VERSION "dbc-export 1 2026.26.6.5"

NS_ :

BS_:

BU_: ADSP APB APP APS APSB BB BMS CC CMP CMPD CP DAS DI DIF DIR DPB EPAS3P EPAS3S EPASTP EPASTS EPBL EPBR ESP EVSE FC GTW HCML HCMR HVP IBST ICR IDB LS OCS1P ODIN PARK PCS PCS2 PLG PM PMF PMR PNCD PTC RADC RCM RCM2 RCM3 RCU SCCM SCM SCS SDCR TAS TCU TCU2 TPMS TRCM UDS UI UIS UMC USM V2G VC VCBATT VCBATT0 VCBATT1 VCBATT2 VCCC VCFRONT VCFRONT1 VCFRONT2 VCLEFT VCRIGHT VCSEAT2L VCSEAT2R VCSEC VEH

BO_ 1482 APSB_alertLog: 8 APSB
 SG_ APSB_alertID M : 0|14@1+ (1,0) [0|16383] "" Vector__XXX
 SG_ APSB_alertSource : 14|1@1+ (1,0) [0|1] "" Vector__XXX
 SG_ APSB_alertState : 15|1@1+ (1,0) [0|1] "" Vector__XXX
 SG_ APSB_sw010_a04calibNotDone m10 : 16|1@1+ (1,0) [0|1] "" Vector__XXX
 SG_ APSB_sw010_a05calibReqd m10 : 17|1@1+ (1,0) [0|1] "" Vector__XXX
 SG_ APSB_sw010_a06calibNotOK m10 : 18|1@1+ (1,0) [0|1] "" Vector__XXX
 SG_ APSB_sw010_a08PlantMode m10 : 19|1@1+ (1,0) [0|1] "" Vector__XXX
 SG_ APSB_sw010_HorizontalMisalignmen m10 : 20|16@1+ (0.00137332,-45) [-45|45.0005262] "deg" Vector__XXX
 SG_ APSB_sw010_VerticalMisalignment m10 : 36|10@1+ (0.087977,-45) [-45|45.000471] "deg" Vector__XXX
 SG_ APSB_sw010_unusedBits m10 : 46|2@1+ (1,0) [0|3] "" Vector__XXX
 SG_ APSB_sw010_VmaPlausibility m10 : 48|16@1+ (1.52587890625e-05,0) [0|0.999984741211] "FIXME" Vector__XXX
 SG_ APSB_sw019_taskId m19 : 16|8@1+ (1,0) [0|255] "" Vector__XXX
 SG_ APSB_sw019_numFreeBytes m19 : 24|8@1+ (1,-191) [-191|64] "# of bytes" Vector__XXX
 SG_ APSB_sw019_timeStamp m19 : 32|32@1+ (1,0) [0|4294967295] "ms" Vector__XXX
 SG_ APSB_sw020_unusedW0 m20 : 16|16@1+ (1,0) [0|65535] "" Vector__XXX
 SG_ APSB_sw020_unusedW1 m20 : 32|16@1+ (1,0) [0|65535] "" Vector__XXX
 SG_ APSB_sw020_unusedW2 m20 : 48|16@1+ (1,0) [0|65535] "" Vector__XXX
 SG_ APSB_sw021_tempSensorId m21 : 16|8@1+ (1,0) [0|255] "" Vector__XXX
 SG_ APSB_sw021_minThreshold m21 : 24|8@1- (1,0) [-128|127] "degC" Vector__XXX
 SG_ APSB_sw021_maxThreshold m21 : 32|8@1- (1,0) [-128|127] "degC" Vector__XXX
 SG_ APSB_sw021_currentTemperature m21 : 40|8@1- (1,0) [-128|127] "degC" Vector__XXX
 SG_ APSB_sw021_unusedWord m21 : 48|16@1+ (1,0) [0|65535] "" Vector__XXX
 SG_ APSB_sw024_Task_ID m24 : 16|4@1+ (1,0) [0|15] "" Vector__XXX
 SG_ APSB_sw024_numVirtualLaneVeh m24 : 20|4@1+ (1,0) [0|15] "" Vector__XXX
 SG_ APSB_sw024_currentVehicleApp m24 : 24|8@1+ (1,0) [0|255] "" Vector__XXX
 SG_ APSB_sw024_taskProgramCounter m24 : 32|32@1+ (1,0) [0|4294967295] "" Vector__XXX
 SG_ APSB_sw027_JTAG_Reset m27 : 16|1@1+ (1,0) [0|1] "" Vector__XXX
 SG_ APSB_sw027_Core_Reset m27 : 17|1@1+ (1,0) [0|1] "" Vector__XXX
 SG_ APSB_sw027_Unused_Bit_0 m27 : 18|1@1+ (1,0) [0|1] "" Vector__XXX
 SG_ APSB_sw027_CPU_Checkstop_Error m27 : 19|1@1+ (1,0) [0|1] "" Vector__XXX
 SG_ APSB_sw027_PLL_0_Failure m27 : 20|1@1+ (1,0) [0|1] "" Vector__XXX
 SG_ APSB_sw027_Clock_Monitor_0_Low m27 : 21|1@1+ (1,0) [0|1] "" Vector__XXX
 SG_ APSB_sw027_Clock_Monitor_0_Off m27 : 22|1@1+ (1,0) [0|1] "" Vector__XXX
 SG_ APSB_sw027_LVD_4v5 m27 : 23|1@1+ (1,0) [0|1] "" Vector__XXX
 SG_ APSB_sw027_Flash_Fatal_Error m27 : 24|1@1+ (1,0) [0|1] "" Vector__XXX
 SG_ APSB_sw027_PLL_1_Failure m27 : 25|1@1+ (1,0) [0|1] "" Vector__XXX
 SG_ APSB_sw027_Unused_Bit_1 m27 : 26|1@1+ (1,0) [0|1] "" Vector__XXX
 SG_ APSB_sw027_f_PLL_1_Off m27 : 27|1@1+ (1,0) [0|1] "" Vector__XXX
 SG_ APSB_sw027_Unused_Nibble m27 : 28|4@1+ (1,0) [0|15] "" Vector__XXX
 SG_ APSB_sw027_LVD_1v2 m27 : 32|1@1+ (1,0) [0|1] "" Vector__XXX
 SG_ APSB_sw027_Unused_Bit_2 m27 : 33|1@1+ (1,0) [0|1] "" Vector__XXX
 SG_ APSB_sw027_Watchdog m27 : 34|1@1+ (1,0) [0|1] "" Vector__XXX
 SG_ APSB_sw027_Unused_Bit_3 m27 : 35|1@1+ (1,0) [0|1] "" Vector__XXX
 SG_ APSB_sw027_LVD_2v7_VREG m27 : 36|1@1+ (1,0) [0|1] "" Vector__XXX
 SG_ APSB_sw027_LVD_2v7_Flash m27 : 37|1@1+ (1,0) [0|1] "" Vector__XXX
 SG_ APSB_sw027_LVD_2v7_IO m27 : 38|1@1+ (1,0) [0|1] "" Vector__XXX
 SG_ APSB_sw027_Unused_Bit_4 m27 : 39|1@1+ (1,0) [0|1] "" Vector__XXX
 SG_ APSB_sw027_Unused_Byte m27 : 40|8@1+ (1,0) [0|255] "" Vector__XXX
 SG_ APSB_sw027_ESR0 m27 : 48|1@1+ (1,0) [0|1] "" Vector__XXX
 SG_ APSB_sw027_ESR1 m27 : 49|1@1+ (1,0) [0|1] "" Vector__XXX
 SG_ APSB_sw027_SW m27 : 50|1@1+ (1,0) [0|1] "" Vector__XXX
 SG_ APSB_sw027_STM0 m27 : 51|1@1+ (1,0) [0|1] "" Vector__XXX
 SG_ APSB_sw027_STM1 m27 : 52|1@1+ (1,0) [0|1] "" Vector__XXX
 SG_ APSB_sw027_STM2 m27 : 53|1@1+ (1,0) [0|1] "" Vector__XXX
 SG_ APSB_sw027_CBS_SYSTEM m27 : 54|1@1+ (1,0) [0|1] "" Vector__XXX
 SG_ APSB_sw027_CBS_DEBUG m27 : 55|1@1+ (1,0) [0|1] "" Vector__XXX
 SG_ APSB_sw027_CBS_APP m27 : 56|1@1+ (1,0) [0|1] "" Vector__XXX
 SG_ APSB_sw027_EVR13 m27 : 57|1@1+ (1,0) [0|1] "" Vector__XXX
 SG_ APSB_sw027_EVR33 m27 : 58|1@1+ (1,0) [0|1] "" Vector__XXX
 SG_ APSB_sw027_SWD m27 : 59|1@1+ (1,0) [0|1] "" Vector__XXX
 SG_ APSB_sw027_STDBY_WDG m27 : 60|1@1+ (1,0) [0|1] "" Vector__XXX
 SG_ APSB_sw027_PORST m27 : 61|1@1+ (1,0) [0|1] "" Vector__XXX
 SG_ APSB_sw027_Unused_word m27 : 62|2@1+ (1,0) [0|3] "" Vector__XXX
 SG_ APSB_sw030_heaterState m30 : 16|8@1+ (1,0) [0|255] "" Vector__XXX
 SG_ APSB_sw030_unusedByte m30 : 24|8@1+ (1,0) [0|255] "" Vector__XXX
 SG_ APSB_sw030_unusedW0 m30 : 32|16@1+ (1,0) [0|65535] "" Vector__XXX
 SG_ APSB_sw030_unusedW1 m30 : 48|16@1+ (1,0) [0|65535] "" Vector__XXX
 SG_ APSB_sw033_carConfig m33 : 16|1@1+ (1,0) [0|1] "" Vector__XXX
 SG_ APSB_sw033_chNm m33 : 17|1@1+ (1,0) [0|1] "" Vector__XXX
 SG_ APSB_sw033_vin m33 : 18|1@1+ (1,0) [0|1] "" Vector__XXX
 SG_ APSB_sw033_carState m33 : 19|1@1+ (1,0) [0|1] "" Vector__XXX
 SG_ APSB_sw034_sccmMia m34 : 16|8@1+ (1,0) [0|255] "" Vector__XXX
 SG_ APSB_sw034_unusedByte m34 : 24|8@1+ (1,0) [0|255] "" Vector__XXX
 SG_ APSB_sw034_unusedW0 m34 : 32|16@1+ (1,0) [0|65535] "" Vector__XXX
 SG_ APSB_sw034_unusedW1 m34 : 48|16@1+ (1,0) [0|65535] "" Vector__XXX
 SG_ APSB_sw035_wheelSpeeds m35 : 16|1@1+ (1,0) [0|1] "" Vector__XXX
 SG_ APSB_sw035_status m35 : 17|1@1+ (1,0) [0|1] "" Vector__XXX
 SG_ APSB_sw035_wheelRotation m35 : 18|1@1+ (1,0) [0|1] "" Vector__XXX
 SG_ APSB_sw035_redundantBrakingStatu m35 : 19|1@1+ (1,0) [0|1] "" Vector__XXX
 SG_ APSB_sw036_bdyMia m36 : 16|8@1+ (1,0) [0|255] "" Vector__XXX
 SG_ APSB_sw036_unusedByte m36 : 24|8@1+ (1,0) [0|255] "" Vector__XXX
 SG_ APSB_sw036_unusedW0 m36 : 32|16@1+ (1,0) [0|65535] "" Vector__XXX
 SG_ APSB_sw036_unusedW1 m36 : 48|16@1+ (1,0) [0|65535] "" Vector__XXX
 SG_ APSB_sw039_sdm_rcm_Mia m39 : 16|8@1+ (1,0) [0|255] "" Vector__XXX
 SG_ APSB_sw039_unusedByte m39 : 24|8@1+ (1,0) [0|255] "" Vector__XXX
 SG_ APSB_sw039_unusedW0 m39 : 32|16@1+ (1,0) [0|65535] "" Vector__XXX
 SG_ APSB_sw039_unusedW1 m39 : 48|16@1+ (1,0) [0|65535] "" Vector__XXX
 SG_ APSB_sw045_radMia m45 : 16|8@1+ (1,0) [0|255] "" Vector__XXX
 SG_ APSB_sw045_unusedByte m45 : 24|8@1+ (1,0) [0|255] "" Vector__XXX
 SG_ APSB_sw045_unusedW0 m45 : 32|16@1+ (1,0) [0|65535] "" Vector__XXX
 SG_ APSB_sw045_unusedW1 m45 : 48|16@1+ (1,0) [0|65535] "" Vector__XXX
 SG_ APSB_sw048_swAssert m48 : 16|1@1+ (1,0) [0|1] "" Vector__XXX
 SG_ APSB_sw048_thermalIssue m48 : 17|1@1+ (1,0) [0|1] "" Vector__XXX
 SG_ APSB_sw048_powerIssue m48 : 18|1@1+ (1,0) [0|1] "" Vector__XXX
 SG_ APSB_sw048_stackOverflow m48 : 19|1@1+ (1,0) [0|1] "" Vector__XXX
 SG_ APSB_sw048_checkStop m48 : 20|1@1+ (1,0) [0|1] "" Vector__XXX
 SG_ APSB_sw048_ecuWatchdog m48 : 21|1@1+ (1,0) [0|1] "" Vector__XXX
 SG_ APSB_sw048_ecuReset m48 : 22|1@1+ (1,0) [0|1] "" Vector__XXX
 SG_ APSB_sw048_radcVersionMismatch m48 : 23|1@1+ (1,0) [0|1] "" Vector__XXX
 SG_ APSB_sw048_radcCalibration m48 : 24|1@1+ (1,0) [0|1] "" Vector__XXX
 SG_ APSB_sw048_radcMia m48 : 25|1@1+ (1,0) [0|1] "" Vector__XXX
 SG_ APSB_sw048_eyeQVersionMismatch m48 : 26|1@1+ (1,0) [0|1] "" Vector__XXX
 SG_ APSB_sw048_camIssue m48 : 27|1@1+ (1,0) [0|1] "" Vector__XXX
 SG_ APSB_sw048_parkerIssue m48 : 28|1@1+ (1,0) [0|1] "" Vector__XXX
 SG_ APSB_sw048_prolongedUiMia m48 : 29|1@1+ (1,0) [0|1] "" Vector__XXX
 SG_ APSB_sw048_uiMiaAtBootup m48 : 30|1@1+ (1,0) [0|1] "" Vector__XXX
 SG_ APSB_sw051_a01ecuInternalPerf m51 : 16|1@1+ (1,0) [0|1] "" Vector__XXX
 SG_ APSB_sw051_a02flashPerformance m51 : 17|1@1+ (1,0) [0|1] "" Vector__XXX
 SG_ APSB_sw051_a03vBatHigh m51 : 18|1@1+ (1,0) [0|1] "" Vector__XXX
 SG_ APSB_sw051_a09configMismatch m51 : 19|1@1+ (1,0) [0|1] "" Vector__XXX
 SG_ APSB_sw051_a52radomeHtrInop m51 : 20|1@1+ (1,0) [0|1] "" Vector__XXX
 SG_ APSB_sw051_unused m51 : 21|3@1+ (1,0) [0|7] "" Vector__XXX
 SG_ APSB_sw051_SCUTemperature m51 : 24|8@1- (1,0) [-128|127] "" Vector__XXX
 SG_ APSB_sw051_HWFail m51 : 32|1@1+ (1,0) [0|1] "" Vector__XXX
 SG_ APSB_sw051_SGUFail m51 : 33|1@1+ (1,0) [0|1] "" Vector__XXX
 SG_ APSB_sw051_unusedBits m51 : 34|6@1+ (1,0) [0|63] "" Vector__XXX
 SG_ APSB_sw051_unusedB0 m51 : 40|8@1+ (1,0) [0|255] "" Vector__XXX
 SG_ APSB_sw051_unusedW1 m51 : 48|16@1+ (1,0) [0|65535] "" Vector__XXX
 SG_ APSB_sw052_a07sensorBlinded m52 : 16|1@1+ (1,0) [0|1] "" Vector__XXX
 SG_ APSB_sw052_sensorDirty m52 : 17|1@1+ (1,0) [0|1] "" Vector__XXX
 SG_ APSB_sw052_HWFail m52 : 18|1@1+ (1,0) [0|1] "" Vector__XXX
 SG_ APSB_sw052_overTemperature m52 : 19|1@1+ (1,0) [0|1] "" Vector__XXX
 SG_ APSB_sw052_underTemperature m52 : 20|1@1+ (1,0) [0|1] "" Vector__XXX
 SG_ APSB_sw052_chirpError m52 : 21|1@1+ (1,0) [0|1] "" Vector__XXX
 SG_ APSB_sw052_rspError m52 : 22|1@1+ (1,0) [0|1] "" Vector__XXX
 SG_ APSB_sw052_sensorBlocked m52 : 23|1@1+ (1,0) [0|1] "" Vector__XXX
 SG_ APSB_sw053_a10canBusOff m53 : 16|1@1+ (1,0) [0|1] "" Vector__XXX
 SG_ APSB_sw053_a11bdyMIA m53 : 17|1@1+ (1,0) [0|1] "" Vector__XXX
 SG_ APSB_sw053_a12espMIA m53 : 18|1@1+ (1,0) [0|1] "" Vector__XXX
 SG_ APSB_sw053_a13gtwMIA m53 : 19|1@1+ (1,0) [0|1] "" Vector__XXX
 SG_ APSB_sw053_a14sccmMIA m53 : 20|1@1+ (1,0) [0|1] "" Vector__XXX
 SG_ APSB_sw053_a15adasMIA m53 : 21|1@1+ (1,0) [0|1] "" Vector__XXX
 SG_ APSB_sw053_a16bdyInvalidCount m53 : 22|1@1+ (1,0) [0|1] "" Vector__XXX
 SG_ APSB_sw053_a17adasInvalidCount m53 : 23|1@1+ (1,0) [0|1] "" Vector__XXX
 SG_ APSB_sw053_a18espInvalidCount m53 : 24|1@1+ (1,0) [0|1] "" Vector__XXX
 SG_ APSB_sw053_a19sccmInvalidCount m53 : 25|1@1+ (1,0) [0|1] "" Vector__XXX
 SG_ APSB_sw053_a20bdyInvalidChkSm m53 : 26|1@1+ (1,0) [0|1] "" Vector__XXX
 SG_ APSB_sw053_a21espInvalidChkSm m53 : 27|1@1+ (1,0) [0|1] "" Vector__XXX
 SG_ APSB_sw053_a22sccmInvalidChkSm m53 : 28|1@1+ (1,0) [0|1] "" Vector__XXX
 SG_ APSB_sw053_a23sccmInvalidChkSm m53 : 29|1@1+ (1,0) [0|1] "" Vector__XXX
 SG_ APSB_sw053_a24absValidity m53 : 30|1@1+ (1,0) [0|1] "" Vector__XXX
 SG_ APSB_sw053_a25ambTValidity m53 : 31|1@1+ (1,0) [0|1] "" Vector__XXX
 SG_ APSB_sw053_a26brakeValidity m53 : 32|1@1+ (1,0) [0|1] "" Vector__XXX
 SG_ APSB_sw053_a27CntryCdValidity m53 : 33|1@1+ (1,0) [0|1] "" Vector__XXX
 SG_ APSB_sw053_a28espValidity m53 : 34|1@1+ (1,0) [0|1] "" Vector__XXX
 SG_ APSB_sw053_a29longAccOffValidity m53 : 35|1@1+ (1,0) [0|1] "" Vector__XXX
 SG_ APSB_sw053_a30longAccValidity m53 : 36|1@1+ (1,0) [0|1] "" Vector__XXX
 SG_ APSB_sw053_a31odoValidity m53 : 37|1@1+ (1,0) [0|1] "" Vector__XXX
 SG_ APSB_sw053_a32gearValidity m53 : 38|1@1+ (1,0) [0|1] "" Vector__XXX
 SG_ APSB_sw053_a33steerAngValidity m53 : 39|1@1+ (1,0) [0|1] "" Vector__XXX
 SG_ APSB_sw053_a34steerAngSpdValidit m53 : 40|1@1+ (1,0) [0|1] "" Vector__XXX
 SG_ APSB_sw053_a35indctrValidity m53 : 41|1@1+ (1,0) [0|1] "" Vector__XXX
 SG_ APSB_sw053_a36vehStndStllValidty m53 : 42|1@1+ (1,0) [0|1] "" Vector__XXX
 SG_ APSB_sw053_a37vinValidity m53 : 43|1@1+ (1,0) [0|1] "" Vector__XXX
 SG_ APSB_sw053_a38whlRotValidity m53 : 44|1@1+ (1,0) [0|1] "" Vector__XXX
 SG_ APSB_sw053_a39whlSpdValidity m53 : 45|1@1+ (1,0) [0|1] "" Vector__XXX
 SG_ APSB_sw053_a40whlStndStllValidty m53 : 46|1@1+ (1,0) [0|1] "" Vector__XXX
 SG_ APSB_sw053_a41wiperValidity m53 : 47|1@1+ (1,0) [0|1] "" Vector__XXX
 SG_ APSB_sw053_a42xwdValidity m53 : 48|1@1+ (1,0) [0|1] "" Vector__XXX
 SG_ APSB_sw053_a43yawOffValidity m53 : 49|1@1+ (1,0) [0|1] "" Vector__XXX
 SG_ APSB_sw053_a44yawValidity m53 : 50|1@1+ (1,0) [0|1] "" Vector__XXX
 SG_ APSB_sw053_a48steerAngOffSanity m53 : 51|1@1+ (1,0) [0|1] "" Vector__XXX
 SG_ APSB_sw053_a49tireSizeSanity m53 : 52|1@1+ (1,0) [0|1] "" Vector__XXX
 SG_ APSB_sw053_a50velocitySanity m53 : 53|1@1+ (1,0) [0|1] "" Vector__XXX
 SG_ APSB_sw053_a51yawSanity m53 : 54|1@1+ (1,0) [0|1] "" Vector__XXX
 SG_ APSB_sw053_a53espmodValidity m53 : 55|1@1+ (1,0) [0|1] "" Vector__XXX
 SG_ APSB_sw053_a54gtwmodValidity m53 : 56|1@1+ (1,0) [0|1] "" Vector__XXX
 SG_ APSB_sw053_a55stwmodValidity m53 : 57|1@1+ (1,0) [0|1] "" Vector__XXX
 SG_ APSB_sw053_a56bcmodValidity m53 : 58|1@1+ (1,0) [0|1] "" Vector__XXX
 SG_ APSB_sw053_a57dimodValidity m53 : 59|1@1+ (1,0) [0|1] "" Vector__XXX
 SG_ APSB_sw053_a59drmiInvalidChkSm m53 : 60|1@1+ (1,0) [0|1] "" Vector__XXX
 SG_ APSB_sw053_a60drmiInvalidCount m53 : 61|1@1+ (1,0) [0|1] "" Vector__XXX
 SG_ APSB_sw053_a61radPositionMismatc m53 : 62|1@1+ (1,0) [0|1] "" Vector__XXX
 SG_ APSB_sw053_a62strRackMismatch m53 : 63|1@1+ (1,0) [0|1] "" Vector__XXX
 SG_ APSB_sw055_detectedRadcVersion m55 : 16|32@1+ (1,0) [0|4294967295] "" Vector__XXX
 SG_ APSB_sw055_expectedCrcLsw m55 : 48|16@1+ (1,0) [0|65535] "" Vector__XXX
 SG_ APSB_sw056_diMia m56 : 16|8@1+ (1,0) [0|255] "" Vector__XXX
 SG_ APSB_sw056_unusedByte m56 : 24|8@1+ (1,0) [0|255] "" Vector__XXX
 SG_ APSB_sw056_unusedW0 m56 : 32|16@1+ (1,0) [0|65535] "" Vector__XXX
 SG_ APSB_sw056_unusedW1 m56 : 48|16@1+ (1,0) [0|65535] "" Vector__XXX
 SG_ APSB_sw058_epbMia m58 : 16|8@1+ (1,0) [0|255] "" Vector__XXX
 SG_ APSB_sw058_unusedByte m58 : 24|8@1+ (1,0) [0|255] "" Vector__XXX
 SG_ APSB_sw058_unusedW0 m58 : 32|16@1+ (1,0) [0|65535] "" Vector__XXX
 SG_ APSB_sw058_unusedW1 m58 : 48|16@1+ (1,0) [0|65535] "" Vector__XXX
 SG_ APSB_sw059_sdiFront m59 : 16|1@1+ (1,0) [0|1] "" Vector__XXX
 SG_ APSB_sw059_sdiRear m59 : 17|1@1+ (1,0) [0|1] "" Vector__XXX
 SG_ APSB_sw059_status m59 : 18|1@1+ (1,0) [0|1] "" Vector__XXX
 SG_ APSB_sw059_sensorStatusFront m59 : 19|1@1+ (1,0) [0|1] "" Vector__XXX
 SG_ APSB_sw059_pasFrontMiddle m59 : 20|1@1+ (1,0) [0|1] "" Vector__XXX
 SG_ APSB_sw059_sensorStatusRear m59 : 21|1@1+ (1,0) [0|1] "" Vector__XXX
 SG_ APSB_sw059_pasRearMiddle m59 : 22|1@1+ (1,0) [0|1] "" Vector__XXX
 SG_ APSB_sw059_pscStatus m59 : 23|1@1+ (1,0) [0|1] "" Vector__XXX
 SG_ APSB_sw059_pscVehSlot m59 : 24|1@1+ (1,0) [0|1] "" Vector__XXX
 SG_ APSB_sw059_status2 m59 : 25|1@1+ (1,0) [0|1] "" Vector__XXX
 SG_ APSB_sw059_oloDict m59 : 26|1@1+ (1,0) [0|1] "" Vector__XXX
 SG_ APSB_sw059_oocStatus m59 : 27|1@1+ (1,0) [0|1] "" Vector__XXX
 SG_ APSB_sw061_states m61 : 16|1@1+ (1,0) [0|1] "" Vector__XXX
 SG_ APSB_sw063_expectedMajorVer m63 : 16|8@1+ (1,0) [0|255] "" Vector__XXX
 SG_ APSB_sw063_detectedMajorVer m63 : 24|8@1+ (1,0) [0|255] "" Vector__XXX
 SG_ APSB_sw063_expectedMinorVer m63 : 32|8@1+ (1,0) [0|255] "" Vector__XXX
 SG_ APSB_sw063_detectedMinorVer m63 : 40|8@1+ (1,0) [0|255] "" Vector__XXX
 SG_ APSB_sw063_expectedSubMinorVer m63 : 48|8@1+ (1,0) [0|255] "" Vector__XXX
 SG_ APSB_sw063_detectedSubMinorVer m63 : 56|8@1+ (1,0) [0|255] "" Vector__XXX
 SG_ APSB_sw064_sysStatus m64 : 16|1@1+ (1,0) [0|1] "" Vector__XXX
 SG_ APSB_sw064_status m64 : 17|1@1+ (1,0) [0|1] "" Vector__XXX
 SG_ APSB_sw070_currTireFitment m70 : 16|3@1+ (1,0) [0|7] "" Vector__XXX
 SG_ APSB_sw070_lastTireFitment m70 : 19|3@1+ (1,0) [0|7] "" Vector__XXX
 SG_ APSB_sw070_diGear m70 : 24|3@1+ (1,0) [0|7] "" Vector__XXX
 SG_ APSB_sw070_driveRail m70 : 27|1@1+ (1,0) [0|1] "" Vector__XXX
 SG_ APSB_sw070_accRail m70 : 28|1@1+ (1,0) [0|1] "" Vector__XXX
 SG_ APSB_sw070_temperature m70 : 32|8@1+ (0.5,-40) [-40|87.5] "C" Vector__XXX
 SG_ APSB_sw070_currentSpeed m70 : 40|12@1+ (0.1,-204.7) [-204.7|204.8] "mph" Vector__XXX
 SG_ APSB_sw071_selfParkType m71 : 16|4@1+ (1,0) [0|15] "" Vector__XXX
 SG_ APSB_sw071_endPosX m71 : 20|10@1+ (0.05,-25.6) [-25.6|25.55] "m" Vector__XXX
 SG_ APSB_sw071_endPosY m71 : 30|10@1+ (0.05,-25.6) [-25.6|25.55] "m" Vector__XXX
 SG_ APSB_sw071_roadClass m71 : 40|3@1+ (1,0) [0|7] "" Vector__XXX
 SG_ APSB_sw071_driverPresent m71 : 43|1@1+ (1,0) [0|1] "" Vector__XXX
 SG_ APSB_sw071_airSuspension m71 : 44|3@1+ (1,0) [0|7] "" Vector__XXX
 SG_ APSB_sw071_temperature m71 : 48|8@1+ (0.5,-40) [-40|87.5] "C" Vector__XXX
 SG_ APSB_sw071_activationType m71 : 56|2@1+ (1,0) [0|3] "" Vector__XXX
 SG_ APSB_sw072_vehicleX m72 : 16|10@1+ (0.05,-25.6) [-25.6|25.55] "m" Vector__XXX
 SG_ APSB_sw072_vehicleY m72 : 26|10@1+ (0.05,-25.6) [-25.6|25.55] "m" Vector__XXX
 SG_ APSB_sw072_vehicleHeading m72 : 36|10@1+ (0.005,-2.56) [-2.56|2.555] "rad" Vector__XXX
 SG_ APSB_sw072_endDistance m72 : 48|8@1+ (1,0) [0|255] "cm" Vector__XXX
 SG_ APSB_sw072_guidanceComplete m72 : 56|1@1+ (1,0) [0|1] "" Vector__XXX
 SG_ APSB_sw072_guidanceRunaway m72 : 57|1@1+ (1,0) [0|1] "" Vector__XXX
 SG_ APSB_sw072_guidanceTimer m72 : 58|1@1+ (1,0) [0|1] "" Vector__XXX
 SG_ APSB_sw072_handlePress m72 : 59|1@1+ (1,0) [0|1] "" Vector__XXX
 SG_ APSB_sw072_keyfobPress m72 : 60|1@1+ (1,0) [0|1] "" Vector__XXX
 SG_ APSB_sw072_garageOpened m72 : 61|1@1+ (1,0) [0|1] "" Vector__XXX
 SG_ APSB_sw072_userTimeout m72 : 62|1@1+ (1,0) [0|1] "" Vector__XXX
 SG_ APSB_sw075_scMia m75 : 16|8@1+ (1,0) [0|255] "" Vector__XXX
 SG_ APSB_sw075_unusedByte m75 : 24|8@1+ (1,0) [0|255] "" Vector__XXX
 SG_ APSB_sw075_unusedW0 m75 : 32|16@1+ (1,0) [0|65535] "" Vector__XXX
 SG_ APSB_sw075_unusedW1 m75 : 48|16@1+ (1,0) [0|65535] "" Vector__XXX
 SG_ APSB_sw077_oocDistance m77 : 16|9@1+ (1,0) [0|511] "cm" Vector__XXX
 SG_ APSB_sw077_oocConfidence m77 : 25|7@1+ (1,0) [0|127] "%" Vector__XXX
 SG_ APSB_sw077_oocCollisionSide m77 : 32|3@1+ (1,0) [0|7] "" Vector__XXX
 SG_ APSB_sw077_oocHeight m77 : 35|2@1+ (1,0) [0|3] "" Vector__XXX
 SG_ APSB_sw077_vehicleSpeed m77 : 37|10@1+ (0.05,-25) [-25|26.15] "MPH" Vector__XXX
 SG_ APSB_sw077_oocUntrackedTime m77 : 48|6@1+ (0.1,0) [0|6.3] "s" Vector__XXX
 SG_ APSB_sw077_oocOffCourseDist_cm m77 : 54|10@1- (1,0) [-512|511] "" Vector__XXX
 SG_ APSB_sw081_radarDistance m81 : 16|8@1+ (0.0625,0) [0|15.9375] "m" Vector__XXX
 SG_ APSB_sw081_radarTTC m81 : 24|8@1+ (0.02,0) [0|5.1] "seconds" Vector__XXX
 SG_ APSB_sw081_cameraDistance m81 : 32|8@1+ (0.0625,0) [0|15.9375] "m" Vector__XXX
 SG_ APSB_sw081_cameraTTC m81 : 40|8@1+ (0.02,0) [0|5.1] "seconds" Vector__XXX
 SG_ APSB_sw081_pedalPosition m81 : 48|7@1+ (1,0) [0|127] "%" Vector__XXX
 SG_ APSB_sw129_currentVoltage m129 : 16|14@1+ (1,0) [0|16383] "mV" Vector__XXX
 SG_ APSB_sw129_maxThreshold m129 : 30|13@1+ (1,50) [50|8241] "mV" Vector__XXX
 SG_ APSB_sw129_minThreshold m129 : 43|13@1+ (1,0) [0|8191] "mV" Vector__XXX
 SG_ APSB_sw129_powerSequnceError m129 : 56|1@1+ (1,0) [0|1] "" Vector__XXX
 SG_ APSB_sw129_railControl m129 : 57|1@1+ (1,0) [0|1] "" Vector__XXX
 SG_ APSB_sw129_railID m129 : 58|6@1+ (1,0) [0|63] "" Vector__XXX
 SG_ APSB_sw130_currentTemperature m130 : 16|8@1- (1,0) [-128|127] "degC" Vector__XXX
 SG_ APSB_sw130_maxThreshold m130 : 24|8@1- (1,0) [-128|127] "degC" Vector__XXX
 SG_ APSB_sw130_minThreshold m130 : 32|8@1- (1,0) [-128|127] "degC" Vector__XXX
 SG_ APSB_sw130_tempSensorId m130 : 40|6@1+ (1,0) [0|63] "" Vector__XXX
 SG_ APSB_sw130_shouldForceApPowerOn m130 : 46|1@1+ (1,0) [0|1] "" Vector__XXX
 SG_ APSB_sw130_shouldBlockOkToPowerA m130 : 47|1@1+ (1,0) [0|1] "" Vector__XXX
 SG_ APSB_sw132_mismatchType m132 : 16|1@1+ (1,0) [0|1] "" Vector__XXX
 SG_ APSB_sw132_actualHash m132 : 24|24@1+ (1,0) [0|16777215] "" Vector__XXX
 SG_ APSB_sw132_expectedHash m132 : 48|16@1+ (1,0) [0|65535] "" Vector__XXX
 SG_ APSB_sw133_failedInitStep m133 : 16|8@1+ (1,0) [0|255] "" Vector__XXX
 SG_ APSB_sw133_switchInReset m133 : 24|1@1+ (1,0) [0|1] "" Vector__XXX
 SG_ APSB_sw133_phyIsNotRMIIMode m133 : 25|1@1+ (1,0) [0|1] "" Vector__XXX
 SG_ APSB_sw133_phyInterruptStorm m133 : 26|1@1+ (1,0) [0|1] "" Vector__XXX
 SG_ APSB_sw133_switchEthernetInterLi m133 : 27|1@1+ (1,0) [0|1] "" Vector__XXX
 SG_ APSB_sw133_ethSwitchReadFwVerFai m133 : 28|1@1+ (1,0) [0|1] "" Vector__XXX
 SG_ APSB_sw133_ethSwitchFailedToBoot m133 : 29|1@1+ (1,0) [0|1] "" Vector__XXX
 SG_ APSB_sw133_ethSwitchTimedoutUpda m133 : 30|1@1+ (1,0) [0|1] "" Vector__XXX
 SG_ APSB_sw133_ethSwitchMcuLinkFailo m133 : 31|1@1+ (1,0) [0|1] "" Vector__XXX
 SG_ APSB_sw133_ethSwitchMcuLinkDupli m133 : 32|1@1+ (1,0) [0|1] "" Vector__XXX
 SG_ APSB_sw133_ethSwitchMcuLinkDisco m133 : 33|1@1+ (1,0) [0|1] "" Vector__XXX
 SG_ APSB_sw133_unused m133 : 34|30@1+ (1,0) [0|1073741823] "" Vector__XXX
 SG_ APSB_sw134_appCamCalibStatus m134 : 16|1@1+ (1,0) [0|1] "" Vector__XXX
 SG_ APSB_sw134_appCameraLux m134 : 17|1@1+ (1,0) [0|1] "" Vector__XXX
 SG_ APSB_sw134_appInfo m134 : 18|1@1+ (1,0) [0|1] "" Vector__XXX
 SG_ APSB_sw134_appStatus m134 : 19|1@1+ (1,0) [0|1] "" Vector__XXX
 SG_ APSB_sw134_dasAutonomyControlPar m134 : 20|1@1+ (1,0) [0|1] "" Vector__XXX
 SG_ APSB_sw134_dasAutonomyControlVeh m134 : 21|1@1+ (1,0) [0|1] "" Vector__XXX
 SG_ APSB_sw134_dasBodyControlsVEH m134 : 22|1@1+ (1,0) [0|1] "" Vector__XXX
 SG_ APSB_sw134_dasControl m134 : 23|1@1+ (1,0) [0|1] "" Vector__XXX
 SG_ APSB_sw134_dasControlPty m134 : 24|1@1+ (1,0) [0|1] "" Vector__XXX
 SG_ APSB_sw134_dasIntSafetyFrontPty m134 : 25|1@1+ (1,0) [0|1] "" Vector__XXX
 SG_ APSB_sw134_dasLanes m134 : 26|1@1+ (1,0) [0|1] "" Vector__XXX
 SG_ APSB_sw134_dasObject m134 : 27|1@1+ (1,0) [0|1] "" Vector__XXX
 SG_ APSB_sw134_dasPscControl m134 : 28|1@1+ (1,0) [0|1] "" Vector__XXX
 SG_ APSB_sw134_dasStatus m134 : 29|1@1+ (1,0) [0|1] "" Vector__XXX
 SG_ APSB_sw134_dasStatus2 m134 : 30|1@1+ (1,0) [0|1] "" Vector__XXX
 SG_ APSB_sw134_dasSteeringControl m134 : 31|1@1+ (1,0) [0|1] "" Vector__XXX
 SG_ APSB_sw134_dasVisualDebug m134 : 32|1@1+ (1,0) [0|1] "" Vector__XXX
 SG_ APSB_sw134_dasSteeringControlPty m134 : 33|1@1+ (1,0) [0|1] "" Vector__XXX
 SG_ APSB_sw134_dasChNm m134 : 34|1@1+ (1,0) [0|1] "" Vector__XXX
 SG_ APSB_sw134_appSummon m134 : 35|1@1+ (1,0) [0|1] "" Vector__XXX
 SG_ APSB_sw134_appEnvironment m134 : 36|1@1+ (1,0) [0|1] "" Vector__XXX
 SG_ APSB_sw134_dasStatusPty m134 : 37|1@1+ (1,0) [0|1] "" Vector__XXX
 SG_ APSB_sw134_dasStatus2Pty m134 : 38|1@1+ (1,0) [0|1] "" Vector__XXX
 SG_ APSB_sw134_dasMatrixHighBeamRqVE m134 : 39|1@1+ (1,0) [0|1] "" Vector__XXX
 SG_ APSB_sw134_dasMatrixBendAngleRqP m134 : 40|1@1+ (1,0) [0|1] "" Vector__XXX
 SG_ APSB_sw134_dasBodyControls2VEH m134 : 41|1@1+ (1,0) [0|1] "" Vector__XXX
 SG_ APSB_sw134_dasRedundantBrakingCo m134 : 42|1@1+ (1,0) [0|1] "" Vector__XXX
 SG_ APSB_sw134_dasRedundantBrak_0001 m134 : 43|1@1+ (1,0) [0|1] "" Vector__XXX
 SG_ APSB_sw134_timeSinceLastMsg m134 : 48|16@1+ (1,0) [0|65535] "" Vector__XXX
 SG_ APSB_sw135_appCriticalReason m135 : 16|4@1+ (1,0) [0|15] "" Vector__XXX
 SG_ APSB_sw135_appTimesyncStatus m135 : 24|32@1+ (1,0) [0|4294967295] "" Vector__XXX
 SG_ APSB_sw136_gpsCommIrrecoverable m136 : 16|1@1+ (1,0) [0|1] "" Vector__XXX
 SG_ APSB_sw136_fusionIrrecoverable m136 : 17|1@1+ (1,0) [0|1] "" Vector__XXX
 SG_ APSB_sw136_antennaUnplugged m136 : 18|1@1+ (1,0) [0|1] "" Vector__XXX
 SG_ APSB_sw136_badgpsfix m136 : 19|1@1+ (1,0) [0|1] "" Vector__XXX
 SG_ APSB_sw137_gpsCommMissing m137 : 16|1@1+ (1,0) [0|1] "" Vector__XXX
 SG_ APSB_sw137_gpsJunkData m137 : 17|1@1+ (1,0) [0|1] "" Vector__XXX
 SG_ APSB_sw137_gpsNMEAmissing m137 : 18|1@1+ (1,0) [0|1] "" Vector__XXX
 SG_ APSB_sw137_gpsUBXmissing m137 : 19|1@1+ (1,0) [0|1] "" Vector__XXX
 SG_ APSB_sw137_fusionModeDisabled m137 : 20|1@1+ (1,0) [0|1] "" Vector__XXX
 SG_ APSB_sw137_gpsCfgFail m137 : 21|1@1+ (1,0) [0|1] "" Vector__XXX
 SG_ APSB_sw137_esfStatusMsgMIA m137 : 22|1@1+ (1,0) [0|1] "" Vector__XXX
 SG_ APSB_sw137_wheelTickCfgMissmatch m137 : 23|1@1+ (1,0) [0|1] "" Vector__XXX
 SG_ APSB_sw137_exitTransportMode m137 : 24|1@1+ (1,0) [0|1] "" Vector__XXX
 SG_ APSB_sw137_satRejectionTimeout m137 : 25|1@1+ (1,0) [0|1] "" Vector__XXX
 SG_ APSB_sw137_gpsPPSMissing m137 : 26|1@1+ (1,0) [0|1] "" Vector__XXX
 SG_ APSB_sw138_cfgBufNull m138 : 16|1@1+ (1,0) [0|1] "" Vector__XXX
 SG_ APSB_sw138_invalidID m138 : 17|1@1+ (1,0) [0|1] "" Vector__XXX
 SG_ APSB_sw138_gpsBufferOverflow m138 : 18|1@1+ (1,0) [0|1] "" Vector__XXX
 SG_ APSB_sw138_navx5CfgFailed m138 : 19|1@1+ (1,0) [0|1] "" Vector__XXX
 SG_ APSB_sw138_mcuNMEAmsgUDPinvalid m138 : 20|1@1+ (1,0) [0|1] "" Vector__XXX
 SG_ APSB_sw138_mcuDbgMsgInvalid m138 : 21|1@1+ (1,0) [0|1] "" Vector__XXX
 SG_ APSB_sw138_mcuDbgMsgTooBig m138 : 22|1@1+ (1,0) [0|1] "" Vector__XXX
 SG_ APSB_sw138_mcuFwdNMEAfail m138 : 23|1@1+ (1,0) [0|1] "" Vector__XXX
 SG_ APSB_sw138_NMEAinvalidChecksum m138 : 24|1@1+ (1,0) [0|1] "" Vector__XXX
 SG_ APSB_sw138_unexpectedNMEAmsg m138 : 25|1@1+ (1,0) [0|1] "" Vector__XXX
 SG_ APSB_sw138_UARTbusFull m138 : 26|1@1+ (1,0) [0|1] "" Vector__XXX
 SG_ APSB_sw138_UARTframeError m138 : 27|1@1+ (1,0) [0|1] "" Vector__XXX
 SG_ APSB_sw138_UBXrxFrameTooBig m138 : 28|1@1+ (1,0) [0|1] "" Vector__XXX
 SG_ APSB_sw138_emptyValidNMEA m138 : 29|1@1+ (1,0) [0|1] "" Vector__XXX
 SG_ APSB_sw138_invalidAsciiNMEA m138 : 30|1@1+ (1,0) [0|1] "" Vector__XXX
 SG_ APSB_sw138_wheeltickUARTfault m138 : 31|1@1+ (1,0) [0|1] "" Vector__XXX
 SG_ APSB_sw138_baudrateMismatch m138 : 32|1@1+ (1,0) [0|1] "" Vector__XXX
 SG_ APSB_sw138_wheelTickInvalidSrc m138 : 33|1@1+ (1,0) [0|1] "" Vector__XXX
 SG_ APSB_sw138_UARTparityError m138 : 34|1@1+ (1,0) [0|1] "" Vector__XXX
 SG_ APSB_sw138_UARTrxFifoOverflow m138 : 35|1@1+ (1,0) [0|1] "" Vector__XXX
 SG_ APSB_sw138_UARTrxFifoUnderflow m138 : 36|1@1+ (1,0) [0|1] "" Vector__XXX
 SG_ APSB_sw138_UARTtxFifoOverflow m138 : 37|1@1+ (1,0) [0|1] "" Vector__XXX
 SG_ APSB_sw138_esfWtMsgTimeout m138 : 38|1@1+ (1,0) [0|1] "" Vector__XXX
 SG_ APSB_sw138_PFLASHReadError m138 : 39|1@1+ (1,0) [0|1] "" Vector__XXX
 SG_ APSB_sw138_PFLASHWriteError m138 : 40|1@1+ (1,0) [0|1] "" Vector__XXX
 SG_ APSB_sw138_gpsCfgNack m138 : 41|1@1+ (1,0) [0|1] "" Vector__XXX
 SG_ APSB_sw138_gpsCfgIdFail m138 : 42|6@1+ (1,0) [0|63] "" Vector__XXX
 SG_ APSB_sw138_gpsSetCfgNoAck m138 : 48|1@1+ (1,0) [0|1] "" Vector__XXX
 SG_ APSB_sw138_gpsReadCfgNoResponse m138 : 49|1@1+ (1,0) [0|1] "" Vector__XXX
 SG_ APSB_sw138_ubxErrorReported m138 : 50|1@1+ (1,0) [0|1] "" Vector__XXX
 SG_ APSB_sw140_lvPowerState m140 : 16|1@1+ (1,0) [0|1] "" Vector__XXX
 SG_ APSB_sw140_vehicleStatus m140 : 17|1@1+ (1,0) [0|1] "" Vector__XXX
 SG_ APSB_sw140_status m140 : 18|1@1+ (1,0) [0|1] "" Vector__XXX
 SG_ APSB_sw140_lighting m140 : 19|1@1+ (1,0) [0|1] "" Vector__XXX
 SG_ APSB_sw140_sensors m140 : 20|1@1+ (1,0) [0|1] "" Vector__XXX
 SG_ APSB_sw140_coolant m140 : 21|1@1+ (1,0) [0|1] "" Vector__XXX
 SG_ APSB_sw140_okToUseHighPower m140 : 22|1@1+ (1,0) [0|1] "" Vector__XXX
 SG_ APSB_sw141_inertial1 m141 : 16|1@1+ (1,0) [0|1] "" Vector__XXX
 SG_ APSB_sw141_inertial2 m141 : 17|1@1+ (1,0) [0|1] "" Vector__XXX
 SG_ APSB_sw142_speed m142 : 16|1@1+ (1,0) [0|1] "" Vector__XXX
 SG_ APSB_sw142_locStatus m142 : 17|1@1+ (1,0) [0|1] "" Vector__XXX
 SG_ APSB_sw142_locStatus2 m142 : 18|1@1+ (1,0) [0|1] "" Vector__XXX
 SG_ APSB_sw142_systemStatus m142 : 19|1@1+ (1,0) [0|1] "" Vector__XXX
 SG_ APSB_sw142_chassisControl m142 : 20|1@1+ (1,0) [0|1] "" Vector__XXX
 SG_ APSB_sw142_epbStatus m142 : 21|1@1+ (1,0) [0|1] "" Vector__XXX
 SG_ APSB_sw142_brakeSystem m142 : 22|1@1+ (1,0) [0|1] "" Vector__XXX
 SG_ APSB_sw143_status m143 : 16|1@1+ (1,0) [0|1] "" Vector__XXX
 SG_ APSB_sw143_wheelRotation m143 : 17|1@1+ (1,0) [0|1] "" Vector__XXX
 SG_ APSB_sw143_wheelSpeeds m143 : 18|1@1+ (1,0) [0|1] "" Vector__XXX
 SG_ APSB_sw143_redundantBrakingStatu m143 : 19|1@1+ (1,0) [0|1] "" Vector__XXX
 SG_ APSB_sw144_restraintStatus m144 : 16|1@1+ (1,0) [0|1] "" Vector__XXX
 SG_ APSB_sw145_restraintStatus m145 : 16|1@1+ (1,0) [0|1] "" Vector__XXX
 SG_ APSB_sw146_sysStatus m146 : 16|1@1+ (1,0) [0|1] "" Vector__XXX
 SG_ APSB_sw146_status m146 : 17|1@1+ (1,0) [0|1] "" Vector__XXX
 SG_ APSB_sw147_doorStatus m147 : 16|1@1+ (1,0) [0|1] "" Vector__XXX
 SG_ APSB_sw147_switchStatus m147 : 17|1@1+ (1,0) [0|1] "" Vector__XXX
 SG_ APSB_sw148_doorStatus m148 : 16|1@1+ (1,0) [0|1] "" Vector__XXX
 SG_ APSB_sw148_hvacStatus m148 : 17|1@1+ (1,0) [0|1] "" Vector__XXX
 SG_ APSB_sw149_status m149 : 16|1@1+ (1,0) [0|1] "" Vector__XXX
 SG_ APSB_sw150_steeringAngleSensor m150 : 16|1@1+ (1,0) [0|1] "" Vector__XXX
 SG_ APSB_sw150_rightStalk m150 : 17|1@1+ (1,0) [0|1] "" Vector__XXX
 SG_ APSB_sw150_leftStalk m150 : 18|1@1+ (1,0) [0|1] "" Vector__XXX
 SG_ APSB_sw153_eacInhibitReason m153 : 16|4@1+ (1,0) [0|15] "" Vector__XXX
 SG_ APSB_sw153_eacInternalState m153 : 20|3@1+ (1,0) [0|7] "" Vector__XXX
 SG_ APSB_sw155_InUnicastError m155 : 16|1@1+ (1,0) [0|1] "" Vector__XXX
 SG_ APSB_sw155_UDPRecvError m155 : 17|1@1+ (1,0) [0|1] "" Vector__XXX
 SG_ APSB_sw155_UDPMiscError m155 : 18|1@1+ (1,0) [0|1] "" Vector__XXX
 SG_ APSB_sw155_UDPRTEError m155 : 19|1@1+ (1,0) [0|1] "" Vector__XXX
 SG_ APSB_sw155_UDPCheckError m155 : 20|1@1+ (1,0) [0|1] "" Vector__XXX
 SG_ APSB_sw155_UDPDropError m155 : 21|1@1+ (1,0) [0|1] "" Vector__XXX
 SG_ APSB_sw155_UDPMemError m155 : 22|1@1+ (1,0) [0|1] "" Vector__XXX
 SG_ APSB_sw155_UDPProtoError m155 : 23|1@1+ (1,0) [0|1] "" Vector__XXX
 SG_ APSB_sw155_IPRecvError m155 : 24|1@1+ (1,0) [0|1] "" Vector__XXX
 SG_ APSB_sw155_IPMiscError m155 : 25|1@1+ (1,0) [0|1] "" Vector__XXX
 SG_ APSB_sw155_IPRTEError m155 : 26|1@1+ (1,0) [0|1] "" Vector__XXX
 SG_ APSB_sw155_IPCheckError m155 : 27|1@1+ (1,0) [0|1] "" Vector__XXX
 SG_ APSB_sw155_IPMemError m155 : 28|1@1+ (1,0) [0|1] "" Vector__XXX
 SG_ APSB_sw155_IPDropError m155 : 29|1@1+ (1,0) [0|1] "" Vector__XXX
 SG_ APSB_sw155_IPProtoError m155 : 30|1@1+ (1,0) [0|1] "" Vector__XXX
 SG_ APSB_sw158_apbInfo m158 : 16|1@1+ (1,0) [0|1] "" Vector__XXX
 SG_ APSB_sw158_apbStatus m158 : 17|1@1+ (1,0) [0|1] "" Vector__XXX
 SG_ APSB_sw158_dasAutonomyControlPar m158 : 18|1@1+ (1,0) [0|1] "" Vector__XXX
 SG_ APSB_sw158_dasAutonomyControlVeh m158 : 19|1@1+ (1,0) [0|1] "" Vector__XXX
 SG_ APSB_sw158_dasBodyControlsVEH m158 : 20|1@1+ (1,0) [0|1] "" Vector__XXX
 SG_ APSB_sw158_dasControl m158 : 21|1@1+ (1,0) [0|1] "" Vector__XXX
 SG_ APSB_sw158_dasControlPty m158 : 22|1@1+ (1,0) [0|1] "" Vector__XXX
 SG_ APSB_sw158_dasIntSafetyFrontPty m158 : 23|1@1+ (1,0) [0|1] "" Vector__XXX
 SG_ APSB_sw158_dasLanes m158 : 24|1@1+ (1,0) [0|1] "" Vector__XXX
 SG_ APSB_sw158_dasObject m158 : 25|1@1+ (1,0) [0|1] "" Vector__XXX
 SG_ APSB_sw158_dasPscControl m158 : 26|1@1+ (1,0) [0|1] "" Vector__XXX
 SG_ APSB_sw158_dasStatus m158 : 27|1@1+ (1,0) [0|1] "" Vector__XXX
 SG_ APSB_sw158_dasStatus2 m158 : 28|1@1+ (1,0) [0|1] "" Vector__XXX
 SG_ APSB_sw158_dasSteeringControl m158 : 29|1@1+ (1,0) [0|1] "" Vector__XXX
 SG_ APSB_sw158_dasVisualDebug m158 : 30|1@1+ (1,0) [0|1] "" Vector__XXX
 SG_ APSB_sw158_dasSteeringControlPty m158 : 31|1@1+ (1,0) [0|1] "" Vector__XXX
 SG_ APSB_sw158_dasChNm m158 : 32|1@1+ (1,0) [0|1] "" Vector__XXX
 SG_ APSB_sw158_dasStatusPty m158 : 33|1@1+ (1,0) [0|1] "" Vector__XXX
 SG_ APSB_sw158_dasStatus2Pty m158 : 34|1@1+ (1,0) [0|1] "" Vector__XXX
 SG_ APSB_sw158_dasMatrixHighBeamRqVE m158 : 35|1@1+ (1,0) [0|1] "" Vector__XXX
 SG_ APSB_sw158_dasMatrixBendAngleRqP m158 : 36|1@1+ (1,0) [0|1] "" Vector__XXX
 SG_ APSB_sw158_dasBodyControls2VEH m158 : 37|1@1+ (1,0) [0|1] "" Vector__XXX
 SG_ APSB_sw158_dasRedundantBrakingCo m158 : 38|1@1+ (1,0) [0|1] "" Vector__XXX
 SG_ APSB_sw158_dasRedundantBrak_0001 m158 : 39|1@1+ (1,0) [0|1] "" Vector__XXX
 SG_ APSB_sw158_timeSinceLastMsg m158 : 40|24@1+ (1,0) [0|16777215] "" Vector__XXX
 SG_ APSB_sw159_apbCriticalReason m159 : 16|4@1+ (1,0) [0|15] "" Vector__XXX
 SG_ APSB_sw159_apbTimesyncStatus m159 : 24|32@1+ (1,0) [0|4294967295] "" Vector__XXX
 SG_ APSB_sw160_mismatchType m160 : 16|1@1+ (1,0) [0|1] "" Vector__XXX
 SG_ APSB_sw160_actualHash m160 : 24|24@1+ (1,0) [0|16777215] "" Vector__XXX
 SG_ APSB_sw160_expectedHash m160 : 48|16@1+ (1,0) [0|65535] "" Vector__XXX
 SG_ APSB_sw161_antennaDisconnected m161 : 16|1@1+ (1,0) [0|1] "" Vector__XXX
 SG_ APSB_sw172_prolongedUiMia m172 : 16|1@1+ (1,0) [0|1] "" Vector__XXX
 SG_ APSB_sw172_uiMiaAtBootup m172 : 17|1@1+ (1,0) [0|1] "" Vector__XXX
 SG_ APSB_sw188_otherTurbo m188 : 16|2@1+ (1,0) [0|3] "" Vector__XXX
 SG_ APSB_sw188_arbUartMiaState m188 : 18|1@1+ (1,0) [0|1] "" Vector__XXX
 SG_ APSB_sw188_powerUartMiaState m188 : 19|1@1+ (1,0) [0|1] "" Vector__XXX
 SG_ APSB_sw188_faultsUartMiaState m188 : 20|1@1+ (1,0) [0|1] "" Vector__XXX
 SG_ APSB_sw188_sleepUartMiaState m188 : 21|1@1+ (1,0) [0|1] "" Vector__XXX
 SG_ APSB_sw188_resetUartMiaState m188 : 22|1@1+ (1,0) [0|1] "" Vector__XXX
 SG_ APSB_sw188_statMonUartMiaState m188 : 23|1@1+ (1,0) [0|1] "" Vector__XXX
 SG_ APSB_sw188_wdogStateUartMiaState m188 : 24|1@1+ (1,0) [0|1] "" Vector__XXX
 SG_ APSB_sw188_critReasUartMiaState m188 : 25|1@1+ (1,0) [0|1] "" Vector__XXX
 SG_ APSB_sw189_AP_vehicleState10Hz m189 : 16|1@1+ (1,0) [0|1] "" Vector__XXX
 SG_ APSB_sw189_AP_vehicleState1Hz m189 : 17|1@1+ (1,0) [0|1] "" Vector__XXX
 SG_ APSB_sw190_IBST_status m190 : 16|1@1+ (1,0) [0|1] "" Vector__XXX
 SG_ APSB_sw192_CANbus m192 : 16|3@1+ (1,0) [0|7] "" Vector__XXX
 SG_ APSB_sw192_SWTxQueueFull m192 : 19|1@1+ (1,0) [0|1] "" Vector__XXX
 SG_ APSB_sw192_Busoff m192 : 20|1@1+ (1,0) [0|1] "" Vector__XXX
 SG_ APSB_sw192_UncorrectedBitError m192 : 21|1@1+ (1,0) [0|1] "" Vector__XXX
 SG_ APSB_sw192_CorrectedBitError m192 : 22|1@1+ (1,0) [0|1] "" Vector__XXX
 SG_ APSB_sw192_ErrorPassive m192 : 23|1@1+ (1,0) [0|1] "" Vector__XXX
 SG_ APSB_sw192_RamAccessFailed m192 : 24|1@1+ (1,0) [0|1] "" Vector__XXX
 SG_ APSB_sw192_RxMsgLost m192 : 25|1@1+ (1,0) [0|1] "" Vector__XXX
 SG_ APSB_sw192_msgIo m192 : 26|2@1+ (1,0) [0|3] "" Vector__XXX
 SG_ APSB_sw192_queueFailure m192 : 28|2@1+ (1,0) [0|3] "" Vector__XXX
 SG_ APSB_sw192_msgId m192 : 32|11@1+ (1,0) [0|2047] "" Vector__XXX
 SG_ APSB_sw199_abortCodeDas m199 : 16|6@1+ (1,0) [0|63] "" Vector__XXX
 SG_ APSB_sw199_abortCodePARK m199 : 22|5@1+ (1,0) [0|30] "" Vector__XXX
 SG_ APSB_sw199_currentSTW m199 : 27|14@1+ (0.1,-819.2) [-819.2|819.1] "deg" Vector__XXX
 SG_ APSB_sw199_currentSpeed m199 : 41|8@1+ (0.1,-12.2) [-12.2|13.3] "mph" Vector__XXX
 SG_ APSB_sw199_internalState m199 : 49|4@1+ (1,0) [0|15] "" Vector__XXX
 SG_ APSB_sw199_maxSpeed m199 : 53|7@1+ (0.2,-12.2) [-12.2|13.2] "mph" Vector__XXX
 SG_ APSB_sw199_numShifts m199 : 60|4@1+ (1,0) [0|15] "" Vector__XXX
 SG_ APSB_sw203_controlType m203 : 16|4@1+ (1,0) [0|14] "" Vector__XXX
 SG_ APSB_sw203_curbType m203 : 20|2@1+ (1,0) [0|3] "" Vector__XXX
 SG_ APSB_sw203_roadClass m203 : 22|3@1+ (1,0) [0|7] "" Vector__XXX
 SG_ APSB_sw203_slotSizeX m203 : 25|8@1+ (4,0) [0|1020] "cm" Vector__XXX
 SG_ APSB_sw203_slotSizeY m203 : 33|8@1+ (4,0) [0|1020] "cm" Vector__XXX
 SG_ APSB_sw203_startDistance m203 : 41|11@1+ (1,0) [0|2047] "cm" Vector__XXX
 SG_ APSB_sw203_vehicleSkew m203 : 52|12@1+ (0.002,0) [0|8.19] "radians" Vector__XXX
 SG_ APSB_sw204_frLeft m204 : 16|8@1+ (1,0) [0|255] "cm" Vector__XXX
 SG_ APSB_sw204_frLeftMiddle m204 : 24|8@1+ (1,0) [0|255] "cm" Vector__XXX
 SG_ APSB_sw204_frMiddle m204 : 32|8@1+ (1,0) [0|255] "cm" Vector__XXX
 SG_ APSB_sw204_frRight m204 : 40|8@1+ (1,0) [0|255] "cm" Vector__XXX
 SG_ APSB_sw204_frRightMiddle m204 : 48|8@1+ (1,0) [0|255] "cm" Vector__XXX
 SG_ APSB_sw204_maxSpeed m204 : 56|8@1+ (0.1,-12.2) [-12.2|13.3] "mph" Vector__XXX
 SG_ APSB_sw205_oocDistance m205 : 16|8@1+ (1,0) [0|255] "cm" Vector__XXX
 SG_ APSB_sw205_rrLeft m205 : 24|8@1+ (1,0) [0|255] "cm" Vector__XXX
 SG_ APSB_sw205_rrLeftMiddle m205 : 32|8@1+ (1,0) [0|255] "cm" Vector__XXX
 SG_ APSB_sw205_rrMiddle m205 : 40|8@1+ (1,0) [0|255] "cm" Vector__XXX
 SG_ APSB_sw205_rrRight m205 : 48|8@1+ (1,0) [0|255] "cm" Vector__XXX
 SG_ APSB_sw205_rrRightMiddle m205 : 56|8@1+ (1,0) [0|255] "cm" Vector__XXX
 SG_ APSB_sw235_resetOrigin m235 : 16|2@1+ (1,0) [0|3] "" Vector__XXX
 SG_ APSB_sw235_generalUnrecoverable m235 : 18|1@1+ (1,0) [0|1] "" Vector__XXX
 SG_ APSB_sw235_pgoodUnrecoverable m235 : 19|1@1+ (1,0) [0|1] "" Vector__XXX
 SG_ APSB_sw235_faultUnrecoverable m235 : 20|1@1+ (1,0) [0|1] "" Vector__XXX
 SG_ APSB_sw235_12VFuseUnrecoverable m235 : 21|1@1+ (1,0) [0|1] "" Vector__XXX
 SG_ APSB_sw235_pgoodLevelUnrcvrble m235 : 22|1@1+ (1,0) [0|1] "" Vector__XXX
 SG_ APSB_sw235_faultLevelUnrcvrble m235 : 23|1@1+ (1,0) [0|1] "" Vector__XXX
 SG_ APSB_sw235_12VFuseLvlUnrcvrble m235 : 24|1@1+ (1,0) [0|1] "" Vector__XXX
 SG_ APSB_sw235_localSoftwareFault m235 : 25|1@1+ (1,0) [0|1] "" Vector__XXX
 SG_ APSB_sw235_unrecoverableFailRese m235 : 26|1@1+ (1,0) [0|1] "" Vector__XXX
 SG_ APSB_sw235_generalGic m235 : 27|1@1+ (1,0) [0|1] "" Vector__XXX
 SG_ APSB_sw235_a72WdtTimeout m235 : 28|1@1+ (1,0) [0|1] "" Vector__XXX
 SG_ APSB_sw235_generalScs m235 : 29|1@1+ (1,0) [0|1] "" Vector__XXX
 SG_ APSB_sw235_generalUnexpected m235 : 30|1@1+ (1,0) [0|1] "" Vector__XXX
 SG_ APSB_sw235_canUncorrectedBitErro m235 : 31|1@1+ (1,0) [0|1] "" Vector__XXX
 SG_ APSB_sw235_canExitBusoffFailed m235 : 32|1@1+ (1,0) [0|1] "" Vector__XXX
 SG_ APSB_sw235_txEnFdbckNotExpected m235 : 33|1@1+ (1,0) [0|1] "" Vector__XXX
 SG_ APSB_sw235_nocSmsFailed m235 : 34|1@1+ (1,0) [0|1] "" Vector__XXX
 SG_ APSB_sw235_nocCamFailed m235 : 35|1@1+ (1,0) [0|1] "" Vector__XXX
 SG_ APSB_sw235_nocCoreFailed m235 : 36|1@1+ (1,0) [0|1] "" Vector__XXX
 SG_ APSB_sw235_nocScsFailed m235 : 37|1@1+ (1,0) [0|1] "" Vector__XXX
 SG_ APSB_sw235_model3UiReset m235 : 38|1@1+ (1,0) [0|1] "" Vector__XXX
 SG_ APSB_sw235_modelsUiReset m235 : 39|1@1+ (1,0) [0|1] "" Vector__XXX
 SG_ APSB_sw235_pmicApOnPrpUnrcvrble m235 : 40|1@1+ (1,0) [0|1] "" Vector__XXX
 SG_ APSB_sw235_apOnReadyTimeout m235 : 41|1@1+ (1,0) [0|1] "" Vector__XXX
 SG_ APSB_sw235_pmicApOnWaitUnrcvrble m235 : 42|1@1+ (1,0) [0|1] "" Vector__XXX
 SG_ APSB_sw235_apBootingTimeout m235 : 43|1@1+ (1,0) [0|1] "" Vector__XXX
 SG_ APSB_sw235_pmicApOffWaitUnrcvrbl m235 : 44|1@1+ (1,0) [0|1] "" Vector__XXX
 SG_ APSB_sw235_resetBeingSent m235 : 45|1@1+ (1,0) [0|1] "" Vector__XXX
 SG_ APSB_sw235_udsResetBeingSent m235 : 46|1@1+ (1,0) [0|1] "" Vector__XXX
 SG_ APSB_sw235_smsWdtTimeout m235 : 47|1@1+ (1,0) [0|1] "" Vector__XXX
 SG_ APSB_sw235_smsCanApHealthTimeout m235 : 48|1@1+ (1,0) [0|1] "" Vector__XXX
 SG_ APSB_sw235_smsTaskWdtTimeout m235 : 49|1@1+ (1,0) [0|1] "" Vector__XXX
 SG_ APSB_sw237_faultSource m237 : 16|7@1+ (1,0) [0|127] "" Vector__XXX
 SG_ APSB_sw237_peerSoCFaulted m237 : 23|1@1+ (1,0) [0|1] "" Vector__XXX
 SG_ APSB_sw241_unknownVendorOnResume m241 : 16|1@1+ (1,0) [0|1] "" Vector__XXX
 SG_ APSB_sw241_unknownVendorOnNonRes m241 : 17|1@1+ (1,0) [0|1] "" Vector__XXX
 SG_ APSB_sw241_phyReinitFailedOnResu m241 : 18|1@1+ (1,0) [0|1] "" Vector__XXX
 SG_ APSB_sw241_phyReinitFailedOnNonR m241 : 19|1@1+ (1,0) [0|1] "" Vector__XXX
 SG_ APSB_sw241_illTestFailed m241 : 20|1@1+ (1,0) [0|1] "" Vector__XXX
 SG_ APSB_sw241_memTestFailed m241 : 21|1@1+ (1,0) [0|1] "" Vector__XXX
 SG_ APSB_sw241_dfiInitCompleteTimeou m241 : 22|1@1+ (1,0) [0|1] "" Vector__XXX
 SG_ APSB_sw241_phy0TimeoutWaitingFor m241 : 23|1@1+ (1,0) [0|1] "" Vector__XXX
 SG_ APSB_sw241_phy0Ch0ReadGateOffset m241 : 24|1@1+ (1,0) [0|1] "" Vector__XXX
 SG_ APSB_sw241_phy0Ch1ReadGateOffset m241 : 25|1@1+ (1,0) [0|1] "" Vector__XXX
 SG_ APSB_sw241_phy0RdlvlReinitTraini m241 : 26|1@1+ (1,0) [0|1] "" Vector__XXX
 SG_ APSB_sw241_phy0RdlvlReinitFailed m241 : 27|1@1+ (1,0) [0|1] "" Vector__XXX
 SG_ APSB_sw241_phy0WdqlvlReinitTrain m241 : 28|1@1+ (1,0) [0|1] "" Vector__XXX
 SG_ APSB_sw241_phy0WdqlvlPhaseMargin m241 : 29|1@1+ (1,0) [0|1] "" Vector__XXX
 SG_ APSB_sw241_phy0WdqlvlReinitFaile m241 : 30|1@1+ (1,0) [0|1] "" Vector__XXX
 SG_ APSB_sw241_phy1TimeoutWaitingFor m241 : 31|1@1+ (1,0) [0|1] "" Vector__XXX
 SG_ APSB_sw241_phy1Ch0ReadGateOffset m241 : 32|1@1+ (1,0) [0|1] "" Vector__XXX
 SG_ APSB_sw241_phy1Ch1ReadGateOffset m241 : 33|1@1+ (1,0) [0|1] "" Vector__XXX
 SG_ APSB_sw241_phy1RdlvlReinitTraini m241 : 34|1@1+ (1,0) [0|1] "" Vector__XXX
 SG_ APSB_sw241_phy1RdlvlReinitFailed m241 : 35|1@1+ (1,0) [0|1] "" Vector__XXX
 SG_ APSB_sw241_phy1WdqlvlReinitTrain m241 : 36|1@1+ (1,0) [0|1] "" Vector__XXX
 SG_ APSB_sw241_phy1WdqlvlPhaseMargin m241 : 37|1@1+ (1,0) [0|1] "" Vector__XXX
 SG_ APSB_sw241_phy1WdqlvlReinitFaile m241 : 38|1@1+ (1,0) [0|1] "" Vector__XXX
 SG_ APSB_sw241_phy2TimeoutWaitingFor m241 : 39|1@1+ (1,0) [0|1] "" Vector__XXX
 SG_ APSB_sw241_phy2Ch0ReadGateOffset m241 : 40|1@1+ (1,0) [0|1] "" Vector__XXX
 SG_ APSB_sw241_phy2Ch1ReadGateOffset m241 : 41|1@1+ (1,0) [0|1] "" Vector__XXX
 SG_ APSB_sw241_phy2RdlvlReinitTraini m241 : 42|1@1+ (1,0) [0|1] "" Vector__XXX
 SG_ APSB_sw241_phy2RdlvlReinitFailed m241 : 43|1@1+ (1,0) [0|1] "" Vector__XXX
 SG_ APSB_sw241_phy2WdqlvlReinitTrain m241 : 44|1@1+ (1,0) [0|1] "" Vector__XXX
 SG_ APSB_sw241_phy2WdqlvlPhaseMargin m241 : 45|1@1+ (1,0) [0|1] "" Vector__XXX
 SG_ APSB_sw241_phy2WdqlvlReinitFaile m241 : 46|1@1+ (1,0) [0|1] "" Vector__XXX
 SG_ APSB_sw241_phy3TimeoutWaitingFor m241 : 47|1@1+ (1,0) [0|1] "" Vector__XXX
 SG_ APSB_sw241_phy3Ch0ReadGateOffset m241 : 48|1@1+ (1,0) [0|1] "" Vector__XXX
 SG_ APSB_sw241_phy3Ch1ReadGateOffset m241 : 49|1@1+ (1,0) [0|1] "" Vector__XXX
 SG_ APSB_sw241_phy3RdlvlReinitTraini m241 : 50|1@1+ (1,0) [0|1] "" Vector__XXX
 SG_ APSB_sw241_phy3RdlvlReinitFailed m241 : 51|1@1+ (1,0) [0|1] "" Vector__XXX
 SG_ APSB_sw241_phy3WdqlvlReinitTrain m241 : 52|1@1+ (1,0) [0|1] "" Vector__XXX
 SG_ APSB_sw241_phy3WdqlvlPhaseMargin m241 : 53|1@1+ (1,0) [0|1] "" Vector__XXX
 SG_ APSB_sw241_phy3WdqlvlReinitFaile m241 : 54|1@1+ (1,0) [0|1] "" Vector__XXX
 SG_ APSB_sw242_instance m242 : 16|3@1+ (1,0) [0|7] "" Vector__XXX
 SG_ APSB_sw242_clusterSRAMMBISTFaile m242 : 19|1@1+ (1,0) [0|1] "" Vector__XXX
 SG_ APSB_sw242_SRAMBankMBISTFailed m242 : 20|1@1+ (1,0) [0|1] "" Vector__XXX
 SG_ APSB_sw243_instance m243 : 16|3@1+ (1,0) [0|7] "" Vector__XXX
 SG_ APSB_sw243_errorStatus m243 : 24|8@1+ (1,0) [0|255] "" Vector__XXX
 SG_ APSB_sw243_extendedErrorStatus m243 : 32|24@1+ (1,0) [0|16777215] "" Vector__XXX
 SG_ APSB_sw244_instance m244 : 16|3@1+ (1,0) [0|7] "" Vector__XXX
 SG_ APSB_sw244_exceptionCode m244 : 24|8@1+ (1,0) [0|255] "" Vector__XXX
 SG_ APSB_sw245_unknownMACAddrByte0 m245 : 16|8@1+ (1,0) [0|255] "" Vector__XXX
 SG_ APSB_sw245_unknownMACAddrByte1 m245 : 24|8@1+ (1,0) [0|255] "" Vector__XXX
 SG_ APSB_sw245_unknownMACAddrByte2 m245 : 32|8@1+ (1,0) [0|255] "" Vector__XXX
 SG_ APSB_sw245_unknownMACAddrByte3 m245 : 40|8@1+ (1,0) [0|255] "" Vector__XXX
 SG_ APSB_sw245_unknownMACAddrByte4 m245 : 48|8@1+ (1,0) [0|255] "" Vector__XXX
 SG_ APSB_sw245_unknownMACAddrByte5 m245 : 56|8@1+ (1,0) [0|255] "" Vector__XXX
 SG_ APSB_sw246_ethloopSwitchPort0 m246 : 16|1@1+ (1,0) [0|1] "" Vector__XXX
 SG_ APSB_sw246_ethloopSwitchPort1 m246 : 17|1@1+ (1,0) [0|1] "" Vector__XXX
 SG_ APSB_sw246_ethloopSwitchPort2 m246 : 18|1@1+ (1,0) [0|1] "" Vector__XXX
 SG_ APSB_sw246_ethloopSwitchPort3 m246 : 19|1@1+ (1,0) [0|1] "" Vector__XXX
 SG_ APSB_sw246_ethloopSwitchPort4 m246 : 20|1@1+ (1,0) [0|1] "" Vector__XXX
 SG_ APSB_sw246_ethloopSwitchPort5 m246 : 21|1@1+ (1,0) [0|1] "" Vector__XXX
 SG_ APSB_sw246_ethloopSwitchPort6 m246 : 22|1@1+ (1,0) [0|1] "" Vector__XXX
 SG_ APSB_sw246_ethloopSwitchPort7 m246 : 23|1@1+ (1,0) [0|1] "" Vector__XXX
 SG_ APSB_sw247_crcError m247 : 16|1@1+ (1,0) [0|1] "" Vector__XXX
 SG_ APSB_sw247_dribbleError m247 : 17|1@1+ (1,0) [0|1] "" Vector__XXX
 SG_ APSB_sw247_receiveError m247 : 18|1@1+ (1,0) [0|1] "" Vector__XXX
 SG_ APSB_sw247_wdogTimeout m247 : 19|1@1+ (1,0) [0|1] "" Vector__XXX
 SG_ APSB_sw247_overflowError m247 : 20|1@1+ (1,0) [0|1] "" Vector__XXX
 SG_ APSB_sw247_giantPacket m247 : 21|1@1+ (1,0) [0|1] "" Vector__XXX
 SG_ APSB_sw247_destAddrFilterFail m247 : 22|1@1+ (1,0) [0|1] "" Vector__XXX
 SG_ APSB_sw247_saAddressFilterFail m247 : 23|1@1+ (1,0) [0|1] "" Vector__XXX
 SG_ APSB_sw248_ethloopSwitchPort2Sqi m248 : 16|3@1+ (1,0) [0|7] "" Vector__XXX
 SG_ APSB_sw248_ethloopSwitchPort3Sqi m248 : 19|3@1+ (1,0) [0|7] "" Vector__XXX
 SG_ APSB_sw249_ufsInitFailureReason m249 : 16|3@1+ (1,0) [0|7] "" Vector__XXX
 SG_ APSB_sw252_ethSwitchPort2 m252 : 16|1@1+ (1,0) [0|1] "" Vector__XXX
 SG_ APSB_sw253_apWaitForShutdownTime m253 : 16|1@1+ (1,0) [0|1] "" Vector__XXX
 SG_ APSB_sw253_apOffPrepareTimeout m253 : 17|1@1+ (1,0) [0|1] "" Vector__XXX
 SG_ APSB_sw253_apSuspendedTimeout m253 : 18|1@1+ (1,0) [0|1] "" Vector__XXX
 SG_ APSB_sw253_socOffReadyTimeout m253 : 19|1@1+ (1,0) [0|1] "" Vector__XXX
 SG_ APSB_sw253_apInLinuxTimeout m253 : 20|1@1+ (1,0) [0|1] "" Vector__XXX
 SG_ APSB_sw253_apInCorebootTimeout m253 : 21|1@1+ (1,0) [0|1] "" Vector__XXX
 SG_ APSB_sw253_apBootingTimeout m253 : 22|1@1+ (1,0) [0|1] "" Vector__XXX
 SG_ APSB_sw253_apOnTimeout m253 : 23|1@1+ (1,0) [0|1] "" Vector__XXX
 SG_ APSB_sw254_waitForBusSilenceTime m254 : 16|1@1+ (1,0) [0|1] "" Vector__XXX
 SG_ APSB_sw254_sleepReadyTimeout m254 : 17|1@1+ (1,0) [0|1] "" Vector__XXX
 SG_ APSB_sw254_sleepingTimeout m254 : 18|1@1+ (1,0) [0|1] "" Vector__XXX
 SG_ APSB_sw255_unknownBootError m255 : 16|1@1+ (1,0) [0|1] "" Vector__XXX
 SG_ APSB_sw255_adcWrapperInitBootErr m255 : 17|1@1+ (1,0) [0|1] "" Vector__XXX
 SG_ APSB_sw255_boardRevisionInitBoot m255 : 18|1@1+ (1,0) [0|1] "" Vector__XXX
 SG_ APSB_sw255_i2cInitBootError m255 : 19|1@1+ (1,0) [0|1] "" Vector__XXX
 SG_ APSB_sw255_provisionInitBootErro m255 : 20|1@1+ (1,0) [0|1] "" Vector__XXX
 SG_ APSB_sw255_rtcInitBootError m255 : 21|1@1+ (1,0) [0|1] "" Vector__XXX
 SG_ APSB_sw255_vrmInitConfigBootErro m255 : 22|1@1+ (1,0) [0|1] "" Vector__XXX
 SG_ APSB_sw255_powerAonIoBootError m255 : 23|1@1+ (1,0) [0|1] "" Vector__XXX
 SG_ APSB_sw255_bl1TocInitBootError m255 : 24|1@1+ (1,0) [0|1] "" Vector__XXX
 SG_ APSB_sw255_tmuInitBootError m255 : 25|1@1+ (1,0) [0|1] "" Vector__XXX
 SG_ APSB_sw255_udpInitBootError m255 : 26|1@1+ (1,0) [0|1] "" Vector__XXX
 SG_ APSB_sw255_gpsInitBootError m255 : 27|1@1+ (1,0) [0|1] "" Vector__XXX
 SG_ APSB_sw255_canInitBootError m255 : 28|1@1+ (1,0) [0|1] "" Vector__XXX
 SG_ APSB_sw255_dfuCheckinSubsystemBo m255 : 29|1@1+ (1,0) [0|1] "" Vector__XXX
 SG_ APSB_sw255_sectorProtectionBootE m255 : 30|1@1+ (1,0) [0|1] "" Vector__XXX
 SG_ APSB_sw255_flashOpBootError m255 : 31|1@1+ (1,0) [0|1] "" Vector__XXX
 SG_ APSB_sw255_socIdInitBootError m255 : 32|1@1+ (1,0) [0|1] "" Vector__XXX
 SG_ APSB_sw260_pgoodTripSramStatus m260 : 16|8@1+ (1,0) [0|255] "" Vector__XXX
 SG_ APSB_sw260_pgoodPmicFaultSd0 m260 : 24|1@1+ (1,0) [0|1] "" Vector__XXX
 SG_ APSB_sw260_pgoodPmicFaultSd1 m260 : 25|1@1+ (1,0) [0|1] "" Vector__XXX
 SG_ APSB_sw260_pgoodPmicFaultSd2 m260 : 26|1@1+ (1,0) [0|1] "" Vector__XXX
 SG_ APSB_sw260_pgoodPmicFaultSd3 m260 : 27|1@1+ (1,0) [0|1] "" Vector__XXX
 SG_ APSB_sw260_pgoodPmicFaultSd4 m260 : 28|1@1+ (1,0) [0|1] "" Vector__XXX
 SG_ APSB_sw260_pgoodPmicFaultLdo0 m260 : 29|1@1+ (1,0) [0|1] "" Vector__XXX
 SG_ APSB_sw260_pgoodPmicFaultLdo1 m260 : 30|1@1+ (1,0) [0|1] "" Vector__XXX
 SG_ APSB_sw260_pgoodPmicFaultLdo2 m260 : 31|1@1+ (1,0) [0|1] "" Vector__XXX
 SG_ APSB_sw260_pgoodPmicFaultLdo3 m260 : 32|1@1+ (1,0) [0|1] "" Vector__XXX
 SG_ APSB_sw260_pgoodPmicFaultLdo4 m260 : 33|1@1+ (1,0) [0|1] "" Vector__XXX
 SG_ APSB_sw260_pgoodPmicFaultLdo5 m260 : 34|1@1+ (1,0) [0|1] "" Vector__XXX
 SG_ APSB_sw260_pgoodPmicFaultLdo6 m260 : 35|1@1+ (1,0) [0|1] "" Vector__XXX
 SG_ APSB_sw260_pgoodPmicFaultLdo7 m260 : 36|1@1+ (1,0) [0|1] "" Vector__XXX
 SG_ APSB_sw260_pgoodPmicFaultLdo8 m260 : 37|1@1+ (1,0) [0|1] "" Vector__XXX
 SG_ APSB_sw260_pgoodUfs3V3Fail m260 : 38|1@1+ (1,0) [0|1] "" Vector__XXX
 SG_ APSB_sw260_pgoodTripVrmRailFail m260 : 39|1@1+ (1,0) [0|1] "" Vector__XXX
 SG_ APSB_sw260_pgoodIntVrmRailFail m260 : 40|1@1+ (1,0) [0|1] "" Vector__XXX
 SG_ APSB_sw260_pgoodCpuVrmRailFail m260 : 41|1@1+ (1,0) [0|1] "" Vector__XXX
 SG_ APSB_sw260_pgoodGpuVrmRailFail m260 : 42|1@1+ (1,0) [0|1] "" Vector__XXX
 SG_ APSB_sw260_pgoodDdr0V75VrmRailFa m260 : 43|1@1+ (1,0) [0|1] "" Vector__XXX
 SG_ APSB_sw260_pgoodDdr1V25VrmRailFa m260 : 44|1@1+ (1,0) [0|1] "" Vector__XXX
 SG_ APSB_sw260_unknownSource m260 : 45|1@1+ (1,0) [0|1] "" Vector__XXX
 SG_ APSB_sw261_vrmPublicFaultValues m261 : 16|16@1+ (1,0) [0|65535] "" Vector__XXX
 SG_ APSB_sw261_vrmRail1FaultValues m261 : 32|8@1+ (1,0) [0|255] "" Vector__XXX
 SG_ APSB_sw261_vrmRail2FaultValues m261 : 40|8@1+ (1,0) [0|255] "" Vector__XXX
 SG_ APSB_sw261_vrmRail3FaultValues m261 : 48|8@1+ (1,0) [0|255] "" Vector__XXX
 SG_ APSB_sw261_vrmType m261 : 56|3@1+ (1,0) [0|7] "" Vector__XXX
 SG_ APSB_sw262_vrmPublicFaultValues m262 : 16|16@1+ (1,0) [0|65535] "" Vector__XXX
 SG_ APSB_sw262_vrmRail1FaultValues m262 : 32|8@1+ (1,0) [0|255] "" Vector__XXX
 SG_ APSB_sw262_vrmRail2FaultValues m262 : 40|8@1+ (1,0) [0|255] "" Vector__XXX
 SG_ APSB_sw262_vrmRail3FaultValues m262 : 48|8@1+ (1,0) [0|255] "" Vector__XXX
 SG_ APSB_sw262_vrmType m262 : 56|3@1+ (1,0) [0|7] "" Vector__XXX
 SG_ APSB_sw263_vrmPublicFaultValues m263 : 16|16@1+ (1,0) [0|65535] "" Vector__XXX
 SG_ APSB_sw263_vrmRail1FaultValues m263 : 32|8@1+ (1,0) [0|255] "" Vector__XXX
 SG_ APSB_sw263_vrmRail2FaultValues m263 : 40|8@1+ (1,0) [0|255] "" Vector__XXX
 SG_ APSB_sw263_vrmType m263 : 48|3@1+ (1,0) [0|7] "" Vector__XXX
 SG_ APSB_sw279_corruptDirectorySourc m279 : 16|3@1+ (1,0) [0|7] "" Vector__XXX
 SG_ APSB_sw279_errorCode m279 : 24|8@1+ (1,0) [0|255] "" Vector__XXX
 SG_ APSB_sw280_pepsStatus m280 : 16|1@1+ (1,0) [0|1] "" Vector__XXX
 SG_ APSB_sw281_rearSteerStatus m281 : 16|1@1+ (1,0) [0|1] "" Vector__XXX
 SG_ APSB_sw283_psfaStatus m283 : 16|1@1+ (1,0) [0|1] "" Vector__XXX
 SG_ APSB_sw288_status m288 : 16|1@1+ (1,0) [0|1] "" Vector__XXX
 SG_ APSB_sw289_turboTemperature m289 : 16|8@1- (1,0) [-128|127] "degC" Vector__XXX
 SG_ APSB_sw289_turboProbe m289 : 24|6@1+ (1,0) [0|63] "" Vector__XXX
 SG_ APSB_sw289_peer_turboTemperature m289 : 32|8@1- (1,0) [-128|127] "degC" Vector__XXX
 SG_ APSB_sw289_peer_turboProbe m289 : 40|6@1+ (1,0) [0|63] "" Vector__XXX
 SG_ APSB_sw315_sysStatus m315 : 16|1@1+ (1,0) [0|1] "" Vector__XXX
 SG_ APSB_sw315_status m315 : 17|1@1+ (1,0) [0|1] "" Vector__XXX
 SG_ APSB_sw317_motionControlCommand m317 : 16|1@1+ (1,0) [0|1] "" Vector__XXX
 SG_ APSB_sw317_vehicleControl2 m317 : 17|1@1+ (1,0) [0|1] "" Vector__XXX

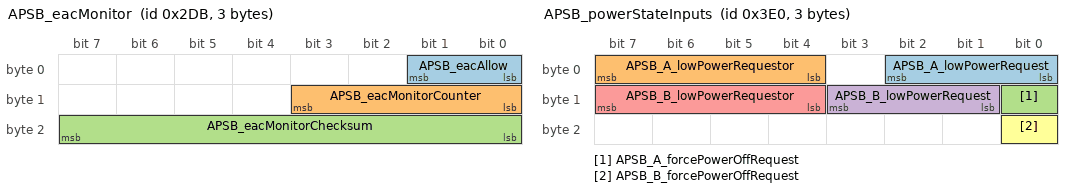
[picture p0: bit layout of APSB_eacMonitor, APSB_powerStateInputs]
BO_ 731 APSB_eacMonitor: 3 APSB
 SG_ APSB_eacAllow : 0|2@1+ (1,0) [0|2] "" Vector__XXX
 SG_ APSB_eacMonitorCounter : 8|4@1+ (1,0) [0|15] "" Vector__XXX
 SG_ APSB_eacMonitorChecksum : 16|8@1+ (1,0) [0|255] "" Vector__XXX

BO_ 992 APSB_powerStateInputs: 3 APSB
 SG_ APSB_A_lowPowerRequest : 0|3@1+ (1,0) [0|7] "" Vector__XXX
 SG_ APSB_A_lowPowerRequestor : 4|4@1+ (1,0) [0|15] "" Vector__XXX
 SG_ APSB_A_forcePowerOffRequest : 8|1@1+ (1,0) [0|1] "" Vector__XXX
 SG_ APSB_B_lowPowerRequest : 9|3@1+ (1,0) [0|7] "" Vector__XXX
 SG_ APSB_B_lowPowerRequestor : 12|4@1+ (1,0) [0|15] "" Vector__XXX
 SG_ APSB_B_forcePowerOffRequest : 16|1@1+ (1,0) [0|1] "" Vector__XXX

BO_ 1864 APSB_state: 8 APSB
 SG_ APSB_primaryTurbo : 0|2@1+ (1,0) [0|3] "" Vector__XXX
 SG_ APSB_A_arbState : 2|3@1+ (1,0) [0|7] "" Vector__XXX
 SG_ APSB_A_powerState : 5|5@1+ (1,0) [0|31] "" Vector__XXX
 SG_ APSB_A_sleepState : 10|4@1+ (1,0) [0|15] "" Vector__XXX
 SG_ APSB_A_resetState : 14|3@1+ (1,0) [0|7] "" Vector__XXX
 SG_ APSB_A_faultState : 17|5@1+ (1,0) [0|31] "" Vector__XXX
 SG_ APSB_secondaryTurbo : 22|2@1+ (1,0) [0|3] "" Vector__XXX
 SG_ APSB_B_arbState : 24|3@1+ (1,0) [0|7] "" Vector__XXX
 SG_ APSB_B_powerState : 27|5@1+ (1,0) [0|31] "" Vector__XXX
 SG_ APSB_B_sleepState : 32|4@1+ (1,0) [0|15] "" Vector__XXX
 SG_ APSB_B_resetState : 36|3@1+ (1,0) [0|7] "" Vector__XXX
 SG_ APSB_B_faultState : 39|5@1+ (1,0) [0|31] "" Vector__XXX
 SG_ APSB_A_autosteerMonitorState : 44|3@1+ (1,0) [0|7] "" Vector__XXX
 SG_ APSB_B_autosteerMonitorState : 47|3@1+ (1,0) [0|7] "" Vector__XXX
 SG_ APSB_eplannerState : 50|3@1+ (1,0) [0|7] "" Vector__XXX
 SG_ APSB_A_faultInduced : 53|1@1+ (1,0) [0|1] "" Vector__XXX
 SG_ APSB_B_faultInduced : 54|1@1+ (1,0) [0|1] "" Vector__XXX
 SG_ APSB_stateCounter : 55|4@1+ (1,0) [0|15] "" Vector__XXX

BO_ 971 APSB_status: 8 APSB
 SG_ APSB_appStatusMonitorState : 0|3@1+ (1,0) [0|7] "" Vector__XXX
 SG_ APSB_vehBehaviorState : 4|4@1+ (1,0) [0|15] "" Vector__XXX
 SG_ APSB_canMaster : 8|2@1+ (1,0) [0|2] "" Vector__XXX
 SG_ APSB_appGpioState : 10|2@1+ (1,0) [0|3] "" Vector__XXX
 SG_ APSB_eacInternalState : 12|3@1+ (1,0) [0|7] "" Vector__XXX
 SG_ APSB_switchState : 15|1@1+ (1,0) [0|1] "" Vector__XXX
 SG_ APSB_apbStatusMonitorState : 16|3@1+ (1,0) [0|7] "" Vector__XXX
 SG_ APSB_apbGpioState : 20|2@1+ (1,0) [0|3] "" Vector__XXX
 SG_ APSB_statusCounter : 22|4@1+ (1,0) [0|15] "" Vector__XXX
 SG_ APSB_locLimitReason : 26|3@1+ (1,0) [0|7] "" Vector__XXX
 SG_ APSB_appPowerStateRequest : 29|2@1+ (1,0) [0|3] "" Vector__XXX
 SG_ APSB_appPowerStateReason : 31|4@1+ (1,0) [0|15] "" Vector__XXX
 SG_ APSB_apbPowerStateRequest : 36|2@1+ (1,0) [0|3] "" Vector__XXX
 SG_ APSB_apbPowerStateReason : 38|4@1+ (1,0) [0|15] "" Vector__XXX
 SG_ APSB_heaterStateDebug : 43|3@1+ (1,0) [0|6] "" Vector__XXX
 SG_ APSB_autosummonCounter : 46|3@1+ (1,0) [0|7] "" Vector__XXX
 SG_ APSB_autosummonAlert : 49|1@1+ (1,0) [0|1] "" Vector__XXX
 SG_ APSB_gpsAntennaState : 50|2@1+ (1,0) [0|3] "" Vector__XXX
 SG_ APSB_arbState : 52|3@1+ (1,0) [0|7] "" Vector__XXX
 SG_ APSB_socPowerOperatingMode : 55|2@1+ (1,0) [0|3] "" Vector__XXX

BO_ 845 APSB_warningMatrix0: 8 APSB
 SG_ APSB_w001_DEPRECATED : 0|1@1+ (1,0) [0|1] "" Vector__XXX
 SG_ APSB_w002_ldwDisabled : 1|1@1+ (1,0) [0|1] "" Vector__XXX
 SG_ APSB_w003_isaDisabled : 2|1@1+ (1,0) [0|1] "" Vector__XXX
 SG_ APSB_w004_accDisabled : 3|1@1+ (1,0) [0|1] "" Vector__XXX
 SG_ APSB_w005_fcwCancelled : 4|1@1+ (1,0) [0|1] "" Vector__XXX
 SG_ APSB_w006_aebCancelled : 5|1@1+ (1,0) [0|1] "" Vector__XXX
 SG_ APSB_w007_ahlbDisabled : 6|1@1+ (1,0) [0|1] "" Vector__XXX
 SG_ APSB_w008_parkDisabled : 7|1@1+ (1,0) [0|1] "" Vector__XXX
 SG_ APSB_w009_aebFault : 8|1@1+ (1,0) [0|1] "" Vector__XXX
 SG_ APSB_w010_radcCalibIssue : 9|1@1+ (1,0) [0|1] "" Vector__XXX
 SG_ APSB_w011_scaEvent : 10|1@1+ (1,0) [0|1] "" Vector__XXX
 SG_ APSB_w012_Cam_BootFailure : 11|1@1+ (1,0) [0|1] "" Vector__XXX
 SG_ APSB_w013_Cam_Watchdog : 12|1@1+ (1,0) [0|1] "" Vector__XXX
 SG_ APSB_w014_swAssert : 13|1@1+ (1,0) [0|1] "" Vector__XXX
 SG_ APSB_w015_Camera_Failsafes : 14|1@1+ (1,0) [0|1] "" Vector__XXX
 SG_ APSB_w016_aeb_e_event : 15|1@1+ (1,0) [0|1] "" Vector__XXX
 SG_ APSB_w017_Cam_Msg_MIA : 16|1@1+ (1,0) [0|1] "" Vector__XXX
 SG_ APSB_w018_ECU_Power_Issue : 17|1@1+ (1,0) [0|1] "" Vector__XXX
 SG_ APSB_w019_ECU_Stack_Overflow : 18|1@1+ (1,0) [0|1] "" Vector__XXX
 SG_ APSB_w020_ECU_checkstopError : 19|1@1+ (1,0) [0|1] "" Vector__XXX
 SG_ APSB_w021_ECU_Temperature_Issue : 20|1@1+ (1,0) [0|1] "" Vector__XXX
 SG_ APSB_w022_ECU_EEPROM_Failure : 21|1@1+ (1,0) [0|1] "" Vector__XXX
 SG_ APSB_w023_ECU_Cam_Statemismatc : 22|1@1+ (1,0) [0|1] "" Vector__XXX
 SG_ APSB_w024_ECU_Watchdog_Reset : 23|1@1+ (1,0) [0|1] "" Vector__XXX
 SG_ APSB_w025_LC_Steering_Override : 24|1@1+ (1,0) [0|1] "" Vector__XXX
 SG_ APSB_w026_ECU_timingIssue : 25|1@1+ (1,0) [0|1] "" Vector__XXX
 SG_ APSB_w027_ECU_Reset_Fault : 26|1@1+ (1,0) [0|1] "" Vector__XXX
 SG_ APSB_w028_spi_rx_error : 27|1@1+ (1,0) [0|1] "" Vector__XXX
 SG_ APSB_w029_spi_tx_error : 28|1@1+ (1,0) [0|1] "" Vector__XXX
 SG_ APSB_w030_Heater_Issue : 29|1@1+ (1,0) [0|1] "" Vector__XXX
 SG_ APSB_w031_canRxError : 30|1@1+ (1,0) [0|1] "" Vector__XXX
 SG_ APSB_w032_canTxError : 31|1@1+ (1,0) [0|1] "" Vector__XXX
 SG_ APSB_w033_gtwMia : 32|1@1+ (1,0) [0|1] "" Vector__XXX
 SG_ APSB_w034_sccmMia : 33|1@1+ (1,0) [0|1] "" Vector__XXX
 SG_ APSB_w035_espMia : 34|1@1+ (1,0) [0|1] "" Vector__XXX
 SG_ APSB_w036_bdyMia : 35|1@1+ (1,0) [0|1] "" Vector__XXX
 SG_ APSB_w037_camTacIssue : 36|1@1+ (1,0) [0|1] "" Vector__XXX
 SG_ APSB_w038_camFailure : 37|1@1+ (1,0) [0|1] "" Vector__XXX
 SG_ APSB_w039_sdm_rcm_Mia : 38|1@1+ (1,0) [0|1] "" Vector__XXX
 SG_ APSB_w040_autopilotAngleSaturate : 39|1@1+ (1,0) [0|1] "" Vector__XXX
 SG_ APSB_w041_autopilotRateSaturated : 40|1@1+ (1,0) [0|1] "" Vector__XXX
 SG_ APSB_w042_autopilotAborting : 41|1@1+ (1,0) [0|1] "" Vector__XXX
 SG_ APSB_w043_camLongRunTime : 42|1@1+ (1,0) [0|1] "" Vector__XXX
 SG_ APSB_w044_appMobileyeFailure : 43|1@1+ (1,0) [0|1] "" Vector__XXX
 SG_ APSB_w045_radMia : 44|1@1+ (1,0) [0|1] "" Vector__XXX
 SG_ APSB_w046_eepromRecordAbsent : 45|1@1+ (1,0) [0|1] "" Vector__XXX
 SG_ APSB_w047_edrEvent : 46|1@1+ (1,0) [0|1] "" Vector__XXX
 SG_ APSB_w048_DAS_Features_Disabled : 47|1@1+ (1,0) [0|1] "" Vector__XXX
 SG_ APSB_w049_eyeqVersionMismatch : 48|1@1+ (1,0) [0|1] "" Vector__XXX
 SG_ APSB_w050_aeb_event : 49|1@1+ (1,0) [0|1] "" Vector__XXX
 SG_ APSB_w051_radcEcuIssue : 50|1@1+ (1,0) [0|1] "" Vector__XXX
 SG_ APSB_w052_radcSensorIssue : 51|1@1+ (1,0) [0|1] "" Vector__XXX
 SG_ APSB_w053_radcCommIssue : 52|1@1+ (1,0) [0|1] "" Vector__XXX
 SG_ APSB_w054_camAutofix : 53|1@1+ (1,0) [0|1] "" Vector__XXX
 SG_ APSB_w055_radcVersionMismatch : 54|1@1+ (1,0) [0|1] "" Vector__XXX
 SG_ APSB_w056_diMia : 55|1@1+ (1,0) [0|1] "" Vector__XXX
 SG_ APSB_w057_mcuMia : 56|1@1+ (1,0) [0|1] "" Vector__XXX
 SG_ APSB_w058_epbMia : 57|1@1+ (1,0) [0|1] "" Vector__XXX
 SG_ APSB_w059_parkMia : 58|1@1+ (1,0) [0|1] "" Vector__XXX
 SG_ APSB_w060_fcw_event : 59|1@1+ (1,0) [0|1] "" Vector__XXX
 SG_ APSB_w061_tasMia : 60|1@1+ (1,0) [0|1] "" Vector__XXX
 SG_ APSB_w062_radcAlignment : 61|1@1+ (1,0) [0|1] "" Vector__XXX
 SG_ APSB_w063_parkVersionMismatch : 62|1@1+ (1,0) [0|1] "" Vector__XXX
 SG_ APSB_w064_epasMia : 63|1@1+ (1,0) [0|1] "" Vector__XXX

BO_ 1143 APSB_warningMatrix1: 8 APSB
 SG_ APSB_w065_deserializerOvercurren : 0|1@1+ (1,0) [0|1] "" Vector__XXX
 SG_ APSB_w066_deserializerLockLost : 1|1@1+ (1,0) [0|1] "" Vector__XXX
 SG_ APSB_w067_steeringAlignment : 2|1@1+ (1,0) [0|1] "" Vector__XXX
 SG_ APSB_w068_vlInconsistency : 3|1@1+ (1,0) [0|1] "" Vector__XXX
 SG_ APSB_w069_apcSpaceMasked : 4|1@1+ (1,0) [0|1] "" Vector__XXX
 SG_ APSB_w070_apcIncompleteCal : 5|1@1+ (1,0) [0|1] "" Vector__XXX
 SG_ APSB_w071_selfparkStarted : 6|1@1+ (1,0) [0|1] "" Vector__XXX
 SG_ APSB_w072_selfparkComplete : 7|1@1+ (1,0) [0|1] "" Vector__XXX
 SG_ APSB_w073_issueEscalatedLDW : 8|1@1+ (1,0) [0|1] "" Vector__XXX
 SG_ APSB_w074_inPathStationaryObst : 9|1@1+ (1,0) [0|1] "" Vector__XXX
 SG_ APSB_w075_scMia : 10|1@1+ (1,0) [0|1] "" Vector__XXX
 SG_ APSB_w076_mobilEyeSetC : 11|1@1+ (1,0) [0|1] "" Vector__XXX
 SG_ APSB_w077_pmmActive : 12|1@1+ (1,0) [0|1] "" Vector__XXX
 SG_ APSB_w078_pmmActive2 : 13|1@1+ (1,0) [0|1] "" Vector__XXX
 SG_ APSB_w079_edrAvailable : 14|1@1+ (1,0) [0|1] "" Vector__XXX
 SG_ APSB_w080_accFailedActivation : 15|1@1+ (1,0) [0|1] "" Vector__XXX
 SG_ APSB_w081_pmmActiveBraking : 16|1@1+ (1,0) [0|1] "" Vector__XXX
 SG_ APSB_w082_inPathFSviolation : 17|1@1+ (1,0) [0|1] "" Vector__XXX
 SG_ APSB_w083_inPathRADObject : 18|1@1+ (1,0) [0|1] "" Vector__XXX
 SG_ APSB_w084_pmmIPSO : 19|1@1+ (1,0) [0|1] "" Vector__XXX
 SG_ APSB_w085_pmmSteering : 20|1@1+ (1,0) [0|1] "" Vector__XXX
 SG_ APSB_w086_robCollision : 21|1@1+ (1,0) [0|1] "" Vector__XXX
 SG_ APSB_w087_DEPRECATED : 22|1@1+ (1,0) [0|1] "" Vector__XXX
 SG_ APSB_w088_DEPRECATED : 23|1@1+ (1,0) [0|1] "" Vector__XXX
 SG_ APSB_w089_DEPRECATED : 24|1@1+ (1,0) [0|1] "" Vector__XXX
 SG_ APSB_w090_DEPRECATED : 25|1@1+ (1,0) [0|1] "" Vector__XXX
 SG_ APSB_w091_DEPRECATED : 26|1@1+ (1,0) [0|1] "" Vector__XXX
 SG_ APSB_w092_DEPRECATED : 27|1@1+ (1,0) [0|1] "" Vector__XXX
 SG_ APSB_w093_DEPRECATED : 28|1@1+ (1,0) [0|1] "" Vector__XXX
 SG_ APSB_w094_DEPRECATED : 29|1@1+ (1,0) [0|1] "" Vector__XXX
 SG_ APSB_w095_DEPRECATED : 30|1@1+ (1,0) [0|1] "" Vector__XXX
 SG_ APSB_w096_DEPRECATED : 31|1@1+ (1,0) [0|1] "" Vector__XXX
 SG_ APSB_w097_DEPRECATED : 32|1@1+ (1,0) [0|1] "" Vector__XXX
 SG_ APSB_w098_DEPRECATED : 33|1@1+ (1,0) [0|1] "" Vector__XXX
 SG_ APSB_w099_DEPRECATED : 34|1@1+ (1,0) [0|1] "" Vector__XXX
 SG_ APSB_w100_DEPRECATED : 35|1@1+ (1,0) [0|1] "" Vector__XXX
 SG_ APSB_w101_DEPRECATED : 36|1@1+ (1,0) [0|1] "" Vector__XXX
 SG_ APSB_w102_DEPRECATED : 37|1@1+ (1,0) [0|1] "" Vector__XXX
 SG_ APSB_w103_robExperimentalAEB : 38|1@1+ (1,0) [0|1] "" Vector__XXX
 SG_ APSB_w104_DEPRECATED : 39|1@1+ (1,0) [0|1] "" Vector__XXX
 SG_ APSB_w105_DEPRECATED : 40|1@1+ (1,0) [0|1] "" Vector__XXX
 SG_ APSB_w106_torsionBarOffset : 41|1@1+ (1,0) [0|1] "" Vector__XXX

BO_ 942 APSB_warningMatrix2: 8 APSB
 SG_ APSB_w129_ECU_Power_Issue : 0|1@1+ (1,0) [0|1] "" Vector__XXX
 SG_ APSB_w130_ECU_Thermal_Issue : 1|1@1+ (1,0) [0|1] "" Vector__XXX
 SG_ APSB_w131_trap_exception : 2|1@1+ (1,0) [0|1] "" Vector__XXX
 SG_ APSB_w132_appVersionMismatch : 3|1@1+ (1,0) [0|1] "" Vector__XXX
 SG_ APSB_w133_ETHSwitchError : 4|1@1+ (1,0) [0|1] "" Vector__XXX
 SG_ APSB_w134_appMia : 5|1@1+ (1,0) [0|1] "" Vector__XXX
 SG_ APSB_w135_appCritical : 6|1@1+ (1,0) [0|1] "" Vector__XXX
 SG_ APSB_w136_gpsDisabled : 7|1@1+ (1,0) [0|1] "" Vector__XXX
 SG_ APSB_w137_gpsFaultReset : 8|1@1+ (1,0) [0|1] "" Vector__XXX
 SG_ APSB_w138_gpsComIssue : 9|1@1+ (1,0) [0|1] "" Vector__XXX
 SG_ APSB_w139_udpBufferOverflow : 10|1@1+ (1,0) [0|1] "" Vector__XXX
 SG_ APSB_w140_vcfrontMiaVehicleBus : 11|1@1+ (1,0) [0|1] "" Vector__XXX
 SG_ APSB_w141_rcmMiaPartyBus : 12|1@1+ (1,0) [0|1] "" Vector__XXX
 SG_ APSB_w142_diMiaPartyBus : 13|1@1+ (1,0) [0|1] "" Vector__XXX
 SG_ APSB_w143_espMiaPartyBus : 14|1@1+ (1,0) [0|1] "" Vector__XXX
 SG_ APSB_w144_vcleftMiaPartyBus : 15|1@1+ (1,0) [0|1] "" Vector__XXX
 SG_ APSB_w145_vcrightMiaPartyBus : 16|1@1+ (1,0) [0|1] "" Vector__XXX
 SG_ APSB_w146_epas3pMiaPartyBus : 17|1@1+ (1,0) [0|1] "" Vector__XXX
 SG_ APSB_w147_vcleftMiaVehBus : 18|1@1+ (1,0) [0|1] "" Vector__XXX
 SG_ APSB_w148_vcrightMiaVehBus : 19|1@1+ (1,0) [0|1] "" Vector__XXX
 SG_ APSB_w149_epblMiaVehBus : 20|1@1+ (1,0) [0|1] "" Vector__XXX
 SG_ APSB_w150_sccmMiaVehBus : 21|1@1+ (1,0) [0|1] "" Vector__XXX
 SG_ APSB_w151_apRecovered : 22|1@1+ (1,0) [0|1] "" Vector__XXX
 SG_ APSB_w152_gpsFusionStatus : 23|1@1+ (1,0) [0|1] "" Vector__XXX
 SG_ APSB_w153_eacInhibit : 24|1@1+ (1,0) [0|1] "" Vector__XXX
 SG_ APSB_w155_ethLwipError : 26|1@1+ (1,0) [0|1] "" Vector__XXX
 SG_ APSB_w156_lwipAssert : 27|1@1+ (1,0) [0|1] "" Vector__XXX
 SG_ APSB_w157_autopilotReboot : 28|1@1+ (1,0) [0|1] "" Vector__XXX
 SG_ APSB_w158_apbMia : 29|1@1+ (1,0) [0|1] "" Vector__XXX
 SG_ APSB_w159_apbCritical : 30|1@1+ (1,0) [0|1] "" Vector__XXX
 SG_ APSB_w160_apbVersionMismatch : 31|1@1+ (1,0) [0|1] "" Vector__XXX
 SG_ APSB_w161_gpsAntennaDisconnected : 32|1@1+ (1,0) [0|1] "" Vector__XXX
 SG_ APSB_w162_TurboA_DisRegPgoodErr : 33|1@1+ (1,0) [0|1] "" Vector__XXX
 SG_ APSB_w163_TurboA_DisRegNFault : 34|1@1+ (1,0) [0|1] "" Vector__XXX
 SG_ APSB_w164_TurboA_12VFuseFault : 35|1@1+ (1,0) [0|1] "" Vector__XXX
 SG_ APSB_w165_TurboA_Temp_NOS : 36|1@1+ (1,0) [0|1] "" Vector__XXX
 SG_ APSB_w166_TurboA_SMSLockStepErr : 37|1@1+ (1,0) [0|1] "" Vector__XXX
 SG_ APSB_w167_TurboA_TMU_Throttle : 38|1@1+ (1,0) [0|1] "" Vector__XXX
 SG_ APSB_w168_TurboA_SMS_WDOG : 39|1@1+ (1,0) [0|1] "" Vector__XXX
 SG_ APSB_w169_TurboA_SCS_LKUP : 40|1@1+ (1,0) [0|1] "" Vector__XXX
 SG_ APSB_w170_TurboA_A72_watchdog : 41|1@1+ (1,0) [0|1] "" Vector__XXX
 SG_ APSB_w171_TurboA_SMS_taskUtilErr : 42|1@1+ (1,0) [0|1] "" Vector__XXX
 SG_ APSB_w172_apFeaturesUnavailable : 43|1@1+ (1,0) [0|1] "" Vector__XXX
 SG_ APSB_w178_TurboB_DisRegPgoodErr : 49|1@1+ (1,0) [0|1] "" Vector__XXX
 SG_ APSB_w179_TurboB_DisRegNFault : 50|1@1+ (1,0) [0|1] "" Vector__XXX
 SG_ APSB_w180_TurboB_12VFuseFault : 51|1@1+ (1,0) [0|1] "" Vector__XXX
 SG_ APSB_w181_TurboB_Temp_NOS : 52|1@1+ (1,0) [0|1] "" Vector__XXX
 SG_ APSB_w182_TurboB_SMSLockStepErr : 53|1@1+ (1,0) [0|1] "" Vector__XXX
 SG_ APSB_w183_TurboB_TMU_Throttle : 54|1@1+ (1,0) [0|1] "" Vector__XXX
 SG_ APSB_w184_TurboB_SMS_WDOG : 55|1@1+ (1,0) [0|1] "" Vector__XXX
 SG_ APSB_w185_TurboB_SCS_LKUP : 56|1@1+ (1,0) [0|1] "" Vector__XXX
 SG_ APSB_w186_TurboB_A72_watchdog : 57|1@1+ (1,0) [0|1] "" Vector__XXX
 SG_ APSB_w187_TurboB_SMS_taskUtilErr : 58|1@1+ (1,0) [0|1] "" Vector__XXX
 SG_ APSB_w188_otherTurboUartMIA : 59|1@1+ (1,0) [0|1] "" Vector__XXX
 SG_ APSB_w189_vcfrontMiaPartyBus : 60|1@1+ (1,0) [0|1] "" Vector__XXX
 SG_ APSB_w190_iboosterMia : 61|1@1+ (1,0) [0|1] "" Vector__XXX
 SG_ APSB_w191_timesyncError : 62|1@1+ (1,0) [0|1] "" Vector__XXX
 SG_ APSB_w192_CANFault : 63|1@1+ (1,0) [0|1] "" Vector__XXX

BO_ 976 APSB_warningMatrix3: 8 APSB
 SG_ APSB_w193_camWindshieldUnclean : 0|1@1+ (1,0) [0|1] "" Vector__XXX
 SG_ APSB_w194_accDriverResumeRqrd : 1|1@1+ (1,0) [0|1] "" Vector__XXX
 SG_ APSB_w195_scwUnavailable : 2|1@1+ (1,0) [0|1] "" Vector__XXX
 SG_ APSB_w196_stopSignWarning : 3|1@1+ (1,0) [0|1] "" Vector__XXX
 SG_ APSB_w197_redLightWarning : 4|1@1+ (1,0) [0|1] "" Vector__XXX
 SG_ APSB_w198_tsrUnavailable : 5|1@1+ (1,0) [0|1] "" Vector__XXX
 SG_ APSB_w199_apcAbort : 6|1@1+ (1,0) [0|1] "" Vector__XXX
 SG_ APSB_w200_lcSlowdown : 7|1@1+ (1,0) [0|1] "" Vector__XXX
 SG_ APSB_w201_lcAborting : 8|1@1+ (1,0) [0|1] "" Vector__XXX
 SG_ APSB_w202_scwNoisyEnvironment : 9|1@1+ (1,0) [0|1] "" Vector__XXX
 SG_ APSB_w203_apcActivation : 10|1@1+ (1,0) [0|1] "" Vector__XXX
 SG_ APSB_w204_apcFinalFront : 11|1@1+ (1,0) [0|1] "" Vector__XXX
 SG_ APSB_w205_apcFinalRear : 12|1@1+ (1,0) [0|1] "" Vector__XXX
 SG_ APSB_w206_autosteerNotEnabled : 13|1@1+ (1,0) [0|1] "" Vector__XXX
 SG_ APSB_w207_autosteerUnavailable : 14|1@1+ (1,0) [0|1] "" Vector__XXX
 SG_ APSB_w208_rackDetected : 15|1@1+ (1,0) [0|1] "" Vector__XXX
 SG_ APSB_w209_autoSummonRequest : 16|1@1+ (1,0) [0|1] "" Vector__XXX
 SG_ APSB_w210_camObstrcted : 17|1@1+ (1,0) [0|1] "" Vector__XXX
 SG_ APSB_w211_accNoSeatBelt : 18|1@1+ (1,0) [0|1] "" Vector__XXX
 SG_ APSB_w212_lcUnavailableStrikeOut : 19|1@1+ (1,0) [0|1] "" Vector__XXX
 SG_ APSB_w213_autosteerStruckOut : 20|1@1+ (1,0) [0|1] "" Vector__XXX
 SG_ APSB_w214_driverNotIntracting : 21|1@1+ (1,0) [0|1] "" Vector__XXX
 SG_ APSB_w215_contDriverNotIntractin : 22|1@1+ (1,0) [0|1] "" Vector__XXX
 SG_ APSB_w216_driverOverriding : 23|1@1+ (1,0) [0|1] "" Vector__XXX
 SG_ APSB_w217_lcUnavailableSpeeding : 24|1@1+ (1,0) [0|1] "" Vector__XXX
 SG_ APSB_w218_lcSpeedExceededLimit : 25|1@1+ (1,0) [0|1] "" Vector__XXX
 SG_ APSB_w219_lcTempUnavailableSpeed : 26|1@1+ (1,0) [0|1] "" Vector__XXX
 SG_ APSB_w220_lcTempUnavailableRoad : 27|1@1+ (1,0) [0|1] "" Vector__XXX
 SG_ APSB_w221_accRadarBlind : 28|1@1+ (1,0) [0|1] "" Vector__XXX
 SG_ APSB_w222_accCameraBlind : 29|1@1+ (1,0) [0|1] "" Vector__XXX
 SG_ APSB_w223_accObjectInPath : 30|1@1+ (1,0) [0|1] "" Vector__XXX
 SG_ APSB_w224_accCameraCalibration : 31|1@1+ (1,0) [0|1] "" Vector__XXX
 SG_ APSB_w225_lcDegradedVisSpeedLmt : 32|1@1+ (1,0) [0|1] "" Vector__XXX
 SG_ APSB_w226_lcCamCalNeededSpeedLmt : 33|1@1+ (1,0) [0|1] "" Vector__XXX
 SG_ APSB_w227_virtualWallBlocked : 34|1@1+ (1,0) [0|1] "" Vector__XXX
 SG_ APSB_w228_DEPRECATED : 35|1@1+ (1,0) [0|1] "" Vector__XXX
 SG_ APSB_w229_alcUltrasoundDamaged : 36|1@1+ (1,0) [0|1] "" Vector__XXX
 SG_ APSB_w230_alcUltrasoundBlocked : 37|1@1+ (1,0) [0|1] "" Vector__XXX
 SG_ APSB_w231_idfEvent : 38|1@1+ (1,0) [0|1] "" Vector__XXX
 SG_ APSB_w232_laneChangeRequested : 39|1@1+ (1,0) [0|1] "" Vector__XXX
 SG_ APSB_w235_a72LoopDetected : 42|1@1+ (1,0) [0|1] "" Vector__XXX
 SG_ APSB_w236_canSharedMemError : 43|1@1+ (1,0) [0|1] "" Vector__XXX
 SG_ APSB_w237_faultMgrEventDetected : 44|1@1+ (1,0) [0|1] "" Vector__XXX
 SG_ APSB_w238_resetReason : 45|1@1+ (1,0) [0|1] "" Vector__XXX
 SG_ APSB_w241_ddrInitFailures : 48|1@1+ (1,0) [0|1] "" Vector__XXX
 SG_ APSB_w242_tripMBISTFailure : 49|1@1+ (1,0) [0|1] "" Vector__XXX
 SG_ APSB_w243_tripHWErrorStatus : 50|1@1+ (1,0) [0|1] "" Vector__XXX
 SG_ APSB_w244_gpuHWFaultStatus : 51|1@1+ (1,0) [0|1] "" Vector__XXX
 SG_ APSB_w245_eloopRxFromUnexpectedS : 52|1@1+ (1,0) [0|1] "" Vector__XXX
 SG_ APSB_w246_ethloopSwitchPortLinkD : 53|1@1+ (1,0) [0|1] "" Vector__XXX
 SG_ APSB_w247_ethernetFrameError : 54|1@1+ (1,0) [0|1] "" Vector__XXX
 SG_ APSB_w248_ethloopSwitchPoorSqi : 55|1@1+ (1,0) [0|1] "" Vector__XXX
 SG_ APSB_w249_ufsFailures : 56|1@1+ (1,0) [0|1] "" Vector__XXX
 SG_ APSB_w250_ethloopSwitchMemUsageT : 57|1@1+ (1,0) [0|1] "" Vector__XXX
 SG_ APSB_w251_ethloopSwitchMemUsageT : 58|1@1+ (1,0) [0|1] "" Vector__XXX
 SG_ APSB_w252_ethSwitchPortLinkDown : 59|1@1+ (1,0) [0|1] "" Vector__XXX
 SG_ APSB_w253_powerStateTimeout : 60|1@1+ (1,0) [0|1] "" Vector__XXX
 SG_ APSB_w254_sleepStateTimeout : 61|1@1+ (1,0) [0|1] "" Vector__XXX
 SG_ APSB_w255_bootHealth : 62|1@1+ (1,0) [0|1] "" Vector__XXX

BO_ 1003 APSB_warningMatrix4: 8 APSB
 SG_ APSB_w257_assertFailure : 0|1@1+ (1,0) [0|1] "" Vector__XXX
 SG_ APSB_w258_qspiFlashSectorChecksu : 1|1@1+ (1,0) [0|1] "" Vector__XXX
 SG_ APSB_w259_qspiFailure : 2|1@1+ (1,0) [0|1] "" Vector__XXX
 SG_ APSB_w260_pgoodFailure : 3|1@1+ (1,0) [0|1] "" Vector__XXX
 SG_ APSB_w261_vrmFaultGrpA : 4|1@1+ (1,0) [0|1] "" Vector__XXX
 SG_ APSB_w262_vrmFaultGrpB : 5|1@1+ (1,0) [0|1] "" Vector__XXX
 SG_ APSB_w263_vrmFaultGrpC : 6|1@1+ (1,0) [0|1] "" Vector__XXX
 SG_ APSB_w264_ddrPhy0Failures : 7|1@1+ (1,0) [0|1] "" Vector__XXX
 SG_ APSB_w265_ddrPhy1Failures : 8|1@1+ (1,0) [0|1] "" Vector__XXX
 SG_ APSB_w266_ddrPhy2Failures : 9|1@1+ (1,0) [0|1] "" Vector__XXX
 SG_ APSB_w267_ddrPhy3Failures : 10|1@1+ (1,0) [0|1] "" Vector__XXX
 SG_ APSB_w268_ddrControllerFailures : 11|1@1+ (1,0) [0|1] "" Vector__XXX
 SG_ APSB_w269_ethSwitchRxPageCountTo : 12|1@1+ (1,0) [0|1] "" Vector__XXX
 SG_ APSB_w270_ethSwitchRxPageCountTo : 13|1@1+ (1,0) [0|1] "" Vector__XXX
 SG_ APSB_w271_ddrScheduler0EccErrors : 14|1@1+ (1,0) [0|1] "" Vector__XXX
 SG_ APSB_w272_ddrScheduler1EccErrors : 15|1@1+ (1,0) [0|1] "" Vector__XXX
 SG_ APSB_w273_ddrScheduler2EccErrors : 16|1@1+ (1,0) [0|1] "" Vector__XXX
 SG_ APSB_w274_ddrScheduler3EccErrors : 17|1@1+ (1,0) [0|1] "" Vector__XXX
 SG_ APSB_w275_ddrScheduler4EccErrors : 18|1@1+ (1,0) [0|1] "" Vector__XXX
 SG_ APSB_w276_ddrScheduler5EccErrors : 19|1@1+ (1,0) [0|1] "" Vector__XXX
 SG_ APSB_w277_ddrScheduler6EccErrors : 20|1@1+ (1,0) [0|1] "" Vector__XXX
 SG_ APSB_w278_ddrScheduler7EccErrors : 21|1@1+ (1,0) [0|1] "" Vector__XXX
 SG_ APSB_w279_ufsPartitionError : 22|1@1+ (1,0) [0|1] "" Vector__XXX
 SG_ APSB_w280_pepsMia : 23|1@1+ (1,0) [0|1] "" Vector__XXX
 SG_ APSB_w281_rsaMia : 24|1@1+ (1,0) [0|1] "" Vector__XXX
 SG_ APSB_w282_smmuError : 25|1@1+ (1,0) [0|1] "" Vector__XXX
 SG_ APSB_w283_psfaMia : 26|1@1+ (1,0) [0|1] "" Vector__XXX
 SG_ APSB_w284_cam12VBuckBoostAPwrIss : 27|1@1+ (1,0) [0|1] "" Vector__XXX
 SG_ APSB_w285_cam12VBuckBoostBPwrIss : 28|1@1+ (1,0) [0|1] "" Vector__XXX
 SG_ APSB_w286_cam12VEFuseAPrimaryIss : 29|1@1+ (1,0) [0|1] "" Vector__XXX
 SG_ APSB_w287_cam12VEFuseASecondaryI : 30|1@1+ (1,0) [0|1] "" Vector__XXX
 SG_ APSB_w288_brakeboosterMia : 31|1@1+ (1,0) [0|1] "" Vector__XXX
 SG_ APSB_w289_turboTemperatureWarnin : 32|1@1+ (1,0) [0|1] "" Vector__XXX
 SG_ APSB_w290_cam12VBuckBoostBPwrRin : 33|1@1+ (1,0) [0|1] "" Vector__XXX
 SG_ APSB_w291_eplannerError : 34|1@1+ (1,0) [0|1] "" Vector__XXX
 SG_ APSB_w292_CH_busOff : 35|1@1+ (1,0) [0|1] "" Vector__XXX
 SG_ APSB_w293_PARTY_busOff : 36|1@1+ (1,0) [0|1] "" Vector__XXX
 SG_ APSB_w294_VEH_busOff : 37|1@1+ (1,0) [0|1] "" Vector__XXX
 SG_ APSB_w295_PT_busOff : 38|1@1+ (1,0) [0|1] "" Vector__XXX
 SG_ APSB_w296_wdogMonTaskDeadlineMis : 39|1@1+ (1,0) [0|1] "" Vector__XXX
 SG_ APSB_w297_earlyWDogAlert : 40|1@1+ (1,0) [0|1] "" Vector__XXX
 SG_ APSB_w298_cpuToApCanSharedMemErr : 41|1@1+ (1,0) [0|1] "" Vector__XXX
 SG_ APSB_w299_apToCpuCanSharedMemErr : 42|1@1+ (1,0) [0|1] "" Vector__XXX
 SG_ APSB_w300_sharedMemoryAccessErro : 43|1@1+ (1,0) [0|1] "" Vector__XXX
 SG_ APSB_w301_nocTimeoutDetected : 44|1@1+ (1,0) [0|1] "" Vector__XXX
 SG_ APSB_w302_canAPShmFifoFull : 45|1@1+ (1,0) [0|1] "" Vector__XXX
 SG_ APSB_w303_canAPShmFifoEmpty : 46|1@1+ (1,0) [0|1] "" Vector__XXX
 SG_ APSB_w304_dataAbort : 47|1@1+ (1,0) [0|1] "" Vector__XXX
 SG_ APSB_w305_gpsPgoodFailure : 48|1@1+ (1,0) [0|1] "" Vector__XXX
 SG_ APSB_w306_ethPgoodFailure : 49|1@1+ (1,0) [0|1] "" Vector__XXX
 SG_ APSB_w307_eccEventDetected : 50|1@1+ (1,0) [0|1] "" Vector__XXX
 SG_ APSB_w308_pmicErrorDetected : 51|1@1+ (1,0) [0|1] "" Vector__XXX
 SG_ APSB_w309_ethBridgeDown : 52|1@1+ (1,0) [0|1] "" Vector__XXX
 SG_ APSB_w310_wakeBootMetrics : 53|1@1+ (1,0) [0|1] "" Vector__XXX
 SG_ APSB_w311_apbdgDasMia : 54|1@1+ (1,0) [0|1] "" Vector__XXX
 SG_ APSB_w312_apbdgApMia : 55|1@1+ (1,0) [0|1] "" Vector__XXX
 SG_ APSB_w313_BDY_busOff : 56|1@1+ (1,0) [0|1] "" Vector__XXX
 SG_ APSB_w315_epas3pMiaBdyBus : 58|1@1+ (1,0) [0|1] "" Vector__XXX
 SG_ APSB_w316_apBootHealth : 59|1@1+ (1,0) [0|1] "" Vector__XXX
 SG_ APSB_w317_uiMia : 60|1@1+ (1,0) [0|1] "" Vector__XXX
 SG_ APSB_w318_ethernetNetworkBufferH : 61|1@1+ (1,0) [0|1] "" Vector__XXX
 SG_ APSB_w319_vehDasImposterDetected : 62|1@1+ (1,0) [0|1] "" Vector__XXX
 SG_ APSB_w320_eplannerPreconditionsM : 63|1@1+ (1,0) [0|1] "" Vector__XXX

BO_TX_BU_ 1482 : APSB;
BO_TX_BU_ 731 : APSB;
BO_TX_BU_ 992 : APSB;
BO_TX_BU_ 1864 : APSB;
BO_TX_BU_ 971 : APSB;
BO_TX_BU_ 845 : APSB;
BO_TX_BU_ 1143 : APSB;
BO_TX_BU_ 942 : APSB;
BO_TX_BU_ 976 : APSB;
BO_TX_BU_ 1003 : APSB;
CM_ BO_ 1482 "APSB ECU message: alert log";
CM_ SG_ 1482 APSB_alertID "APSB ECU: alert ID";
CM_ SG_ 1482 APSB_alertSource "APSB ECU: alert source";
CM_ SG_ 1482 APSB_alertState "APSB ECU: alert state";
CM_ SG_ 1482 APSB_sw010_a04calibNotDone "APSB ECU: sw010 a04calib not done";
CM_ SG_ 1482 APSB_sw010_a05calibReqd "APSB ECU: sw010 a05calib reqd";
CM_ SG_ 1482 APSB_sw010_a06calibNotOK "APSB ECU: sw010 a06calib not OK";
CM_ SG_ 1482 APSB_sw010_a08PlantMode "APSB ECU: sw010 a08 plant mode";
CM_ SG_ 1482 APSB_sw010_HorizontalMisalignmen "APSB ECU: sw010 horizontal misalignment";
CM_ SG_ 1482 APSB_sw010_VerticalMisalignment "APSB ECU: sw010 vertical misalignment";
CM_ SG_ 1482 APSB_sw010_unusedBits "APSB ECU: sw010 unused bits";
CM_ SG_ 1482 APSB_sw010_VmaPlausibility "APSB ECU: sw010 vma plausibility";
CM_ SG_ 1482 APSB_sw019_taskId "APSB ECU: sw019 task id";
CM_ SG_ 1482 APSB_sw019_numFreeBytes "APSB ECU: sw019 num free bytes";
CM_ SG_ 1482 APSB_sw019_timeStamp "APSB ECU: sw019 time stamp";
CM_ SG_ 1482 APSB_sw020_unusedW0 "APSB ECU: sw020 unused W0";
CM_ SG_ 1482 APSB_sw020_unusedW1 "APSB ECU: sw020 unused W1";
CM_ SG_ 1482 APSB_sw020_unusedW2 "APSB ECU: sw020 unused W2";
CM_ SG_ 1482 APSB_sw021_tempSensorId "APSB ECU: sw021 temp sensor id";
CM_ SG_ 1482 APSB_sw021_minThreshold "APSB ECU: sw021 min threshold";
CM_ SG_ 1482 APSB_sw021_maxThreshold "APSB ECU: sw021 max threshold";
CM_ SG_ 1482 APSB_sw021_currentTemperature "APSB ECU: sw021 current temperature";
CM_ SG_ 1482 APSB_sw021_unusedWord "APSB ECU: sw021 unused word";
CM_ SG_ 1482 APSB_sw024_Task_ID "APSB ECU: sw024 task ID";
CM_ SG_ 1482 APSB_sw024_numVirtualLaneVeh "APSB ECU: sw024 num virtual lane veh";
CM_ SG_ 1482 APSB_sw024_currentVehicleApp "APSB ECU: sw024 current vehicle app";
CM_ SG_ 1482 APSB_sw024_taskProgramCounter "APSB ECU: sw024 task program counter";
CM_ SG_ 1482 APSB_sw027_JTAG_Reset "APSB ECU: sw027 JTAG reset";
CM_ SG_ 1482 APSB_sw027_Core_Reset "APSB ECU: sw027 core reset";
CM_ SG_ 1482 APSB_sw027_Unused_Bit_0 "APSB ECU: sw027 unused bit 0";
CM_ SG_ 1482 APSB_sw027_CPU_Checkstop_Error "APSB ECU: sw027 CPU checkstop error";
CM_ SG_ 1482 APSB_sw027_PLL_0_Failure "APSB ECU: sw027 PLL 0 failure";
CM_ SG_ 1482 APSB_sw027_Clock_Monitor_0_Low "APSB ECU: sw027 clock monitor 0 low";
CM_ SG_ 1482 APSB_sw027_Clock_Monitor_0_Off "APSB ECU: sw027 clock monitor 0 off";
CM_ SG_ 1482 APSB_sw027_LVD_4v5 "APSB ECU: sw027 LVD 4v5";
CM_ SG_ 1482 APSB_sw027_Flash_Fatal_Error "APSB ECU: sw027 flash fatal error";
CM_ SG_ 1482 APSB_sw027_PLL_1_Failure "APSB ECU: sw027 PLL 1 failure";
CM_ SG_ 1482 APSB_sw027_Unused_Bit_1 "APSB ECU: sw027 unused bit 1";
CM_ SG_ 1482 APSB_sw027_f_PLL_1_Off "APSB ECU: sw027 f PLL 1 off";
CM_ SG_ 1482 APSB_sw027_Unused_Nibble "APSB ECU: sw027 unused nibble";
CM_ SG_ 1482 APSB_sw027_LVD_1v2 "APSB ECU: sw027 LVD 1v2";
CM_ SG_ 1482 APSB_sw027_Unused_Bit_2 "APSB ECU: sw027 unused bit 2";
CM_ SG_ 1482 APSB_sw027_Watchdog "APSB ECU: sw027 watchdog";
CM_ SG_ 1482 APSB_sw027_Unused_Bit_3 "APSB ECU: sw027 unused bit 3";
CM_ SG_ 1482 APSB_sw027_LVD_2v7_VREG "APSB ECU: sw027 LVD 2v7 VREG";
CM_ SG_ 1482 APSB_sw027_LVD_2v7_Flash "APSB ECU: sw027 LVD 2v7 flash";
CM_ SG_ 1482 APSB_sw027_LVD_2v7_IO "APSB ECU: sw027 LVD 2v7 IO";
CM_ SG_ 1482 APSB_sw027_Unused_Bit_4 "APSB ECU: sw027 unused bit 4";
CM_ SG_ 1482 APSB_sw027_Unused_Byte "APSB ECU: sw027 unused byte";
CM_ SG_ 1482 APSB_sw027_ESR0 "APSB ECU: sw027 ESR0";
CM_ SG_ 1482 APSB_sw027_ESR1 "APSB ECU: sw027 ESR1";
CM_ SG_ 1482 APSB_sw027_SW "APSB ECU: sw027 SW";
CM_ SG_ 1482 APSB_sw027_STM0 "APSB ECU: sw027 STM0";
CM_ SG_ 1482 APSB_sw027_STM1 "APSB ECU: sw027 STM1";
CM_ SG_ 1482 APSB_sw027_STM2 "APSB ECU: sw027 STM2";
CM_ SG_ 1482 APSB_sw027_CBS_SYSTEM "APSB ECU: sw027 CBS SYSTEM";
CM_ SG_ 1482 APSB_sw027_CBS_DEBUG "APSB ECU: sw027 CBS DEBUG";
CM_ SG_ 1482 APSB_sw027_CBS_APP "APSB ECU: sw027 CBS APP";
CM_ SG_ 1482 APSB_sw027_EVR13 "APSB ECU: sw027 EVR13";
CM_ SG_ 1482 APSB_sw027_EVR33 "APSB ECU: sw027 EVR33";
CM_ SG_ 1482 APSB_sw027_SWD "APSB ECU: sw027 SWD";
CM_ SG_ 1482 APSB_sw027_STDBY_WDG "APSB ECU: sw027 STDBY WDG";
CM_ SG_ 1482 APSB_sw027_PORST "APSB ECU: sw027 PORST";
CM_ SG_ 1482 APSB_sw027_Unused_word "APSB ECU: sw027 unused word";
CM_ SG_ 1482 APSB_sw030_heaterState "APSB ECU: sw030 heater state";
CM_ SG_ 1482 APSB_sw030_unusedByte "APSB ECU: sw030 unused byte";
CM_ SG_ 1482 APSB_sw030_unusedW0 "APSB ECU: sw030 unused W0";
CM_ SG_ 1482 APSB_sw030_unusedW1 "APSB ECU: sw030 unused W1";
CM_ SG_ 1482 APSB_sw033_carConfig "APSB ECU: sw033 car config";
CM_ SG_ 1482 APSB_sw033_chNm "APSB ECU: sw033 ch nm";
CM_ SG_ 1482 APSB_sw033_vin "APSB ECU: sw033 vin";
CM_ SG_ 1482 APSB_sw033_carState "APSB ECU: sw033 car state";
CM_ SG_ 1482 APSB_sw034_sccmMia "APSB ECU: sw034 sccm mia";
CM_ SG_ 1482 APSB_sw034_unusedByte "APSB ECU: sw034 unused byte";
CM_ SG_ 1482 APSB_sw034_unusedW0 "APSB ECU: sw034 unused W0";
CM_ SG_ 1482 APSB_sw034_unusedW1 "APSB ECU: sw034 unused W1";
CM_ SG_ 1482 APSB_sw035_wheelSpeeds "APSB ECU: sw035 wheel speeds";
CM_ SG_ 1482 APSB_sw035_status "APSB ECU: sw035 status";
CM_ SG_ 1482 APSB_sw035_wheelRotation "APSB ECU: sw035 wheel rotation";
CM_ SG_ 1482 APSB_sw035_redundantBrakingStatu "APSB ECU: sw035 redundant braking status";
CM_ SG_ 1482 APSB_sw036_bdyMia "APSB ECU: sw036 bdy mia";
CM_ SG_ 1482 APSB_sw036_unusedByte "APSB ECU: sw036 unused byte";
CM_ SG_ 1482 APSB_sw036_unusedW0 "APSB ECU: sw036 unused W0";
CM_ SG_ 1482 APSB_sw036_unusedW1 "APSB ECU: sw036 unused W1";
CM_ SG_ 1482 APSB_sw039_sdm_rcm_Mia "APSB ECU: sw039 sdm rcm mia";
CM_ SG_ 1482 APSB_sw039_unusedByte "APSB ECU: sw039 unused byte";
CM_ SG_ 1482 APSB_sw039_unusedW0 "APSB ECU: sw039 unused W0";
CM_ SG_ 1482 APSB_sw039_unusedW1 "APSB ECU: sw039 unused W1";
CM_ SG_ 1482 APSB_sw045_radMia "APSB ECU: sw045 rad mia";
CM_ SG_ 1482 APSB_sw045_unusedByte "APSB ECU: sw045 unused byte";
CM_ SG_ 1482 APSB_sw045_unusedW0 "APSB ECU: sw045 unused W0";
CM_ SG_ 1482 APSB_sw045_unusedW1 "APSB ECU: sw045 unused W1";
CM_ SG_ 1482 APSB_sw048_swAssert "APSB ECU: sw048 sw assert";
CM_ SG_ 1482 APSB_sw048_thermalIssue "APSB ECU: sw048 thermal issue";
CM_ SG_ 1482 APSB_sw048_powerIssue "APSB ECU: sw048 power issue";
CM_ SG_ 1482 APSB_sw048_stackOverflow "APSB ECU: sw048 stack overflow";
CM_ SG_ 1482 APSB_sw048_checkStop "APSB ECU: sw048 check stop";
CM_ SG_ 1482 APSB_sw048_ecuWatchdog "APSB ECU: sw048 ecu watchdog";
CM_ SG_ 1482 APSB_sw048_ecuReset "APSB ECU: sw048 ecu reset";
CM_ SG_ 1482 APSB_sw048_radcVersionMismatch "APSB ECU: sw048 radc version mismatch";
CM_ SG_ 1482 APSB_sw048_radcCalibration "APSB ECU: sw048 radc calibration";
CM_ SG_ 1482 APSB_sw048_radcMia "APSB ECU: sw048 radc mia";
CM_ SG_ 1482 APSB_sw048_eyeQVersionMismatch "APSB ECU: sw048 eye q version mismatch";
CM_ SG_ 1482 APSB_sw048_camIssue "APSB ECU: sw048 cam issue";
CM_ SG_ 1482 APSB_sw048_parkerIssue "APSB ECU: sw048 parker issue";
CM_ SG_ 1482 APSB_sw048_prolongedUiMia "APSB ECU: sw048 prolonged ui mia";
CM_ SG_ 1482 APSB_sw048_uiMiaAtBootup "APSB ECU: sw048 ui mia at bootup";
CM_ SG_ 1482 APSB_sw051_a01ecuInternalPerf "APSB ECU: sw051 a01ecu internal perf";
CM_ SG_ 1482 APSB_sw051_a02flashPerformance "APSB ECU: sw051 a02flash performance";
CM_ SG_ 1482 APSB_sw051_a03vBatHigh "APSB ECU: sw051 a03v bat high";
CM_ SG_ 1482 APSB_sw051_a09configMismatch "APSB ECU: sw051 a09config mismatch";
CM_ SG_ 1482 APSB_sw051_a52radomeHtrInop "APSB ECU: sw051 a52radome htr inop";
CM_ SG_ 1482 APSB_sw051_unused "APSB ECU: sw051 unused";
CM_ SG_ 1482 APSB_sw051_SCUTemperature "APSB ECU: sw051 SCU temperature";
CM_ SG_ 1482 APSB_sw051_HWFail "APSB ECU: sw051 HW fail";
CM_ SG_ 1482 APSB_sw051_SGUFail "APSB ECU: sw051 SGU fail";
CM_ SG_ 1482 APSB_sw051_unusedBits "APSB ECU: sw051 unused bits";
CM_ SG_ 1482 APSB_sw051_unusedB0 "APSB ECU: sw051 unused B0";
CM_ SG_ 1482 APSB_sw051_unusedW1 "APSB ECU: sw051 unused W1";
CM_ SG_ 1482 APSB_sw052_a07sensorBlinded "APSB ECU: sw052 a07sensor blinded";
CM_ SG_ 1482 APSB_sw052_sensorDirty "APSB ECU: sw052 sensor dirty";
CM_ SG_ 1482 APSB_sw052_HWFail "APSB ECU: sw052 HW fail";
CM_ SG_ 1482 APSB_sw052_overTemperature "APSB ECU: sw052 over temperature";
CM_ SG_ 1482 APSB_sw052_underTemperature "APSB ECU: sw052 under temperature";
CM_ SG_ 1482 APSB_sw052_chirpError "APSB ECU: sw052 chirp error";
CM_ SG_ 1482 APSB_sw052_rspError "APSB ECU: sw052 rsp error";
CM_ SG_ 1482 APSB_sw052_sensorBlocked "APSB ECU: sw052 sensor blocked";
CM_ SG_ 1482 APSB_sw053_a10canBusOff "APSB ECU: sw053 a10can bus off";
CM_ SG_ 1482 APSB_sw053_a11bdyMIA "APSB ECU: sw053 a11bdy MIA";
CM_ SG_ 1482 APSB_sw053_a12espMIA "APSB ECU: sw053 a12esp MIA";
CM_ SG_ 1482 APSB_sw053_a13gtwMIA "APSB ECU: sw053 a13gtw MIA";
CM_ SG_ 1482 APSB_sw053_a14sccmMIA "APSB ECU: sw053 a14sccm MIA";
CM_ SG_ 1482 APSB_sw053_a15adasMIA "APSB ECU: sw053 a15adas MIA";
CM_ SG_ 1482 APSB_sw053_a16bdyInvalidCount "APSB ECU: sw053 a16bdy invalid count";
CM_ SG_ 1482 APSB_sw053_a17adasInvalidCount "APSB ECU: sw053 a17adas invalid count";
CM_ SG_ 1482 APSB_sw053_a18espInvalidCount "APSB ECU: sw053 a18esp invalid count";
CM_ SG_ 1482 APSB_sw053_a19sccmInvalidCount "APSB ECU: sw053 a19sccm invalid count";
CM_ SG_ 1482 APSB_sw053_a20bdyInvalidChkSm "APSB ECU: sw053 a20bdy invalid chk sm";
CM_ SG_ 1482 APSB_sw053_a21espInvalidChkSm "APSB ECU: sw053 a21esp invalid chk sm";
CM_ SG_ 1482 APSB_sw053_a22sccmInvalidChkSm "APSB ECU: sw053 a22sccm invalid chk sm";
CM_ SG_ 1482 APSB_sw053_a23sccmInvalidChkSm "APSB ECU: sw053 a23sccm invalid chk sm";
CM_ SG_ 1482 APSB_sw053_a24absValidity "APSB ECU: sw053 a24abs validity";
CM_ SG_ 1482 APSB_sw053_a25ambTValidity "APSB ECU: sw053 a25amb t validity";
CM_ SG_ 1482 APSB_sw053_a26brakeValidity "APSB ECU: sw053 a26brake validity";
CM_ SG_ 1482 APSB_sw053_a27CntryCdValidity "APSB ECU: sw053 a27 cntry cd validity";
CM_ SG_ 1482 APSB_sw053_a28espValidity "APSB ECU: sw053 a28esp validity";
CM_ SG_ 1482 APSB_sw053_a29longAccOffValidity "APSB ECU: sw053 a29long acc off validity";
CM_ SG_ 1482 APSB_sw053_a30longAccValidity "APSB ECU: sw053 a30long acc validity";
CM_ SG_ 1482 APSB_sw053_a31odoValidity "APSB ECU: sw053 a31odo validity";
CM_ SG_ 1482 APSB_sw053_a32gearValidity "APSB ECU: sw053 a32gear validity";
CM_ SG_ 1482 APSB_sw053_a33steerAngValidity "APSB ECU: sw053 a33steer ang validity";
CM_ SG_ 1482 APSB_sw053_a34steerAngSpdValidit "APSB ECU: sw053 a34steer ang spd validity";
CM_ SG_ 1482 APSB_sw053_a35indctrValidity "APSB ECU: sw053 a35indctr validity";
CM_ SG_ 1482 APSB_sw053_a36vehStndStllValidty "APSB ECU: sw053 a36veh stnd stll validty";
CM_ SG_ 1482 APSB_sw053_a37vinValidity "APSB ECU: sw053 a37vin validity";
CM_ SG_ 1482 APSB_sw053_a38whlRotValidity "APSB ECU: sw053 a38whl rot validity";
CM_ SG_ 1482 APSB_sw053_a39whlSpdValidity "APSB ECU: sw053 a39whl spd validity";
CM_ SG_ 1482 APSB_sw053_a40whlStndStllValidty "APSB ECU: sw053 a40whl stnd stll validty";
CM_ SG_ 1482 APSB_sw053_a41wiperValidity "APSB ECU: sw053 a41wiper validity";
CM_ SG_ 1482 APSB_sw053_a42xwdValidity "APSB ECU: sw053 a42xwd validity";
CM_ SG_ 1482 APSB_sw053_a43yawOffValidity "APSB ECU: sw053 a43yaw off validity";
CM_ SG_ 1482 APSB_sw053_a44yawValidity "APSB ECU: sw053 a44yaw validity";
CM_ SG_ 1482 APSB_sw053_a48steerAngOffSanity "APSB ECU: sw053 a48steer ang off sanity";
CM_ SG_ 1482 APSB_sw053_a49tireSizeSanity "APSB ECU: sw053 a49tire size sanity";
CM_ SG_ 1482 APSB_sw053_a50velocitySanity "APSB ECU: sw053 a50velocity sanity";
CM_ SG_ 1482 APSB_sw053_a51yawSanity "APSB ECU: sw053 a51yaw sanity";
CM_ SG_ 1482 APSB_sw053_a53espmodValidity "APSB ECU: sw053 a53espmod validity";
CM_ SG_ 1482 APSB_sw053_a54gtwmodValidity "APSB ECU: sw053 a54gtwmod validity";
CM_ SG_ 1482 APSB_sw053_a55stwmodValidity "APSB ECU: sw053 a55stwmod validity";
CM_ SG_ 1482 APSB_sw053_a56bcmodValidity "APSB ECU: sw053 a56bcmod validity";
CM_ SG_ 1482 APSB_sw053_a57dimodValidity "APSB ECU: sw053 a57dimod validity";
CM_ SG_ 1482 APSB_sw053_a59drmiInvalidChkSm "APSB ECU: sw053 a59drmi invalid chk sm";
CM_ SG_ 1482 APSB_sw053_a60drmiInvalidCount "APSB ECU: sw053 a60drmi invalid count";
CM_ SG_ 1482 APSB_sw053_a61radPositionMismatc "APSB ECU: sw053 a61rad position mismatch";
CM_ SG_ 1482 APSB_sw053_a62strRackMismatch "APSB ECU: sw053 a62str rack mismatch";
CM_ SG_ 1482 APSB_sw055_detectedRadcVersion "APSB ECU: sw055 detected radc version";
CM_ SG_ 1482 APSB_sw055_expectedCrcLsw "APSB ECU: sw055 expected crc lsw";
CM_ SG_ 1482 APSB_sw056_diMia "APSB ECU: sw056 di mia";
CM_ SG_ 1482 APSB_sw056_unusedByte "APSB ECU: sw056 unused byte";
CM_ SG_ 1482 APSB_sw056_unusedW0 "APSB ECU: sw056 unused W0";
CM_ SG_ 1482 APSB_sw056_unusedW1 "APSB ECU: sw056 unused W1";
CM_ SG_ 1482 APSB_sw058_epbMia "APSB ECU: sw058 epb mia";
CM_ SG_ 1482 APSB_sw058_unusedByte "APSB ECU: sw058 unused byte";
CM_ SG_ 1482 APSB_sw058_unusedW0 "APSB ECU: sw058 unused W0";
CM_ SG_ 1482 APSB_sw058_unusedW1 "APSB ECU: sw058 unused W1";
CM_ SG_ 1482 APSB_sw059_sdiFront "APSB ECU: sw059 sdi front";
CM_ SG_ 1482 APSB_sw059_sdiRear "APSB ECU: sw059 sdi rear";
CM_ SG_ 1482 APSB_sw059_status "APSB ECU: sw059 status";
CM_ SG_ 1482 APSB_sw059_sensorStatusFront "APSB ECU: sw059 sensor status front";
CM_ SG_ 1482 APSB_sw059_pasFrontMiddle "APSB ECU: sw059 pas front middle";
CM_ SG_ 1482 APSB_sw059_sensorStatusRear "APSB ECU: sw059 sensor status rear";
CM_ SG_ 1482 APSB_sw059_pasRearMiddle "APSB ECU: sw059 pas rear middle";
CM_ SG_ 1482 APSB_sw059_pscStatus "APSB ECU: sw059 psc status";
CM_ SG_ 1482 APSB_sw059_pscVehSlot "APSB ECU: sw059 psc veh slot";
CM_ SG_ 1482 APSB_sw059_status2 "APSB ECU: sw059 status2";
CM_ SG_ 1482 APSB_sw059_oloDict "APSB ECU: sw059 olo dict";
CM_ SG_ 1482 APSB_sw059_oocStatus "APSB ECU: sw059 ooc status";
CM_ SG_ 1482 APSB_sw061_states "APSB ECU: sw061 states";
CM_ SG_ 1482 APSB_sw063_expectedMajorVer "APSB ECU: sw063 expected major ver";
CM_ SG_ 1482 APSB_sw063_detectedMajorVer "APSB ECU: sw063 detected major ver";
CM_ SG_ 1482 APSB_sw063_expectedMinorVer "APSB ECU: sw063 expected minor ver";
CM_ SG_ 1482 APSB_sw063_detectedMinorVer "APSB ECU: sw063 detected minor ver";
CM_ SG_ 1482 APSB_sw063_expectedSubMinorVer "APSB ECU: sw063 expected sub minor ver";
CM_ SG_ 1482 APSB_sw063_detectedSubMinorVer "APSB ECU: sw063 detected sub minor ver";
CM_ SG_ 1482 APSB_sw064_sysStatus "APSB ECU: sw064 sys status";
CM_ SG_ 1482 APSB_sw064_status "APSB ECU: sw064 status";
CM_ SG_ 1482 APSB_sw070_currTireFitment "APSB ECU: sw070 curr tire fitment";
CM_ SG_ 1482 APSB_sw070_lastTireFitment "APSB ECU: sw070 last tire fitment";
CM_ SG_ 1482 APSB_sw070_diGear "APSB ECU: sw070 di gear";
CM_ SG_ 1482 APSB_sw070_driveRail "APSB ECU: sw070 drive rail";
CM_ SG_ 1482 APSB_sw070_accRail "APSB ECU: sw070 acc rail";
CM_ SG_ 1482 APSB_sw070_temperature "APSB ECU: sw070 temperature";
CM_ SG_ 1482 APSB_sw070_currentSpeed "APSB ECU: sw070 current speed";
CM_ SG_ 1482 APSB_sw071_selfParkType "APSB ECU: sw071 self park type";
CM_ SG_ 1482 APSB_sw071_endPosX "APSB ECU: sw071 end pos x";
CM_ SG_ 1482 APSB_sw071_endPosY "APSB ECU: sw071 end pos y";
CM_ SG_ 1482 APSB_sw071_roadClass "APSB ECU: sw071 road class";
CM_ SG_ 1482 APSB_sw071_driverPresent "APSB ECU: sw071 driver present";
CM_ SG_ 1482 APSB_sw071_airSuspension "APSB ECU: sw071 air suspension";
CM_ SG_ 1482 APSB_sw071_temperature "APSB ECU: sw071 temperature";
CM_ SG_ 1482 APSB_sw071_activationType "APSB ECU: sw071 activation type";
CM_ SG_ 1482 APSB_sw072_vehicleX "APSB ECU: sw072 vehicle x";
CM_ SG_ 1482 APSB_sw072_vehicleY "APSB ECU: sw072 vehicle y";
CM_ SG_ 1482 APSB_sw072_vehicleHeading "APSB ECU: sw072 vehicle heading";
CM_ SG_ 1482 APSB_sw072_endDistance "APSB ECU: sw072 end distance";
CM_ SG_ 1482 APSB_sw072_guidanceComplete "APSB ECU: sw072 guidance complete";
CM_ SG_ 1482 APSB_sw072_guidanceRunaway "APSB ECU: sw072 guidance runaway";
CM_ SG_ 1482 APSB_sw072_guidanceTimer "APSB ECU: sw072 guidance timer";
CM_ SG_ 1482 APSB_sw072_handlePress "APSB ECU: sw072 handle press";
CM_ SG_ 1482 APSB_sw072_keyfobPress "APSB ECU: sw072 keyfob press";
CM_ SG_ 1482 APSB_sw072_garageOpened "APSB ECU: sw072 garage opened";
CM_ SG_ 1482 APSB_sw072_userTimeout "APSB ECU: sw072 user timeout";
CM_ SG_ 1482 APSB_sw075_scMia "APSB ECU: sw075 sc mia";
CM_ SG_ 1482 APSB_sw075_unusedByte "APSB ECU: sw075 unused byte";
CM_ SG_ 1482 APSB_sw075_unusedW0 "APSB ECU: sw075 unused W0";
CM_ SG_ 1482 APSB_sw075_unusedW1 "APSB ECU: sw075 unused W1";
CM_ SG_ 1482 APSB_sw077_oocDistance "APSB ECU: sw077 ooc distance";
CM_ SG_ 1482 APSB_sw077_oocConfidence "APSB ECU: sw077 ooc confidence";
CM_ SG_ 1482 APSB_sw077_oocCollisionSide "APSB ECU: sw077 ooc collision side";
CM_ SG_ 1482 APSB_sw077_oocHeight "APSB ECU: sw077 ooc height";
CM_ SG_ 1482 APSB_sw077_vehicleSpeed "APSB ECU: sw077 vehicle speed";
CM_ SG_ 1482 APSB_sw077_oocUntrackedTime "APSB ECU: sw077 ooc untracked time";
CM_ SG_ 1482 APSB_sw077_oocOffCourseDist_cm "APSB ECU: sw077 ooc off course dist cm";
CM_ SG_ 1482 APSB_sw081_radarDistance "APSB ECU: sw081 radar distance";
CM_ SG_ 1482 APSB_sw081_radarTTC "APSB ECU: sw081 radar TTC";
CM_ SG_ 1482 APSB_sw081_cameraDistance "APSB ECU: sw081 camera distance";
CM_ SG_ 1482 APSB_sw081_cameraTTC "APSB ECU: sw081 camera TTC";
CM_ SG_ 1482 APSB_sw081_pedalPosition "APSB ECU: sw081 pedal position";
CM_ SG_ 1482 APSB_sw129_currentVoltage "APSB ECU: sw129 current voltage";
CM_ SG_ 1482 APSB_sw129_maxThreshold "APSB ECU: sw129 max threshold";
CM_ SG_ 1482 APSB_sw129_minThreshold "APSB ECU: sw129 min threshold";
CM_ SG_ 1482 APSB_sw129_powerSequnceError "APSB ECU: sw129 power sequnce error";
CM_ SG_ 1482 APSB_sw129_railControl "APSB ECU: sw129 rail control";
CM_ SG_ 1482 APSB_sw129_railID "APSB ECU: sw129 rail ID";
CM_ SG_ 1482 APSB_sw130_currentTemperature "APSB ECU: sw130 current temperature";
CM_ SG_ 1482 APSB_sw130_maxThreshold "APSB ECU: sw130 max threshold";
CM_ SG_ 1482 APSB_sw130_minThreshold "APSB ECU: sw130 min threshold";
CM_ SG_ 1482 APSB_sw130_tempSensorId "APSB ECU: sw130 temp sensor id";
CM_ SG_ 1482 APSB_sw130_shouldForceApPowerOn "APSB ECU: sw130 should force ap power on";
CM_ SG_ 1482 APSB_sw130_shouldBlockOkToPowerA "APSB ECU: sw130 should block ok to power ap";
CM_ SG_ 1482 APSB_sw132_mismatchType "APSB ECU: sw132 mismatch type";
CM_ SG_ 1482 APSB_sw132_actualHash "APSB ECU: sw132 actual hash";
CM_ SG_ 1482 APSB_sw132_expectedHash "APSB ECU: sw132 expected hash";
CM_ SG_ 1482 APSB_sw133_failedInitStep "APSB ECU: sw133 failed init step";
CM_ SG_ 1482 APSB_sw133_switchInReset "APSB ECU: sw133 switch in reset";
CM_ SG_ 1482 APSB_sw133_phyIsNotRMIIMode "APSB ECU: sw133 phy is not RMII mode";
CM_ SG_ 1482 APSB_sw133_phyInterruptStorm "APSB ECU: sw133 phy interrupt storm";
CM_ SG_ 1482 APSB_sw133_switchEthernetInterLi "APSB ECU: sw133 switch ethernet inter link down";
CM_ SG_ 1482 APSB_sw133_ethSwitchReadFwVerFai "APSB ECU: sw133 eth switch read fw ver failed";
CM_ SG_ 1482 APSB_sw133_ethSwitchFailedToBoot "APSB ECU: sw133 eth switch failed to boot";
CM_ SG_ 1482 APSB_sw133_ethSwitchTimedoutUpda "APSB ECU: sw133 eth switch timedout update";
CM_ SG_ 1482 APSB_sw133_ethSwitchMcuLinkFailo "APSB ECU: sw133 eth switch mcu link failover";
CM_ SG_ 1482 APSB_sw133_ethSwitchMcuLinkDupli "APSB ECU: sw133 eth switch mcu link duplicated";
CM_ SG_ 1482 APSB_sw133_ethSwitchMcuLinkDisco "APSB ECU: sw133 eth switch mcu link disconnected";
CM_ SG_ 1482 APSB_sw133_unused "APSB ECU: sw133 unused";
CM_ SG_ 1482 APSB_sw134_appCamCalibStatus "APSB ECU: sw134 app cam calib status";
CM_ SG_ 1482 APSB_sw134_appCameraLux "APSB ECU: sw134 app camera lux";
CM_ SG_ 1482 APSB_sw134_appInfo "APSB ECU: sw134 app info";
CM_ SG_ 1482 APSB_sw134_appStatus "APSB ECU: sw134 app status";
CM_ SG_ 1482 APSB_sw134_dasAutonomyControlPar "APSB ECU: sw134 das autonomy control party";
CM_ SG_ 1482 APSB_sw134_dasAutonomyControlVeh "APSB ECU: sw134 das autonomy control veh";
CM_ SG_ 1482 APSB_sw134_dasBodyControlsVEH "APSB ECU: sw134 das body controls VEH";
CM_ SG_ 1482 APSB_sw134_dasControl "APSB ECU: sw134 das control";
CM_ SG_ 1482 APSB_sw134_dasControlPty "APSB ECU: sw134 das control pty";
CM_ SG_ 1482 APSB_sw134_dasIntSafetyFrontPty "APSB ECU: sw134 das int safety front pty";
CM_ SG_ 1482 APSB_sw134_dasLanes "APSB ECU: sw134 das lanes";
CM_ SG_ 1482 APSB_sw134_dasObject "APSB ECU: sw134 das object";
CM_ SG_ 1482 APSB_sw134_dasPscControl "APSB ECU: sw134 das psc control";
CM_ SG_ 1482 APSB_sw134_dasStatus "APSB ECU: sw134 das status";
CM_ SG_ 1482 APSB_sw134_dasStatus2 "APSB ECU: sw134 das status2";
CM_ SG_ 1482 APSB_sw134_dasSteeringControl "APSB ECU: sw134 das steering control";
CM_ SG_ 1482 APSB_sw134_dasVisualDebug "APSB ECU: sw134 das visual debug";
CM_ SG_ 1482 APSB_sw134_dasSteeringControlPty "APSB ECU: sw134 das steering control pty";
CM_ SG_ 1482 APSB_sw134_dasChNm "APSB ECU: sw134 das ch nm";
CM_ SG_ 1482 APSB_sw134_appSummon "APSB ECU: sw134 app summon";
CM_ SG_ 1482 APSB_sw134_appEnvironment "APSB ECU: sw134 app environment";
CM_ SG_ 1482 APSB_sw134_dasStatusPty "APSB ECU: sw134 das status pty";
CM_ SG_ 1482 APSB_sw134_dasStatus2Pty "APSB ECU: sw134 das status2 pty";
CM_ SG_ 1482 APSB_sw134_dasMatrixHighBeamRqVE "APSB ECU: sw134 das matrix high beam rq VEH";
CM_ SG_ 1482 APSB_sw134_dasMatrixBendAngleRqP "APSB ECU: sw134 das matrix bend angle rq pty";
CM_ SG_ 1482 APSB_sw134_dasBodyControls2VEH "APSB ECU: sw134 das body controls2 VEH";
CM_ SG_ 1482 APSB_sw134_dasRedundantBrakingCo "APSB ECU: sw134 das redundant braking control";
CM_ SG_ 1482 APSB_sw134_dasRedundantBrak_0001 "APSB ECU: sw134 das redundant braking control pty";
CM_ SG_ 1482 APSB_sw134_timeSinceLastMsg "APSB ECU: sw134 time since last msg";
CM_ SG_ 1482 APSB_sw135_appCriticalReason "APSB ECU: sw135 app critical reason";
CM_ SG_ 1482 APSB_sw135_appTimesyncStatus "APSB ECU: sw135 app timesync status";
CM_ SG_ 1482 APSB_sw136_gpsCommIrrecoverable "APSB ECU: sw136 gps comm irrecoverable";
CM_ SG_ 1482 APSB_sw136_fusionIrrecoverable "APSB ECU: sw136 fusion irrecoverable";
CM_ SG_ 1482 APSB_sw136_antennaUnplugged "APSB ECU: sw136 antenna unplugged";
CM_ SG_ 1482 APSB_sw136_badgpsfix "APSB ECU: sw136 badgpsfix";
CM_ SG_ 1482 APSB_sw137_gpsCommMissing "APSB ECU: sw137 gps comm missing";
CM_ SG_ 1482 APSB_sw137_gpsJunkData "APSB ECU: sw137 gps junk data";
CM_ SG_ 1482 APSB_sw137_gpsNMEAmissing "APSB ECU: sw137 gps NME amissing";
CM_ SG_ 1482 APSB_sw137_gpsUBXmissing "APSB ECU: sw137 gps UB xmissing";
CM_ SG_ 1482 APSB_sw137_fusionModeDisabled "APSB ECU: sw137 fusion mode disabled";
CM_ SG_ 1482 APSB_sw137_gpsCfgFail "APSB ECU: sw137 gps cfg fail";
CM_ SG_ 1482 APSB_sw137_esfStatusMsgMIA "APSB ECU: sw137 esf status msg MIA";
CM_ SG_ 1482 APSB_sw137_wheelTickCfgMissmatch "APSB ECU: sw137 wheel tick cfg missmatch";
CM_ SG_ 1482 APSB_sw137_exitTransportMode "APSB ECU: sw137 exit transport mode";
CM_ SG_ 1482 APSB_sw137_satRejectionTimeout "APSB ECU: sw137 sat rejection timeout";
CM_ SG_ 1482 APSB_sw137_gpsPPSMissing "APSB ECU: sw137 gps PPS missing";
CM_ SG_ 1482 APSB_sw138_cfgBufNull "APSB ECU: sw138 cfg buf null";
CM_ SG_ 1482 APSB_sw138_invalidID "APSB ECU: sw138 invalid ID";
CM_ SG_ 1482 APSB_sw138_gpsBufferOverflow "APSB ECU: sw138 gps buffer overflow";
CM_ SG_ 1482 APSB_sw138_navx5CfgFailed "APSB ECU: sw138 navx5 cfg failed";
CM_ SG_ 1482 APSB_sw138_mcuNMEAmsgUDPinvalid "APSB ECU: sw138 mcu NME amsg UD pinvalid";
CM_ SG_ 1482 APSB_sw138_mcuDbgMsgInvalid "APSB ECU: sw138 mcu dbg msg invalid";
CM_ SG_ 1482 APSB_sw138_mcuDbgMsgTooBig "APSB ECU: sw138 mcu dbg msg too big";
CM_ SG_ 1482 APSB_sw138_mcuFwdNMEAfail "APSB ECU: sw138 mcu fwd NME afail";
CM_ SG_ 1482 APSB_sw138_NMEAinvalidChecksum "APSB ECU: sw138 NME ainvalid checksum";
CM_ SG_ 1482 APSB_sw138_unexpectedNMEAmsg "APSB ECU: sw138 unexpected NME amsg";
CM_ SG_ 1482 APSB_sw138_UARTbusFull "APSB ECU: sw138 UAR tbus full";
CM_ SG_ 1482 APSB_sw138_UARTframeError "APSB ECU: sw138 UAR tframe error";
CM_ SG_ 1482 APSB_sw138_UBXrxFrameTooBig "APSB ECU: sw138 UB xrx frame too big";
CM_ SG_ 1482 APSB_sw138_emptyValidNMEA "APSB ECU: sw138 empty valid NMEA";
CM_ SG_ 1482 APSB_sw138_invalidAsciiNMEA "APSB ECU: sw138 invalid ascii NMEA";
CM_ SG_ 1482 APSB_sw138_wheeltickUARTfault "APSB ECU: sw138 wheeltick UAR tfault";
CM_ SG_ 1482 APSB_sw138_baudrateMismatch "APSB ECU: sw138 baudrate mismatch";
CM_ SG_ 1482 APSB_sw138_wheelTickInvalidSrc "APSB ECU: sw138 wheel tick invalid src";
CM_ SG_ 1482 APSB_sw138_UARTparityError "APSB ECU: sw138 UAR tparity error";
CM_ SG_ 1482 APSB_sw138_UARTrxFifoOverflow "APSB ECU: sw138 UAR trx fifo overflow";
CM_ SG_ 1482 APSB_sw138_UARTrxFifoUnderflow "APSB ECU: sw138 UAR trx fifo underflow";
CM_ SG_ 1482 APSB_sw138_UARTtxFifoOverflow "APSB ECU: sw138 UAR ttx fifo overflow";
CM_ SG_ 1482 APSB_sw138_esfWtMsgTimeout "APSB ECU: sw138 esf wt msg timeout";
CM_ SG_ 1482 APSB_sw138_PFLASHReadError "APSB ECU: sw138 PFLASH read error";
CM_ SG_ 1482 APSB_sw138_PFLASHWriteError "APSB ECU: sw138 PFLASH write error";
CM_ SG_ 1482 APSB_sw138_gpsCfgNack "APSB ECU: sw138 gps cfg nack";
CM_ SG_ 1482 APSB_sw138_gpsCfgIdFail "APSB ECU: sw138 gps cfg id fail";
CM_ SG_ 1482 APSB_sw138_gpsSetCfgNoAck "APSB ECU: sw138 gps set cfg no ack";
CM_ SG_ 1482 APSB_sw138_gpsReadCfgNoResponse "APSB ECU: sw138 gps read cfg no response";
CM_ SG_ 1482 APSB_sw138_ubxErrorReported "APSB ECU: sw138 ubx error reported";
CM_ SG_ 1482 APSB_sw140_lvPowerState "APSB ECU: sw140 lv power state";
CM_ SG_ 1482 APSB_sw140_vehicleStatus "APSB ECU: sw140 vehicle status";
CM_ SG_ 1482 APSB_sw140_status "APSB ECU: sw140 status";
CM_ SG_ 1482 APSB_sw140_lighting "APSB ECU: sw140 lighting";
CM_ SG_ 1482 APSB_sw140_sensors "APSB ECU: sw140 sensors";
CM_ SG_ 1482 APSB_sw140_coolant "APSB ECU: sw140 coolant";
CM_ SG_ 1482 APSB_sw140_okToUseHighPower "APSB ECU: sw140 ok to use high power";
CM_ SG_ 1482 APSB_sw141_inertial1 "APSB ECU: sw141 inertial1";
CM_ SG_ 1482 APSB_sw141_inertial2 "APSB ECU: sw141 inertial2";
CM_ SG_ 1482 APSB_sw142_speed "APSB ECU: sw142 speed";
CM_ SG_ 1482 APSB_sw142_locStatus "APSB ECU: sw142 loc status";
CM_ SG_ 1482 APSB_sw142_locStatus2 "APSB ECU: sw142 loc status2";
CM_ SG_ 1482 APSB_sw142_systemStatus "APSB ECU: sw142 system status";
CM_ SG_ 1482 APSB_sw142_chassisControl "APSB ECU: sw142 chassis control";
CM_ SG_ 1482 APSB_sw142_epbStatus "APSB ECU: sw142 epb status";
CM_ SG_ 1482 APSB_sw142_brakeSystem "APSB ECU: sw142 brake system";
CM_ SG_ 1482 APSB_sw143_status "APSB ECU: sw143 status";
CM_ SG_ 1482 APSB_sw143_wheelRotation "APSB ECU: sw143 wheel rotation";
CM_ SG_ 1482 APSB_sw143_wheelSpeeds "APSB ECU: sw143 wheel speeds";
CM_ SG_ 1482 APSB_sw143_redundantBrakingStatu "APSB ECU: sw143 redundant braking status";
CM_ SG_ 1482 APSB_sw144_restraintStatus "APSB ECU: sw144 restraint status";
CM_ SG_ 1482 APSB_sw145_restraintStatus "APSB ECU: sw145 restraint status";
CM_ SG_ 1482 APSB_sw146_sysStatus "APSB ECU: sw146 sys status";
CM_ SG_ 1482 APSB_sw146_status "APSB ECU: sw146 status";
CM_ SG_ 1482 APSB_sw147_doorStatus "APSB ECU: sw147 door status";
CM_ SG_ 1482 APSB_sw147_switchStatus "APSB ECU: sw147 switch status";
CM_ SG_ 1482 APSB_sw148_doorStatus "APSB ECU: sw148 door status";
CM_ SG_ 1482 APSB_sw148_hvacStatus "APSB ECU: sw148 hvac status";
CM_ SG_ 1482 APSB_sw149_status "APSB ECU: sw149 status";
CM_ SG_ 1482 APSB_sw150_steeringAngleSensor "APSB ECU: sw150 steering angle sensor";
CM_ SG_ 1482 APSB_sw150_rightStalk "APSB ECU: sw150 right stalk";
CM_ SG_ 1482 APSB_sw150_leftStalk "APSB ECU: sw150 left stalk";
CM_ SG_ 1482 APSB_sw153_eacInhibitReason "APSB ECU: sw153 eac inhibit reason";
CM_ SG_ 1482 APSB_sw153_eacInternalState "APSB ECU: sw153 eac internal state";
CM_ SG_ 1482 APSB_sw155_InUnicastError "APSB ECU: sw155 in unicast error";
CM_ SG_ 1482 APSB_sw155_UDPRecvError "APSB ECU: sw155 UDP recv error";
CM_ SG_ 1482 APSB_sw155_UDPMiscError "APSB ECU: sw155 UDP misc error";
CM_ SG_ 1482 APSB_sw155_UDPRTEError "APSB ECU: sw155 UDPRTE error";
CM_ SG_ 1482 APSB_sw155_UDPCheckError "APSB ECU: sw155 UDP check error";
CM_ SG_ 1482 APSB_sw155_UDPDropError "APSB ECU: sw155 UDP drop error";
CM_ SG_ 1482 APSB_sw155_UDPMemError "APSB ECU: sw155 UDP mem error";
CM_ SG_ 1482 APSB_sw155_UDPProtoError "APSB ECU: sw155 UDP proto error";
CM_ SG_ 1482 APSB_sw155_IPRecvError "APSB ECU: sw155 IP recv error";
CM_ SG_ 1482 APSB_sw155_IPMiscError "APSB ECU: sw155 IP misc error";
CM_ SG_ 1482 APSB_sw155_IPRTEError "APSB ECU: sw155 IPRTE error";
CM_ SG_ 1482 APSB_sw155_IPCheckError "APSB ECU: sw155 IP check error";
CM_ SG_ 1482 APSB_sw155_IPMemError "APSB ECU: sw155 IP mem error";
CM_ SG_ 1482 APSB_sw155_IPDropError "APSB ECU: sw155 IP drop error";
CM_ SG_ 1482 APSB_sw155_IPProtoError "APSB ECU: sw155 IP proto error";
CM_ SG_ 1482 APSB_sw158_apbInfo "APSB ECU: sw158 apb info";
CM_ SG_ 1482 APSB_sw158_apbStatus "APSB ECU: sw158 apb status";
CM_ SG_ 1482 APSB_sw158_dasAutonomyControlPar "APSB ECU: sw158 das autonomy control party";
CM_ SG_ 1482 APSB_sw158_dasAutonomyControlVeh "APSB ECU: sw158 das autonomy control veh";
CM_ SG_ 1482 APSB_sw158_dasBodyControlsVEH "APSB ECU: sw158 das body controls VEH";
CM_ SG_ 1482 APSB_sw158_dasControl "APSB ECU: sw158 das control";
CM_ SG_ 1482 APSB_sw158_dasControlPty "APSB ECU: sw158 das control pty";
CM_ SG_ 1482 APSB_sw158_dasIntSafetyFrontPty "APSB ECU: sw158 das int safety front pty";
CM_ SG_ 1482 APSB_sw158_dasLanes "APSB ECU: sw158 das lanes";
CM_ SG_ 1482 APSB_sw158_dasObject "APSB ECU: sw158 das object";
CM_ SG_ 1482 APSB_sw158_dasPscControl "APSB ECU: sw158 das psc control";
CM_ SG_ 1482 APSB_sw158_dasStatus "APSB ECU: sw158 das status";
CM_ SG_ 1482 APSB_sw158_dasStatus2 "APSB ECU: sw158 das status2";
CM_ SG_ 1482 APSB_sw158_dasSteeringControl "APSB ECU: sw158 das steering control";
CM_ SG_ 1482 APSB_sw158_dasVisualDebug "APSB ECU: sw158 das visual debug";
CM_ SG_ 1482 APSB_sw158_dasSteeringControlPty "APSB ECU: sw158 das steering control pty";
CM_ SG_ 1482 APSB_sw158_dasChNm "APSB ECU: sw158 das ch nm";
CM_ SG_ 1482 APSB_sw158_dasStatusPty "APSB ECU: sw158 das status pty";
CM_ SG_ 1482 APSB_sw158_dasStatus2Pty "APSB ECU: sw158 das status2 pty";
CM_ SG_ 1482 APSB_sw158_dasMatrixHighBeamRqVE "APSB ECU: sw158 das matrix high beam rq VEH";
CM_ SG_ 1482 APSB_sw158_dasMatrixBendAngleRqP "APSB ECU: sw158 das matrix bend angle rq pty";
CM_ SG_ 1482 APSB_sw158_dasBodyControls2VEH "APSB ECU: sw158 das body controls2 VEH";
CM_ SG_ 1482 APSB_sw158_dasRedundantBrakingCo "APSB ECU: sw158 das redundant braking control";
CM_ SG_ 1482 APSB_sw158_dasRedundantBrak_0001 "APSB ECU: sw158 das redundant braking control pty";
CM_ SG_ 1482 APSB_sw158_timeSinceLastMsg "APSB ECU: sw158 time since last msg";
CM_ SG_ 1482 APSB_sw159_apbCriticalReason "APSB ECU: sw159 apb critical reason";
CM_ SG_ 1482 APSB_sw159_apbTimesyncStatus "APSB ECU: sw159 apb timesync status";
CM_ SG_ 1482 APSB_sw160_mismatchType "APSB ECU: sw160 mismatch type";
CM_ SG_ 1482 APSB_sw160_actualHash "APSB ECU: sw160 actual hash";
CM_ SG_ 1482 APSB_sw160_expectedHash "APSB ECU: sw160 expected hash";
CM_ SG_ 1482 APSB_sw161_antennaDisconnected "APSB ECU: sw161 antenna disconnected";
CM_ SG_ 1482 APSB_sw172_prolongedUiMia "APSB ECU: sw172 prolonged ui mia";
CM_ SG_ 1482 APSB_sw172_uiMiaAtBootup "APSB ECU: sw172 ui mia at bootup";
CM_ SG_ 1482 APSB_sw188_otherTurbo "APSB ECU: sw188 other turbo";
CM_ SG_ 1482 APSB_sw188_arbUartMiaState "APSB ECU: sw188 arb uart mia state";
CM_ SG_ 1482 APSB_sw188_powerUartMiaState "APSB ECU: sw188 power uart mia state";
CM_ SG_ 1482 APSB_sw188_faultsUartMiaState "APSB ECU: sw188 faults uart mia state";
CM_ SG_ 1482 APSB_sw188_sleepUartMiaState "APSB ECU: sw188 sleep uart mia state";
CM_ SG_ 1482 APSB_sw188_resetUartMiaState "APSB ECU: sw188 reset uart mia state";
CM_ SG_ 1482 APSB_sw188_statMonUartMiaState "APSB ECU: sw188 stat mon uart mia state";
CM_ SG_ 1482 APSB_sw188_wdogStateUartMiaState "APSB ECU: sw188 wdog state uart mia state";
CM_ SG_ 1482 APSB_sw188_critReasUartMiaState "APSB ECU: sw188 crit reas uart mia state";
CM_ SG_ 1482 APSB_sw189_AP_vehicleState10Hz "APSB ECU: sw189 AP vehicle state10 hz";
CM_ SG_ 1482 APSB_sw189_AP_vehicleState1Hz "APSB ECU: sw189 AP vehicle state1 hz";
CM_ SG_ 1482 APSB_sw190_IBST_status "APSB ECU: sw190 IBST status";
CM_ SG_ 1482 APSB_sw192_CANbus "APSB ECU: sw192 CA nbus";
CM_ SG_ 1482 APSB_sw192_SWTxQueueFull "APSB ECU: sw192 SW tx queue full";
CM_ SG_ 1482 APSB_sw192_Busoff "APSB ECU: sw192 busoff";
CM_ SG_ 1482 APSB_sw192_UncorrectedBitError "APSB ECU: sw192 uncorrected bit error";
CM_ SG_ 1482 APSB_sw192_CorrectedBitError "APSB ECU: sw192 corrected bit error";
CM_ SG_ 1482 APSB_sw192_ErrorPassive "APSB ECU: sw192 error passive";
CM_ SG_ 1482 APSB_sw192_RamAccessFailed "APSB ECU: sw192 ram access failed";
CM_ SG_ 1482 APSB_sw192_RxMsgLost "APSB ECU: sw192 rx msg lost";
CM_ SG_ 1482 APSB_sw192_msgIo "APSB ECU: sw192 msg io";
CM_ SG_ 1482 APSB_sw192_queueFailure "APSB ECU: sw192 queue failure";
CM_ SG_ 1482 APSB_sw192_msgId "APSB ECU: sw192 msg id";
CM_ SG_ 1482 APSB_sw199_abortCodeDas "APSB ECU: sw199 abort code das";
CM_ SG_ 1482 APSB_sw199_abortCodePARK "APSB ECU: sw199 abort code PARK; raw 31 = signal not available (SNA)";
CM_ SG_ 1482 APSB_sw199_currentSTW "APSB ECU: sw199 current STW";
CM_ SG_ 1482 APSB_sw199_currentSpeed "APSB ECU: sw199 current speed";
CM_ SG_ 1482 APSB_sw199_internalState "APSB ECU: sw199 internal state";
CM_ SG_ 1482 APSB_sw199_maxSpeed "APSB ECU: sw199 max speed";
CM_ SG_ 1482 APSB_sw199_numShifts "APSB ECU: sw199 num shifts";
CM_ SG_ 1482 APSB_sw203_controlType "APSB ECU: sw203 control type; raw 15 = signal not available (SNA)";
CM_ SG_ 1482 APSB_sw203_curbType "APSB ECU: sw203 curb type";
CM_ SG_ 1482 APSB_sw203_roadClass "APSB ECU: sw203 road class";
CM_ SG_ 1482 APSB_sw203_slotSizeX "APSB ECU: sw203 slot size x";
CM_ SG_ 1482 APSB_sw203_slotSizeY "APSB ECU: sw203 slot size y";
CM_ SG_ 1482 APSB_sw203_startDistance "APSB ECU: sw203 start distance";
CM_ SG_ 1482 APSB_sw203_vehicleSkew "APSB ECU: sw203 vehicle skew";
CM_ SG_ 1482 APSB_sw204_frLeft "APSB ECU: sw204 fr left";
CM_ SG_ 1482 APSB_sw204_frLeftMiddle "APSB ECU: sw204 fr left middle";
CM_ SG_ 1482 APSB_sw204_frMiddle "APSB ECU: sw204 fr middle";
CM_ SG_ 1482 APSB_sw204_frRight "APSB ECU: sw204 fr right";
CM_ SG_ 1482 APSB_sw204_frRightMiddle "APSB ECU: sw204 fr right middle";
CM_ SG_ 1482 APSB_sw204_maxSpeed "APSB ECU: sw204 max speed";
CM_ SG_ 1482 APSB_sw205_oocDistance "APSB ECU: sw205 ooc distance";
CM_ SG_ 1482 APSB_sw205_rrLeft "APSB ECU: sw205 rr left";
CM_ SG_ 1482 APSB_sw205_rrLeftMiddle "APSB ECU: sw205 rr left middle";
CM_ SG_ 1482 APSB_sw205_rrMiddle "APSB ECU: sw205 rr middle";
CM_ SG_ 1482 APSB_sw205_rrRight "APSB ECU: sw205 rr right";
CM_ SG_ 1482 APSB_sw205_rrRightMiddle "APSB ECU: sw205 rr right middle";
CM_ SG_ 1482 APSB_sw235_resetOrigin "APSB ECU: sw235 reset origin";
CM_ SG_ 1482 APSB_sw235_generalUnrecoverable "APSB ECU: sw235 general unrecoverable";
CM_ SG_ 1482 APSB_sw235_pgoodUnrecoverable "APSB ECU: sw235 pgood unrecoverable";
CM_ SG_ 1482 APSB_sw235_faultUnrecoverable "APSB ECU: sw235 fault unrecoverable";
CM_ SG_ 1482 APSB_sw235_12VFuseUnrecoverable "APSB ECU: sw235 12 v fuse unrecoverable";
CM_ SG_ 1482 APSB_sw235_pgoodLevelUnrcvrble "APSB ECU: sw235 pgood level unrcvrble";
CM_ SG_ 1482 APSB_sw235_faultLevelUnrcvrble "APSB ECU: sw235 fault level unrcvrble";
CM_ SG_ 1482 APSB_sw235_12VFuseLvlUnrcvrble "APSB ECU: sw235 12 v fuse lvl unrcvrble";
CM_ SG_ 1482 APSB_sw235_localSoftwareFault "APSB ECU: sw235 local software fault";
CM_ SG_ 1482 APSB_sw235_unrecoverableFailRese "APSB ECU: sw235 unrecoverable fail reset";
CM_ SG_ 1482 APSB_sw235_generalGic "APSB ECU: sw235 general gic";
CM_ SG_ 1482 APSB_sw235_a72WdtTimeout "APSB ECU: sw235 a72 wdt timeout";
CM_ SG_ 1482 APSB_sw235_generalScs "APSB ECU: sw235 general scs";
CM_ SG_ 1482 APSB_sw235_generalUnexpected "APSB ECU: sw235 general unexpected";
CM_ SG_ 1482 APSB_sw235_canUncorrectedBitErro "APSB ECU: sw235 can uncorrected bit error";
CM_ SG_ 1482 APSB_sw235_canExitBusoffFailed "APSB ECU: sw235 can exit busoff failed";
CM_ SG_ 1482 APSB_sw235_txEnFdbckNotExpected "APSB ECU: sw235 tx en fdbck not expected";
CM_ SG_ 1482 APSB_sw235_nocSmsFailed "APSB ECU: sw235 noc sms failed";
CM_ SG_ 1482 APSB_sw235_nocCamFailed "APSB ECU: sw235 noc cam failed";
CM_ SG_ 1482 APSB_sw235_nocCoreFailed "APSB ECU: sw235 noc core failed";
CM_ SG_ 1482 APSB_sw235_nocScsFailed "APSB ECU: sw235 noc scs failed";
CM_ SG_ 1482 APSB_sw235_model3UiReset "APSB ECU: sw235 model3 ui reset";
CM_ SG_ 1482 APSB_sw235_modelsUiReset "APSB ECU: sw235 models ui reset";
CM_ SG_ 1482 APSB_sw235_pmicApOnPrpUnrcvrble "APSB ECU: sw235 pmic ap on prp unrcvrble";
CM_ SG_ 1482 APSB_sw235_apOnReadyTimeout "APSB ECU: sw235 ap on ready timeout";
CM_ SG_ 1482 APSB_sw235_pmicApOnWaitUnrcvrble "APSB ECU: sw235 pmic ap on wait unrcvrble";
CM_ SG_ 1482 APSB_sw235_apBootingTimeout "APSB ECU: sw235 ap booting timeout";
CM_ SG_ 1482 APSB_sw235_pmicApOffWaitUnrcvrbl "APSB ECU: sw235 pmic ap off wait unrcvrble";
CM_ SG_ 1482 APSB_sw235_resetBeingSent "APSB ECU: sw235 reset being sent";
CM_ SG_ 1482 APSB_sw235_udsResetBeingSent "APSB ECU: sw235 uds reset being sent";
CM_ SG_ 1482 APSB_sw235_smsWdtTimeout "APSB ECU: sw235 sms wdt timeout";
CM_ SG_ 1482 APSB_sw235_smsCanApHealthTimeout "APSB ECU: sw235 sms can ap health timeout";
CM_ SG_ 1482 APSB_sw235_smsTaskWdtTimeout "APSB ECU: sw235 sms task wdt timeout";
CM_ SG_ 1482 APSB_sw237_faultSource "APSB ECU: sw237 fault source";
CM_ SG_ 1482 APSB_sw237_peerSoCFaulted "APSB ECU: sw237 peer so c faulted";
CM_ SG_ 1482 APSB_sw241_unknownVendorOnResume "APSB ECU: sw241 unknown vendor on resume";
CM_ SG_ 1482 APSB_sw241_unknownVendorOnNonRes "APSB ECU: sw241 unknown vendor on non resume";
CM_ SG_ 1482 APSB_sw241_phyReinitFailedOnResu "APSB ECU: sw241 phy reinit failed on resume";
CM_ SG_ 1482 APSB_sw241_phyReinitFailedOnNonR "APSB ECU: sw241 phy reinit failed on non resume";
CM_ SG_ 1482 APSB_sw241_illTestFailed "APSB ECU: sw241 ill test failed";
CM_ SG_ 1482 APSB_sw241_memTestFailed "APSB ECU: sw241 mem test failed";
CM_ SG_ 1482 APSB_sw241_dfiInitCompleteTimeou "APSB ECU: sw241 dfi init complete timeout";
CM_ SG_ 1482 APSB_sw241_phy0TimeoutWaitingFor "APSB ECU: sw241 phy0 timeout waiting for interrupts";
CM_ SG_ 1482 APSB_sw241_phy0Ch0ReadGateOffset "APSB ECU: sw241 phy0 ch0 read gate offset bug";
CM_ SG_ 1482 APSB_sw241_phy0Ch1ReadGateOffset "APSB ECU: sw241 phy0 ch1 read gate offset bug";
CM_ SG_ 1482 APSB_sw241_phy0RdlvlReinitTraini "APSB ECU: sw241 phy0 rdlvl reinit training timeout";
CM_ SG_ 1482 APSB_sw241_phy0RdlvlReinitFailed "APSB ECU: sw241 phy0 rdlvl reinit failed";
CM_ SG_ 1482 APSB_sw241_phy0WdqlvlReinitTrain "APSB ECU: sw241 phy0 wdqlvl reinit training timeout";
CM_ SG_ 1482 APSB_sw241_phy0WdqlvlPhaseMargin "APSB ECU: sw241 phy0 wdqlvl phase margin out of range";
CM_ SG_ 1482 APSB_sw241_phy0WdqlvlReinitFaile "APSB ECU: sw241 phy0 wdqlvl reinit failed";
CM_ SG_ 1482 APSB_sw241_phy1TimeoutWaitingFor "APSB ECU: sw241 phy1 timeout waiting for interrupts";
CM_ SG_ 1482 APSB_sw241_phy1Ch0ReadGateOffset "APSB ECU: sw241 phy1 ch0 read gate offset bug";
CM_ SG_ 1482 APSB_sw241_phy1Ch1ReadGateOffset "APSB ECU: sw241 phy1 ch1 read gate offset bug";
CM_ SG_ 1482 APSB_sw241_phy1RdlvlReinitTraini "APSB ECU: sw241 phy1 rdlvl reinit training timeout";
CM_ SG_ 1482 APSB_sw241_phy1RdlvlReinitFailed "APSB ECU: sw241 phy1 rdlvl reinit failed";
CM_ SG_ 1482 APSB_sw241_phy1WdqlvlReinitTrain "APSB ECU: sw241 phy1 wdqlvl reinit training timeout";
CM_ SG_ 1482 APSB_sw241_phy1WdqlvlPhaseMargin "APSB ECU: sw241 phy1 wdqlvl phase margin out of range";
CM_ SG_ 1482 APSB_sw241_phy1WdqlvlReinitFaile "APSB ECU: sw241 phy1 wdqlvl reinit failed";
CM_ SG_ 1482 APSB_sw241_phy2TimeoutWaitingFor "APSB ECU: sw241 phy2 timeout waiting for interrupts";
CM_ SG_ 1482 APSB_sw241_phy2Ch0ReadGateOffset "APSB ECU: sw241 phy2 ch0 read gate offset bug";
CM_ SG_ 1482 APSB_sw241_phy2Ch1ReadGateOffset "APSB ECU: sw241 phy2 ch1 read gate offset bug";
CM_ SG_ 1482 APSB_sw241_phy2RdlvlReinitTraini "APSB ECU: sw241 phy2 rdlvl reinit training timeout";
CM_ SG_ 1482 APSB_sw241_phy2RdlvlReinitFailed "APSB ECU: sw241 phy2 rdlvl reinit failed";
CM_ SG_ 1482 APSB_sw241_phy2WdqlvlReinitTrain "APSB ECU: sw241 phy2 wdqlvl reinit training timeout";
CM_ SG_ 1482 APSB_sw241_phy2WdqlvlPhaseMargin "APSB ECU: sw241 phy2 wdqlvl phase margin out of range";
CM_ SG_ 1482 APSB_sw241_phy2WdqlvlReinitFaile "APSB ECU: sw241 phy2 wdqlvl reinit failed";
CM_ SG_ 1482 APSB_sw241_phy3TimeoutWaitingFor "APSB ECU: sw241 phy3 timeout waiting for interrupts";
CM_ SG_ 1482 APSB_sw241_phy3Ch0ReadGateOffset "APSB ECU: sw241 phy3 ch0 read gate offset bug";
CM_ SG_ 1482 APSB_sw241_phy3Ch1ReadGateOffset "APSB ECU: sw241 phy3 ch1 read gate offset bug";
CM_ SG_ 1482 APSB_sw241_phy3RdlvlReinitTraini "APSB ECU: sw241 phy3 rdlvl reinit training timeout";
CM_ SG_ 1482 APSB_sw241_phy3RdlvlReinitFailed "APSB ECU: sw241 phy3 rdlvl reinit failed";
CM_ SG_ 1482 APSB_sw241_phy3WdqlvlReinitTrain "APSB ECU: sw241 phy3 wdqlvl reinit training timeout";
CM_ SG_ 1482 APSB_sw241_phy3WdqlvlPhaseMargin "APSB ECU: sw241 phy3 wdqlvl phase margin out of range";
CM_ SG_ 1482 APSB_sw241_phy3WdqlvlReinitFaile "APSB ECU: sw241 phy3 wdqlvl reinit failed";
CM_ SG_ 1482 APSB_sw242_instance "APSB ECU: sw242 instance";
CM_ SG_ 1482 APSB_sw242_clusterSRAMMBISTFaile "APSB ECU: sw242 cluster SRAMMBIST failed";
CM_ SG_ 1482 APSB_sw242_SRAMBankMBISTFailed "APSB ECU: sw242 SRAM bank MBIST failed";
CM_ SG_ 1482 APSB_sw243_instance "APSB ECU: sw243 instance";
CM_ SG_ 1482 APSB_sw243_errorStatus "APSB ECU: sw243 error status";
CM_ SG_ 1482 APSB_sw243_extendedErrorStatus "APSB ECU: sw243 extended error status";
CM_ SG_ 1482 APSB_sw244_instance "APSB ECU: sw244 instance";
CM_ SG_ 1482 APSB_sw244_exceptionCode "APSB ECU: sw244 exception code";
CM_ SG_ 1482 APSB_sw245_unknownMACAddrByte0 "APSB ECU: sw245 unknown MAC addr byte0";
CM_ SG_ 1482 APSB_sw245_unknownMACAddrByte1 "APSB ECU: sw245 unknown MAC addr byte1";
CM_ SG_ 1482 APSB_sw245_unknownMACAddrByte2 "APSB ECU: sw245 unknown MAC addr byte2";
CM_ SG_ 1482 APSB_sw245_unknownMACAddrByte3 "APSB ECU: sw245 unknown MAC addr byte3";
CM_ SG_ 1482 APSB_sw245_unknownMACAddrByte4 "APSB ECU: sw245 unknown MAC addr byte4";
CM_ SG_ 1482 APSB_sw245_unknownMACAddrByte5 "APSB ECU: sw245 unknown MAC addr byte5";
CM_ SG_ 1482 APSB_sw246_ethloopSwitchPort0 "APSB ECU: sw246 ethloop switch port0";
CM_ SG_ 1482 APSB_sw246_ethloopSwitchPort1 "APSB ECU: sw246 ethloop switch port1";
CM_ SG_ 1482 APSB_sw246_ethloopSwitchPort2 "APSB ECU: sw246 ethloop switch port2";
CM_ SG_ 1482 APSB_sw246_ethloopSwitchPort3 "APSB ECU: sw246 ethloop switch port3";
CM_ SG_ 1482 APSB_sw246_ethloopSwitchPort4 "APSB ECU: sw246 ethloop switch port4";
CM_ SG_ 1482 APSB_sw246_ethloopSwitchPort5 "APSB ECU: sw246 ethloop switch port5";
CM_ SG_ 1482 APSB_sw246_ethloopSwitchPort6 "APSB ECU: sw246 ethloop switch port6";
CM_ SG_ 1482 APSB_sw246_ethloopSwitchPort7 "APSB ECU: sw246 ethloop switch port7";
CM_ SG_ 1482 APSB_sw247_crcError "APSB ECU: sw247 crc error";
CM_ SG_ 1482 APSB_sw247_dribbleError "APSB ECU: sw247 dribble error";
CM_ SG_ 1482 APSB_sw247_receiveError "APSB ECU: sw247 receive error";
CM_ SG_ 1482 APSB_sw247_wdogTimeout "APSB ECU: sw247 wdog timeout";
CM_ SG_ 1482 APSB_sw247_overflowError "APSB ECU: sw247 overflow error";
CM_ SG_ 1482 APSB_sw247_giantPacket "APSB ECU: sw247 giant packet";
CM_ SG_ 1482 APSB_sw247_destAddrFilterFail "APSB ECU: sw247 dest addr filter fail";
CM_ SG_ 1482 APSB_sw247_saAddressFilterFail "APSB ECU: sw247 sa address filter fail";
CM_ SG_ 1482 APSB_sw248_ethloopSwitchPort2Sqi "APSB ECU: sw248 ethloop switch port2 sqi";
CM_ SG_ 1482 APSB_sw248_ethloopSwitchPort3Sqi "APSB ECU: sw248 ethloop switch port3 sqi";
CM_ SG_ 1482 APSB_sw249_ufsInitFailureReason "APSB ECU: sw249 ufs init failure reason";
CM_ SG_ 1482 APSB_sw252_ethSwitchPort2 "APSB ECU: sw252 eth switch port2";
CM_ SG_ 1482 APSB_sw253_apWaitForShutdownTime "APSB ECU: sw253 ap wait for shutdown timeout";
CM_ SG_ 1482 APSB_sw253_apOffPrepareTimeout "APSB ECU: sw253 ap off prepare timeout";
CM_ SG_ 1482 APSB_sw253_apSuspendedTimeout "APSB ECU: sw253 ap suspended timeout";
CM_ SG_ 1482 APSB_sw253_socOffReadyTimeout "APSB ECU: sw253 soc off ready timeout";
CM_ SG_ 1482 APSB_sw253_apInLinuxTimeout "APSB ECU: sw253 ap in linux timeout";
CM_ SG_ 1482 APSB_sw253_apInCorebootTimeout "APSB ECU: sw253 ap in coreboot timeout";
CM_ SG_ 1482 APSB_sw253_apBootingTimeout "APSB ECU: sw253 ap booting timeout";
CM_ SG_ 1482 APSB_sw253_apOnTimeout "APSB ECU: sw253 ap on timeout";
CM_ SG_ 1482 APSB_sw254_waitForBusSilenceTime "APSB ECU: sw254 wait for bus silence timeout";
CM_ SG_ 1482 APSB_sw254_sleepReadyTimeout "APSB ECU: sw254 sleep ready timeout";
CM_ SG_ 1482 APSB_sw254_sleepingTimeout "APSB ECU: sw254 sleeping timeout";
CM_ SG_ 1482 APSB_sw255_unknownBootError "APSB ECU: sw255 unknown boot error";
CM_ SG_ 1482 APSB_sw255_adcWrapperInitBootErr "APSB ECU: sw255 adc wrapper init boot error";
CM_ SG_ 1482 APSB_sw255_boardRevisionInitBoot "APSB ECU: sw255 board revision init boot error";
CM_ SG_ 1482 APSB_sw255_i2cInitBootError "APSB ECU: sw255 i2c init boot error";
CM_ SG_ 1482 APSB_sw255_provisionInitBootErro "APSB ECU: sw255 provision init boot error";
CM_ SG_ 1482 APSB_sw255_rtcInitBootError "APSB ECU: sw255 rtc init boot error";
CM_ SG_ 1482 APSB_sw255_vrmInitConfigBootErro "APSB ECU: sw255 vrm init config boot error";
CM_ SG_ 1482 APSB_sw255_powerAonIoBootError "APSB ECU: sw255 power aon io boot error";
CM_ SG_ 1482 APSB_sw255_bl1TocInitBootError "APSB ECU: sw255 bl1 toc init boot error";
CM_ SG_ 1482 APSB_sw255_tmuInitBootError "APSB ECU: sw255 tmu init boot error";
CM_ SG_ 1482 APSB_sw255_udpInitBootError "APSB ECU: sw255 udp init boot error";
CM_ SG_ 1482 APSB_sw255_gpsInitBootError "APSB ECU: sw255 gps init boot error";
CM_ SG_ 1482 APSB_sw255_canInitBootError "APSB ECU: sw255 can init boot error";
CM_ SG_ 1482 APSB_sw255_dfuCheckinSubsystemBo "APSB ECU: sw255 dfu checkin subsystem boot error";
CM_ SG_ 1482 APSB_sw255_sectorProtectionBootE "APSB ECU: sw255 sector protection boot error";
CM_ SG_ 1482 APSB_sw255_flashOpBootError "APSB ECU: sw255 flash op boot error";
CM_ SG_ 1482 APSB_sw255_socIdInitBootError "APSB ECU: sw255 soc id init boot error";
CM_ SG_ 1482 APSB_sw260_pgoodTripSramStatus "APSB ECU: sw260 pgood trip sram status";
CM_ SG_ 1482 APSB_sw260_pgoodPmicFaultSd0 "APSB ECU: sw260 pgood pmic fault sd0";
CM_ SG_ 1482 APSB_sw260_pgoodPmicFaultSd1 "APSB ECU: sw260 pgood pmic fault sd1";
CM_ SG_ 1482 APSB_sw260_pgoodPmicFaultSd2 "APSB ECU: sw260 pgood pmic fault sd2";
CM_ SG_ 1482 APSB_sw260_pgoodPmicFaultSd3 "APSB ECU: sw260 pgood pmic fault sd3";
CM_ SG_ 1482 APSB_sw260_pgoodPmicFaultSd4 "APSB ECU: sw260 pgood pmic fault sd4";
CM_ SG_ 1482 APSB_sw260_pgoodPmicFaultLdo0 "APSB ECU: sw260 pgood pmic fault ldo0";
CM_ SG_ 1482 APSB_sw260_pgoodPmicFaultLdo1 "APSB ECU: sw260 pgood pmic fault ldo1";
CM_ SG_ 1482 APSB_sw260_pgoodPmicFaultLdo2 "APSB ECU: sw260 pgood pmic fault ldo2";
CM_ SG_ 1482 APSB_sw260_pgoodPmicFaultLdo3 "APSB ECU: sw260 pgood pmic fault ldo3";
CM_ SG_ 1482 APSB_sw260_pgoodPmicFaultLdo4 "APSB ECU: sw260 pgood pmic fault ldo4";
CM_ SG_ 1482 APSB_sw260_pgoodPmicFaultLdo5 "APSB ECU: sw260 pgood pmic fault ldo5";
CM_ SG_ 1482 APSB_sw260_pgoodPmicFaultLdo6 "APSB ECU: sw260 pgood pmic fault ldo6";
CM_ SG_ 1482 APSB_sw260_pgoodPmicFaultLdo7 "APSB ECU: sw260 pgood pmic fault ldo7";
CM_ SG_ 1482 APSB_sw260_pgoodPmicFaultLdo8 "APSB ECU: sw260 pgood pmic fault ldo8";
CM_ SG_ 1482 APSB_sw260_pgoodUfs3V3Fail "APSB ECU: sw260 pgood ufs3 V3 fail";
CM_ SG_ 1482 APSB_sw260_pgoodTripVrmRailFail "APSB ECU: sw260 pgood trip vrm rail fail";
CM_ SG_ 1482 APSB_sw260_pgoodIntVrmRailFail "APSB ECU: sw260 pgood int vrm rail fail";
CM_ SG_ 1482 APSB_sw260_pgoodCpuVrmRailFail "APSB ECU: sw260 pgood cpu vrm rail fail";
CM_ SG_ 1482 APSB_sw260_pgoodGpuVrmRailFail "APSB ECU: sw260 pgood gpu vrm rail fail";
CM_ SG_ 1482 APSB_sw260_pgoodDdr0V75VrmRailFa "APSB ECU: sw260 pgood ddr0 V75 vrm rail fail";
CM_ SG_ 1482 APSB_sw260_pgoodDdr1V25VrmRailFa "APSB ECU: sw260 pgood ddr1 V25 vrm rail fail";
CM_ SG_ 1482 APSB_sw260_unknownSource "APSB ECU: sw260 unknown source";
CM_ SG_ 1482 APSB_sw261_vrmPublicFaultValues "APSB ECU: sw261 vrm public fault values";
CM_ SG_ 1482 APSB_sw261_vrmRail1FaultValues "APSB ECU: sw261 vrm rail1 fault values";
CM_ SG_ 1482 APSB_sw261_vrmRail2FaultValues "APSB ECU: sw261 vrm rail2 fault values";
CM_ SG_ 1482 APSB_sw261_vrmRail3FaultValues "APSB ECU: sw261 vrm rail3 fault values";
CM_ SG_ 1482 APSB_sw261_vrmType "APSB ECU: sw261 vrm type";
CM_ SG_ 1482 APSB_sw262_vrmPublicFaultValues "APSB ECU: sw262 vrm public fault values";
CM_ SG_ 1482 APSB_sw262_vrmRail1FaultValues "APSB ECU: sw262 vrm rail1 fault values";
CM_ SG_ 1482 APSB_sw262_vrmRail2FaultValues "APSB ECU: sw262 vrm rail2 fault values";
CM_ SG_ 1482 APSB_sw262_vrmRail3FaultValues "APSB ECU: sw262 vrm rail3 fault values";
CM_ SG_ 1482 APSB_sw262_vrmType "APSB ECU: sw262 vrm type";
CM_ SG_ 1482 APSB_sw263_vrmPublicFaultValues "APSB ECU: sw263 vrm public fault values";
CM_ SG_ 1482 APSB_sw263_vrmRail1FaultValues "APSB ECU: sw263 vrm rail1 fault values";
CM_ SG_ 1482 APSB_sw263_vrmRail2FaultValues "APSB ECU: sw263 vrm rail2 fault values";
CM_ SG_ 1482 APSB_sw263_vrmType "APSB ECU: sw263 vrm type";
CM_ SG_ 1482 APSB_sw279_corruptDirectorySourc "APSB ECU: sw279 corrupt directory source";
CM_ SG_ 1482 APSB_sw279_errorCode "APSB ECU: sw279 error code";
CM_ SG_ 1482 APSB_sw280_pepsStatus "APSB ECU: sw280 peps status";
CM_ SG_ 1482 APSB_sw281_rearSteerStatus "APSB ECU: sw281 rear steer status";
CM_ SG_ 1482 APSB_sw283_psfaStatus "APSB ECU: sw283 psfa status";
CM_ SG_ 1482 APSB_sw288_status "APSB ECU: sw288 status";
CM_ SG_ 1482 APSB_sw289_turboTemperature "APSB ECU: sw289 turbo temperature; raw 128 = signal not available (SNA)";
CM_ SG_ 1482 APSB_sw289_turboProbe "APSB ECU: sw289 turbo probe";
CM_ SG_ 1482 APSB_sw289_peer_turboTemperature "APSB ECU: sw289 peer turbo temperature; raw 128 = signal not available (SNA)";
CM_ SG_ 1482 APSB_sw289_peer_turboProbe "APSB ECU: sw289 peer turbo probe";
CM_ SG_ 1482 APSB_sw315_sysStatus "APSB ECU: sw315 sys status";
CM_ SG_ 1482 APSB_sw315_status "APSB ECU: sw315 status";
CM_ SG_ 1482 APSB_sw317_motionControlCommand "APSB ECU: sw317 motion control command";
CM_ SG_ 1482 APSB_sw317_vehicleControl2 "APSB ECU: sw317 vehicle control2";
CM_ BO_ 731 "APSB ECU message: eac monitor";
CM_ SG_ 731 APSB_eacAllow "Indicates whether or not the Aurix external angle control (EAC) monitor logic currently allows angle control for Autopilot functions; raw 3 = signal not available (SNA)";
CM_ SG_ 731 APSB_eacMonitorCounter "APSB ECU: eac monitor counter";
CM_ SG_ 731 APSB_eacMonitorChecksum "APSB ECU: eac monitor checksum";
CM_ BO_ 992 "APSB ECU message: power state inputs";
CM_ SG_ 992 APSB_A_lowPowerRequest "APSB ECU: a low power request";
CM_ SG_ 992 APSB_A_lowPowerRequestor "APSB ECU: a low power requestor";
CM_ SG_ 992 APSB_A_forcePowerOffRequest "APSB ECU: a force power off request";
CM_ SG_ 992 APSB_B_lowPowerRequest "APSB ECU: b low power request";
CM_ SG_ 992 APSB_B_lowPowerRequestor "APSB ECU: b low power requestor";
CM_ SG_ 992 APSB_B_forcePowerOffRequest "APSB ECU: b force power off request";
CM_ BO_ 1864 "APSB ECU message: state";
CM_ SG_ 1864 APSB_primaryTurbo "APSB ECU: primary turbo";
CM_ SG_ 1864 APSB_A_arbState "APSB ECU: a arb state";
CM_ SG_ 1864 APSB_A_powerState "The state of the power state machine of Turbo A.";
CM_ SG_ 1864 APSB_A_sleepState "APSB ECU: a sleep state";
CM_ SG_ 1864 APSB_A_resetState "APSB ECU: a reset state";
CM_ SG_ 1864 APSB_A_faultState "APSB ECU: a fault state";
CM_ SG_ 1864 APSB_secondaryTurbo "APSB ECU: secondary turbo";
CM_ SG_ 1864 APSB_B_arbState "APSB ECU: b arb state";
CM_ SG_ 1864 APSB_B_powerState "The state of the power state machine of Turbo B.";
CM_ SG_ 1864 APSB_B_sleepState "APSB ECU: b sleep state";
CM_ SG_ 1864 APSB_B_resetState "APSB ECU: b reset state";
CM_ SG_ 1864 APSB_B_faultState "APSB ECU: b fault state";
CM_ SG_ 1864 APSB_A_autosteerMonitorState "The state of the autosteer Monitor state machine for TurboA.";
CM_ SG_ 1864 APSB_B_autosteerMonitorState "The state of the autosteer Monitor state machine for TurboB.";
CM_ SG_ 1864 APSB_eplannerState "The state of the Eplanner of Turbo B.";
CM_ SG_ 1864 APSB_A_faultInduced "SGK Fault induced on Turbo A or not.";
CM_ SG_ 1864 APSB_B_faultInduced "SGK Fault induced on Turbo B or not.";
CM_ SG_ 1864 APSB_stateCounter "APSB ECU: state counter";
CM_ BO_ 971 "APSB ECU message: status";
CM_ SG_ 971 APSB_appStatusMonitorState "APSB ECU: app status monitor state";
CM_ SG_ 971 APSB_vehBehaviorState "APSB ECU: veh behavior state";
CM_ SG_ 971 APSB_canMaster "Indicates which of the autopilot computers is currently controlling outgoing CAN traffic; raw 3 = signal not available (SNA)";
CM_ SG_ 971 APSB_appGpioState "APSB ECU: app gpio state";
CM_ SG_ 971 APSB_eacInternalState "APSB ECU: eac internal state";
CM_ SG_ 971 APSB_switchState "APSB ECU: switch state";
CM_ SG_ 971 APSB_apbStatusMonitorState "APSB ECU: apb status monitor state";
CM_ SG_ 971 APSB_apbGpioState "APSB ECU: apb gpio state";
CM_ SG_ 971 APSB_statusCounter "APSB ECU: status counter";
CM_ SG_ 971 APSB_locLimitReason "APSB ECU: loc limit reason";
CM_ SG_ 971 APSB_appPowerStateRequest "APSB ECU: app power state request";
CM_ SG_ 971 APSB_appPowerStateReason "APSB ECU: app power state reason";
CM_ SG_ 971 APSB_apbPowerStateRequest "APSB ECU: apb power state request";
CM_ SG_ 971 APSB_apbPowerStateReason "APSB ECU: apb power state reason";
CM_ SG_ 971 APSB_heaterStateDebug "APSB ECU: heater state debug; raw 7 = signal not available (SNA)";
CM_ SG_ 971 APSB_autosummonCounter "APSB ECU: autosummon counter";
CM_ SG_ 971 APSB_autosummonAlert "APSB ECU: autosummon alert";
CM_ SG_ 971 APSB_gpsAntennaState "APSB ECU: gps antenna state";
CM_ SG_ 971 APSB_arbState "APSB ECU: arb state";
CM_ SG_ 971 APSB_socPowerOperatingMode "APSB ECU: soc power operating mode";
CM_ BO_ 845 "APSB ECU message: warning matrix0";
CM_ SG_ 845 APSB_w001_DEPRECATED "APSB ECU: w001 DEPRECATED";
CM_ SG_ 845 APSB_w002_ldwDisabled "APSB ECU: w002 ldw disabled";
CM_ SG_ 845 APSB_w003_isaDisabled "APSB ECU: w003 isa disabled";
CM_ SG_ 845 APSB_w004_accDisabled "APSB ECU: w004 acc disabled";
CM_ SG_ 845 APSB_w005_fcwCancelled "APSB ECU: w005 fcw cancelled";
CM_ SG_ 845 APSB_w006_aebCancelled "APSB ECU: w006 aeb cancelled";
CM_ SG_ 845 APSB_w007_ahlbDisabled "APSB ECU: w007 ahlb disabled";
CM_ SG_ 845 APSB_w008_parkDisabled "APSB ECU: w008 park disabled";
CM_ SG_ 845 APSB_w009_aebFault "APSB ECU: w009 aeb fault";
CM_ SG_ 845 APSB_w010_radcCalibIssue "APSB ECU: w010 radc calib issue";
CM_ SG_ 845 APSB_w011_scaEvent "APSB ECU: w011 sca event";
CM_ SG_ 845 APSB_w012_Cam_BootFailure "APSB ECU: w012 cam boot failure";
CM_ SG_ 845 APSB_w013_Cam_Watchdog "APSB ECU: w013 cam watchdog";
CM_ SG_ 845 APSB_w014_swAssert "APSB ECU: w014 sw assert";
CM_ SG_ 845 APSB_w015_Camera_Failsafes "APSB ECU: w015 camera failsafes";
CM_ SG_ 845 APSB_w016_aeb_e_event "APSB ECU: w016 aeb e event";
CM_ SG_ 845 APSB_w017_Cam_Msg_MIA "APSB ECU: w017 cam msg MIA";
CM_ SG_ 845 APSB_w018_ECU_Power_Issue "APSB ECU: w018 ECU power issue";
CM_ SG_ 845 APSB_w019_ECU_Stack_Overflow "APSB ECU: w019 ECU stack overflow";
CM_ SG_ 845 APSB_w020_ECU_checkstopError "APSB ECU: w020 ECU checkstop error";
CM_ SG_ 845 APSB_w021_ECU_Temperature_Issue "APSB ECU: w021 ECU temperature issue";
CM_ SG_ 845 APSB_w022_ECU_EEPROM_Failure "APSB ECU: w022 ECU EEPROM failure";
CM_ SG_ 845 APSB_w023_ECU_Cam_Statemismatc "APSB ECU: w023 ECU cam statemismatc";
CM_ SG_ 845 APSB_w024_ECU_Watchdog_Reset "APSB ECU: w024 ECU watchdog reset";
CM_ SG_ 845 APSB_w025_LC_Steering_Override "APSB ECU: w025 LC steering override";
CM_ SG_ 845 APSB_w026_ECU_timingIssue "APSB ECU: w026 ECU timing issue";
CM_ SG_ 845 APSB_w027_ECU_Reset_Fault "APSB ECU: w027 ECU reset fault";
CM_ SG_ 845 APSB_w028_spi_rx_error "APSB ECU: w028 spi rx error";
CM_ SG_ 845 APSB_w029_spi_tx_error "APSB ECU: w029 spi tx error";
CM_ SG_ 845 APSB_w030_Heater_Issue "APSB ECU: w030 heater issue";
CM_ SG_ 845 APSB_w031_canRxError "APSB ECU: w031 can rx error";
CM_ SG_ 845 APSB_w032_canTxError "APSB ECU: w032 can tx error";
CM_ SG_ 845 APSB_w033_gtwMia "APSB ECU: w033 gtw mia";
CM_ SG_ 845 APSB_w034_sccmMia "APSB ECU: w034 sccm mia";
CM_ SG_ 845 APSB_w035_espMia "APSB ECU: w035 esp mia";
CM_ SG_ 845 APSB_w036_bdyMia "APSB ECU: w036 bdy mia";
CM_ SG_ 845 APSB_w037_camTacIssue "APSB ECU: w037 cam tac issue";
CM_ SG_ 845 APSB_w038_camFailure "APSB ECU: w038 cam failure";
CM_ SG_ 845 APSB_w039_sdm_rcm_Mia "APSB ECU: w039 sdm rcm mia";
CM_ SG_ 845 APSB_w040_autopilotAngleSaturate "APSB ECU: w040 autopilot angle saturated";
CM_ SG_ 845 APSB_w041_autopilotRateSaturated "APSB ECU: w041 autopilot rate saturated";
CM_ SG_ 845 APSB_w042_autopilotAborting "APSB ECU: w042 autopilot aborting";
CM_ SG_ 845 APSB_w043_camLongRunTime "APSB ECU: w043 cam long run time";
CM_ SG_ 845 APSB_w044_appMobileyeFailure "APSB ECU: w044 app mobileye failure";
CM_ SG_ 845 APSB_w045_radMia "APSB ECU: w045 rad mia";
CM_ SG_ 845 APSB_w046_eepromRecordAbsent "APSB ECU: w046 eeprom record absent";
CM_ SG_ 845 APSB_w047_edrEvent "APSB ECU: w047 edr event";
CM_ SG_ 845 APSB_w048_DAS_Features_Disabled "APSB ECU: w048 DAS features disabled";
CM_ SG_ 845 APSB_w049_eyeqVersionMismatch "APSB ECU: w049 eyeq version mismatch";
CM_ SG_ 845 APSB_w050_aeb_event "APSB ECU: w050 aeb event";
CM_ SG_ 845 APSB_w051_radcEcuIssue "APSB ECU: w051 radc ecu issue";
CM_ SG_ 845 APSB_w052_radcSensorIssue "APSB ECU: w052 radc sensor issue";
CM_ SG_ 845 APSB_w053_radcCommIssue "APSB ECU: w053 radc comm issue";
CM_ SG_ 845 APSB_w054_camAutofix "APSB ECU: w054 cam autofix";
CM_ SG_ 845 APSB_w055_radcVersionMismatch "APSB ECU: w055 radc version mismatch";
CM_ SG_ 845 APSB_w056_diMia "APSB ECU: w056 di mia";
CM_ SG_ 845 APSB_w057_mcuMia "APSB ECU: w057 mcu mia";
CM_ SG_ 845 APSB_w058_epbMia "APSB ECU: w058 epb mia";
CM_ SG_ 845 APSB_w059_parkMia "APSB ECU: w059 park mia";
CM_ SG_ 845 APSB_w060_fcw_event "APSB ECU: w060 fcw event";
CM_ SG_ 845 APSB_w061_tasMia "APSB ECU: w061 tas mia";
CM_ SG_ 845 APSB_w062_radcAlignment "APSB ECU: w062 radc alignment";
CM_ SG_ 845 APSB_w063_parkVersionMismatch "APSB ECU: w063 park version mismatch";
CM_ SG_ 845 APSB_w064_epasMia "APSB ECU: w064 epas mia";
CM_ BO_ 1143 "APSB ECU message: warning matrix1";
CM_ SG_ 1143 APSB_w065_deserializerOvercurren "APSB ECU: w065 deserializer overcurrent";
CM_ SG_ 1143 APSB_w066_deserializerLockLost "APSB ECU: w066 deserializer lock lost";
CM_ SG_ 1143 APSB_w067_steeringAlignment "APSB ECU: w067 steering alignment";
CM_ SG_ 1143 APSB_w068_vlInconsistency "APSB ECU: w068 vl inconsistency";
CM_ SG_ 1143 APSB_w069_apcSpaceMasked "APSB ECU: w069 apc space masked";
CM_ SG_ 1143 APSB_w070_apcIncompleteCal "APSB ECU: w070 apc incomplete cal";
CM_ SG_ 1143 APSB_w071_selfparkStarted "APSB ECU: w071 selfpark started";
CM_ SG_ 1143 APSB_w072_selfparkComplete "APSB ECU: w072 selfpark complete";
CM_ SG_ 1143 APSB_w073_issueEscalatedLDW "APSB ECU: w073 issue escalated LDW";
CM_ SG_ 1143 APSB_w074_inPathStationaryObst "APSB ECU: w074 in path stationary obst";
CM_ SG_ 1143 APSB_w075_scMia "APSB ECU: w075 sc mia";
CM_ SG_ 1143 APSB_w076_mobilEyeSetC "APSB ECU: w076 mobil eye set c";
CM_ SG_ 1143 APSB_w077_pmmActive "APSB ECU: w077 pmm active";
CM_ SG_ 1143 APSB_w078_pmmActive2 "APSB ECU: w078 pmm active2";
CM_ SG_ 1143 APSB_w079_edrAvailable "APSB ECU: w079 edr available";
CM_ SG_ 1143 APSB_w080_accFailedActivation "APSB ECU: w080 acc failed activation";
CM_ SG_ 1143 APSB_w081_pmmActiveBraking "APSB ECU: w081 pmm active braking";
CM_ SG_ 1143 APSB_w082_inPathFSviolation "APSB ECU: w082 in path f sviolation";
CM_ SG_ 1143 APSB_w083_inPathRADObject "APSB ECU: w083 in path RAD object";
CM_ SG_ 1143 APSB_w084_pmmIPSO "APSB ECU: w084 pmm IPSO";
CM_ SG_ 1143 APSB_w085_pmmSteering "APSB ECU: w085 pmm steering";
CM_ SG_ 1143 APSB_w086_robCollision "APSB ECU: w086 rob collision";
CM_ SG_ 1143 APSB_w087_DEPRECATED "APSB ECU: w087 DEPRECATED";
CM_ SG_ 1143 APSB_w088_DEPRECATED "APSB ECU: w088 DEPRECATED";
CM_ SG_ 1143 APSB_w089_DEPRECATED "APSB ECU: w089 DEPRECATED";
CM_ SG_ 1143 APSB_w090_DEPRECATED "APSB ECU: w090 DEPRECATED";
CM_ SG_ 1143 APSB_w091_DEPRECATED "APSB ECU: w091 DEPRECATED";
CM_ SG_ 1143 APSB_w092_DEPRECATED "APSB ECU: w092 DEPRECATED";
CM_ SG_ 1143 APSB_w093_DEPRECATED "APSB ECU: w093 DEPRECATED";
CM_ SG_ 1143 APSB_w094_DEPRECATED "APSB ECU: w094 DEPRECATED";
CM_ SG_ 1143 APSB_w095_DEPRECATED "APSB ECU: w095 DEPRECATED";
CM_ SG_ 1143 APSB_w096_DEPRECATED "APSB ECU: w096 DEPRECATED";
CM_ SG_ 1143 APSB_w097_DEPRECATED "APSB ECU: w097 DEPRECATED";
CM_ SG_ 1143 APSB_w098_DEPRECATED "APSB ECU: w098 DEPRECATED";
CM_ SG_ 1143 APSB_w099_DEPRECATED "APSB ECU: w099 DEPRECATED";
CM_ SG_ 1143 APSB_w100_DEPRECATED "APSB ECU: w100 DEPRECATED";
CM_ SG_ 1143 APSB_w101_DEPRECATED "APSB ECU: w101 DEPRECATED";
CM_ SG_ 1143 APSB_w102_DEPRECATED "APSB ECU: w102 DEPRECATED";
CM_ SG_ 1143 APSB_w103_robExperimentalAEB "APSB ECU: w103 rob experimental AEB";
CM_ SG_ 1143 APSB_w104_DEPRECATED "APSB ECU: w104 DEPRECATED";
CM_ SG_ 1143 APSB_w105_DEPRECATED "APSB ECU: w105 DEPRECATED";
CM_ SG_ 1143 APSB_w106_torsionBarOffset "APSB ECU: w106 torsion bar offset";
CM_ BO_ 942 "APSB ECU message: warning matrix2";
CM_ SG_ 942 APSB_w129_ECU_Power_Issue "APSB ECU: w129 ECU power issue";
CM_ SG_ 942 APSB_w130_ECU_Thermal_Issue "APSB ECU: w130 ECU thermal issue";
CM_ SG_ 942 APSB_w131_trap_exception "APSB ECU: w131 trap exception";
CM_ SG_ 942 APSB_w132_appVersionMismatch "APSB ECU: w132 app version mismatch";
CM_ SG_ 942 APSB_w133_ETHSwitchError "APSB ECU: w133 ETH switch error";
CM_ SG_ 942 APSB_w134_appMia "APSB ECU: w134 app mia";
CM_ SG_ 942 APSB_w135_appCritical "APSB ECU: w135 app critical";
CM_ SG_ 942 APSB_w136_gpsDisabled "APSB ECU: w136 gps disabled";
CM_ SG_ 942 APSB_w137_gpsFaultReset "APSB ECU: w137 gps fault reset";
CM_ SG_ 942 APSB_w138_gpsComIssue "APSB ECU: w138 gps com issue";
CM_ SG_ 942 APSB_w139_udpBufferOverflow "APSB ECU: w139 udp buffer overflow";
CM_ SG_ 942 APSB_w140_vcfrontMiaVehicleBus "APSB ECU: w140 vcfront mia vehicle bus";
CM_ SG_ 942 APSB_w141_rcmMiaPartyBus "APSB ECU: w141 rcm mia party bus";
CM_ SG_ 942 APSB_w142_diMiaPartyBus "APSB ECU: w142 di mia party bus";
CM_ SG_ 942 APSB_w143_espMiaPartyBus "APSB ECU: w143 esp mia party bus";
CM_ SG_ 942 APSB_w144_vcleftMiaPartyBus "APSB ECU: w144 vcleft mia party bus";
CM_ SG_ 942 APSB_w145_vcrightMiaPartyBus "APSB ECU: w145 vcright mia party bus";
CM_ SG_ 942 APSB_w146_epas3pMiaPartyBus "APSB ECU: w146 epas3p mia party bus";
CM_ SG_ 942 APSB_w147_vcleftMiaVehBus "APSB ECU: w147 vcleft mia veh bus";
CM_ SG_ 942 APSB_w148_vcrightMiaVehBus "APSB ECU: w148 vcright mia veh bus";
CM_ SG_ 942 APSB_w149_epblMiaVehBus "APSB ECU: w149 epbl mia veh bus";
CM_ SG_ 942 APSB_w150_sccmMiaVehBus "APSB ECU: w150 sccm mia veh bus";
CM_ SG_ 942 APSB_w151_apRecovered "APSB ECU: w151 ap recovered";
CM_ SG_ 942 APSB_w152_gpsFusionStatus "APSB ECU: w152 gps fusion status";
CM_ SG_ 942 APSB_w153_eacInhibit "APSB ECU: w153 eac inhibit";
CM_ SG_ 942 APSB_w155_ethLwipError "APSB ECU: w155 eth lwip error";
CM_ SG_ 942 APSB_w156_lwipAssert "APSB ECU: w156 lwip assert";
CM_ SG_ 942 APSB_w157_autopilotReboot "APSB ECU: w157 autopilot reboot";
CM_ SG_ 942 APSB_w158_apbMia "APSB ECU: w158 apb mia";
CM_ SG_ 942 APSB_w159_apbCritical "APSB ECU: w159 apb critical";
CM_ SG_ 942 APSB_w160_apbVersionMismatch "APSB ECU: w160 apb version mismatch";
CM_ SG_ 942 APSB_w161_gpsAntennaDisconnected "APSB ECU: w161 gps antenna disconnected";
CM_ SG_ 942 APSB_w162_TurboA_DisRegPgoodErr "APSB ECU: w162 turbo a dis reg pgood err";
CM_ SG_ 942 APSB_w163_TurboA_DisRegNFault "APSB ECU: w163 turbo a dis reg n fault";
CM_ SG_ 942 APSB_w164_TurboA_12VFuseFault "APSB ECU: w164 turbo a 12 v fuse fault";
CM_ SG_ 942 APSB_w165_TurboA_Temp_NOS "APSB ECU: w165 turbo a temp NOS";
CM_ SG_ 942 APSB_w166_TurboA_SMSLockStepErr "APSB ECU: w166 turbo a SMS lock step err";
CM_ SG_ 942 APSB_w167_TurboA_TMU_Throttle "APSB ECU: w167 turbo a TMU throttle";
CM_ SG_ 942 APSB_w168_TurboA_SMS_WDOG "APSB ECU: w168 turbo a SMS WDOG";
CM_ SG_ 942 APSB_w169_TurboA_SCS_LKUP "APSB ECU: w169 turbo a SCS LKUP";
CM_ SG_ 942 APSB_w170_TurboA_A72_watchdog "APSB ECU: w170 turbo a A72 watchdog";
CM_ SG_ 942 APSB_w171_TurboA_SMS_taskUtilErr "APSB ECU: w171 turbo a SMS task util err";
CM_ SG_ 942 APSB_w172_apFeaturesUnavailable "APSB ECU: w172 ap features unavailable";
CM_ SG_ 942 APSB_w178_TurboB_DisRegPgoodErr "APSB ECU: w178 turbo b dis reg pgood err";
CM_ SG_ 942 APSB_w179_TurboB_DisRegNFault "APSB ECU: w179 turbo b dis reg n fault";
CM_ SG_ 942 APSB_w180_TurboB_12VFuseFault "APSB ECU: w180 turbo b 12 v fuse fault";
CM_ SG_ 942 APSB_w181_TurboB_Temp_NOS "APSB ECU: w181 turbo b temp NOS";
CM_ SG_ 942 APSB_w182_TurboB_SMSLockStepErr "APSB ECU: w182 turbo b SMS lock step err";
CM_ SG_ 942 APSB_w183_TurboB_TMU_Throttle "APSB ECU: w183 turbo b TMU throttle";
CM_ SG_ 942 APSB_w184_TurboB_SMS_WDOG "APSB ECU: w184 turbo b SMS WDOG";
CM_ SG_ 942 APSB_w185_TurboB_SCS_LKUP "APSB ECU: w185 turbo b SCS LKUP";
CM_ SG_ 942 APSB_w186_TurboB_A72_watchdog "APSB ECU: w186 turbo b A72 watchdog";
CM_ SG_ 942 APSB_w187_TurboB_SMS_taskUtilErr "APSB ECU: w187 turbo b SMS task util err";
CM_ SG_ 942 APSB_w188_otherTurboUartMIA "APSB ECU: w188 other turbo uart MIA";
CM_ SG_ 942 APSB_w189_vcfrontMiaPartyBus "APSB ECU: w189 vcfront mia party bus";
CM_ SG_ 942 APSB_w190_iboosterMia "APSB ECU: w190 ibooster mia";
CM_ SG_ 942 APSB_w191_timesyncError "APSB ECU: w191 timesync error";
CM_ SG_ 942 APSB_w192_CANFault "APSB ECU: w192 CAN fault";
CM_ BO_ 976 "APSB ECU message: warning matrix3";
CM_ SG_ 976 APSB_w193_camWindshieldUnclean "APSB ECU: w193 cam windshield unclean";
CM_ SG_ 976 APSB_w194_accDriverResumeRqrd "APSB ECU: w194 acc driver resume rqrd";
CM_ SG_ 976 APSB_w195_scwUnavailable "APSB ECU: w195 scw unavailable";
CM_ SG_ 976 APSB_w196_stopSignWarning "APSB ECU: w196 stop sign warning";
CM_ SG_ 976 APSB_w197_redLightWarning "APSB ECU: w197 red light warning";
CM_ SG_ 976 APSB_w198_tsrUnavailable "APSB ECU: w198 tsr unavailable";
CM_ SG_ 976 APSB_w199_apcAbort "APSB ECU: w199 apc abort";
CM_ SG_ 976 APSB_w200_lcSlowdown "APSB ECU: w200 lc slowdown";
CM_ SG_ 976 APSB_w201_lcAborting "APSB ECU: w201 lc aborting";
CM_ SG_ 976 APSB_w202_scwNoisyEnvironment "APSB ECU: w202 scw noisy environment";
CM_ SG_ 976 APSB_w203_apcActivation "APSB ECU: w203 apc activation";
CM_ SG_ 976 APSB_w204_apcFinalFront "APSB ECU: w204 apc final front";
CM_ SG_ 976 APSB_w205_apcFinalRear "APSB ECU: w205 apc final rear";
CM_ SG_ 976 APSB_w206_autosteerNotEnabled "APSB ECU: w206 autosteer not enabled";
CM_ SG_ 976 APSB_w207_autosteerUnavailable "APSB ECU: w207 autosteer unavailable";
CM_ SG_ 976 APSB_w208_rackDetected "APSB ECU: w208 rack detected";
CM_ SG_ 976 APSB_w209_autoSummonRequest "APSB ECU: w209 auto summon request";
CM_ SG_ 976 APSB_w210_camObstrcted "APSB ECU: w210 cam obstrcted";
CM_ SG_ 976 APSB_w211_accNoSeatBelt "APSB ECU: w211 acc no seat belt";
CM_ SG_ 976 APSB_w212_lcUnavailableStrikeOut "APSB ECU: w212 lc unavailable strike out";
CM_ SG_ 976 APSB_w213_autosteerStruckOut "APSB ECU: w213 autosteer struck out";
CM_ SG_ 976 APSB_w214_driverNotIntracting "APSB ECU: w214 driver not intracting";
CM_ SG_ 976 APSB_w215_contDriverNotIntractin "APSB ECU: w215 cont driver not intracting";
CM_ SG_ 976 APSB_w216_driverOverriding "APSB ECU: w216 driver overriding";
CM_ SG_ 976 APSB_w217_lcUnavailableSpeeding "APSB ECU: w217 lc unavailable speeding";
CM_ SG_ 976 APSB_w218_lcSpeedExceededLimit "APSB ECU: w218 lc speed exceeded limit";
CM_ SG_ 976 APSB_w219_lcTempUnavailableSpeed "APSB ECU: w219 lc temp unavailable speed";
CM_ SG_ 976 APSB_w220_lcTempUnavailableRoad "APSB ECU: w220 lc temp unavailable road";
CM_ SG_ 976 APSB_w221_accRadarBlind "APSB ECU: w221 acc radar blind";
CM_ SG_ 976 APSB_w222_accCameraBlind "APSB ECU: w222 acc camera blind";
CM_ SG_ 976 APSB_w223_accObjectInPath "APSB ECU: w223 acc object in path";
CM_ SG_ 976 APSB_w224_accCameraCalibration "APSB ECU: w224 acc camera calibration";
CM_ SG_ 976 APSB_w225_lcDegradedVisSpeedLmt "APSB ECU: w225 lc degraded vis speed lmt";
CM_ SG_ 976 APSB_w226_lcCamCalNeededSpeedLmt "APSB ECU: w226 lc cam cal needed speed lmt";
CM_ SG_ 976 APSB_w227_virtualWallBlocked "APSB ECU: w227 virtual wall blocked";
CM_ SG_ 976 APSB_w228_DEPRECATED "APSB ECU: w228 DEPRECATED";
CM_ SG_ 976 APSB_w229_alcUltrasoundDamaged "APSB ECU: w229 alc ultrasound damaged";
CM_ SG_ 976 APSB_w230_alcUltrasoundBlocked "APSB ECU: w230 alc ultrasound blocked";
CM_ SG_ 976 APSB_w231_idfEvent "APSB ECU: w231 idf event";
CM_ SG_ 976 APSB_w232_laneChangeRequested "APSB ECU: w232 lane change requested";
CM_ SG_ 976 APSB_w235_a72LoopDetected "APSB ECU: w235 a72 loop detected";
CM_ SG_ 976 APSB_w236_canSharedMemError "APSB ECU: w236 can shared mem error";
CM_ SG_ 976 APSB_w237_faultMgrEventDetected "APSB ECU: w237 fault mgr event detected";
CM_ SG_ 976 APSB_w238_resetReason "APSB ECU: w238 reset reason";
CM_ SG_ 976 APSB_w241_ddrInitFailures "APSB ECU: w241 ddr init failures";
CM_ SG_ 976 APSB_w242_tripMBISTFailure "APSB ECU: w242 trip MBIST failure";
CM_ SG_ 976 APSB_w243_tripHWErrorStatus "APSB ECU: w243 trip HW error status";
CM_ SG_ 976 APSB_w244_gpuHWFaultStatus "APSB ECU: w244 gpu HW fault status";
CM_ SG_ 976 APSB_w245_eloopRxFromUnexpectedS "APSB ECU: w245 eloop rx from unexpected source MAC";
CM_ SG_ 976 APSB_w246_ethloopSwitchPortLinkD "APSB ECU: w246 ethloop switch port link down";
CM_ SG_ 976 APSB_w247_ethernetFrameError "APSB ECU: w247 ethernet frame error";
CM_ SG_ 976 APSB_w248_ethloopSwitchPoorSqi "APSB ECU: w248 ethloop switch poor sqi";
CM_ SG_ 976 APSB_w249_ufsFailures "APSB ECU: w249 ufs failures";
CM_ SG_ 976 APSB_w250_ethloopSwitchMemUsageT "APSB ECU: w250 ethloop switch mem usage too high port2";
CM_ SG_ 976 APSB_w251_ethloopSwitchMemUsageT "APSB ECU: w251 ethloop switch mem usage too high port3";
CM_ SG_ 976 APSB_w252_ethSwitchPortLinkDown "APSB ECU: w252 eth switch port link down";
CM_ SG_ 976 APSB_w253_powerStateTimeout "APSB ECU: w253 power state timeout";
CM_ SG_ 976 APSB_w254_sleepStateTimeout "APSB ECU: w254 sleep state timeout";
CM_ SG_ 976 APSB_w255_bootHealth "APSB ECU: w255 boot health";
CM_ BO_ 1003 "APSB ECU message: warning matrix4";
CM_ SG_ 1003 APSB_w257_assertFailure "APSB ECU: w257 assert failure";
CM_ SG_ 1003 APSB_w258_qspiFlashSectorChecksu "APSB ECU: w258 qspi flash sector checksum mismatch";
CM_ SG_ 1003 APSB_w259_qspiFailure "APSB ECU: w259 qspi failure";
CM_ SG_ 1003 APSB_w260_pgoodFailure "APSB ECU: w260 pgood failure";
CM_ SG_ 1003 APSB_w261_vrmFaultGrpA "APSB ECU: w261 vrm fault grp a";
CM_ SG_ 1003 APSB_w262_vrmFaultGrpB "APSB ECU: w262 vrm fault grp b";
CM_ SG_ 1003 APSB_w263_vrmFaultGrpC "APSB ECU: w263 vrm fault grp c";
CM_ SG_ 1003 APSB_w264_ddrPhy0Failures "APSB ECU: w264 ddr phy0 failures";
CM_ SG_ 1003 APSB_w265_ddrPhy1Failures "APSB ECU: w265 ddr phy1 failures";
CM_ SG_ 1003 APSB_w266_ddrPhy2Failures "APSB ECU: w266 ddr phy2 failures";
CM_ SG_ 1003 APSB_w267_ddrPhy3Failures "APSB ECU: w267 ddr phy3 failures";
CM_ SG_ 1003 APSB_w268_ddrControllerFailures "APSB ECU: w268 ddr controller failures";
CM_ SG_ 1003 APSB_w269_ethSwitchRxPageCountTo "APSB ECU: w269 eth switch rx page count too high port0 3";
CM_ SG_ 1003 APSB_w270_ethSwitchRxPageCountTo "APSB ECU: w270 eth switch rx page count too high port4 7";
CM_ SG_ 1003 APSB_w271_ddrScheduler0EccErrors "APSB ECU: w271 ddr scheduler0 ecc errors";
CM_ SG_ 1003 APSB_w272_ddrScheduler1EccErrors "APSB ECU: w272 ddr scheduler1 ecc errors";
CM_ SG_ 1003 APSB_w273_ddrScheduler2EccErrors "APSB ECU: w273 ddr scheduler2 ecc errors";
CM_ SG_ 1003 APSB_w274_ddrScheduler3EccErrors "APSB ECU: w274 ddr scheduler3 ecc errors";
CM_ SG_ 1003 APSB_w275_ddrScheduler4EccErrors "APSB ECU: w275 ddr scheduler4 ecc errors";
CM_ SG_ 1003 APSB_w276_ddrScheduler5EccErrors "APSB ECU: w276 ddr scheduler5 ecc errors";
CM_ SG_ 1003 APSB_w277_ddrScheduler6EccErrors "APSB ECU: w277 ddr scheduler6 ecc errors";
CM_ SG_ 1003 APSB_w278_ddrScheduler7EccErrors "APSB ECU: w278 ddr scheduler7 ecc errors";
CM_ SG_ 1003 APSB_w279_ufsPartitionError "APSB ECU: w279 ufs partition error";
CM_ SG_ 1003 APSB_w280_pepsMia "APSB ECU: w280 peps mia";
CM_ SG_ 1003 APSB_w281_rsaMia "APSB ECU: w281 rsa mia";
CM_ SG_ 1003 APSB_w282_smmuError "APSB ECU: w282 smmu error";
CM_ SG_ 1003 APSB_w283_psfaMia "APSB ECU: w283 psfa mia";
CM_ SG_ 1003 APSB_w284_cam12VBuckBoostAPwrIss "APSB ECU: w284 cam12 v buck boost a pwr issue";
CM_ SG_ 1003 APSB_w285_cam12VBuckBoostBPwrIss "APSB ECU: w285 cam12 v buck boost b pwr issue";
CM_ SG_ 1003 APSB_w286_cam12VEFuseAPrimaryIss "APSB ECU: w286 cam12 VE fuse a primary issue";
CM_ SG_ 1003 APSB_w287_cam12VEFuseASecondaryI "APSB ECU: w287 cam12 VE fuse a secondary issue";
CM_ SG_ 1003 APSB_w288_brakeboosterMia "APSB ECU: w288 brakebooster mia";
CM_ SG_ 1003 APSB_w289_turboTemperatureWarnin "APSB ECU: w289 turbo temperature warning";
CM_ SG_ 1003 APSB_w290_cam12VBuckBoostBPwrRin "APSB ECU: w290 cam12 v buck boost b pwr ringing";
CM_ SG_ 1003 APSB_w291_eplannerError "APSB ECU: w291 eplanner error";
CM_ SG_ 1003 APSB_w292_CH_busOff "APSB ECU: w292 CH bus off";
CM_ SG_ 1003 APSB_w293_PARTY_busOff "APSB ECU: w293 PARTY bus off";
CM_ SG_ 1003 APSB_w294_VEH_busOff "APSB ECU: w294 VEH bus off";
CM_ SG_ 1003 APSB_w295_PT_busOff "APSB ECU: w295 PT bus off";
CM_ SG_ 1003 APSB_w296_wdogMonTaskDeadlineMis "APSB ECU: w296 wdog mon task deadline miss";
CM_ SG_ 1003 APSB_w297_earlyWDogAlert "APSB ECU: w297 early w dog alert";
CM_ SG_ 1003 APSB_w298_cpuToApCanSharedMemErr "APSB ECU: w298 cpu to ap can shared mem error";
CM_ SG_ 1003 APSB_w299_apToCpuCanSharedMemErr "APSB ECU: w299 ap to cpu can shared mem error";
CM_ SG_ 1003 APSB_w300_sharedMemoryAccessErro "APSB ECU: w300 shared memory access error";
CM_ SG_ 1003 APSB_w301_nocTimeoutDetected "APSB ECU: w301 noc timeout detected";
CM_ SG_ 1003 APSB_w302_canAPShmFifoFull "APSB ECU: w302 can AP shm fifo full";
CM_ SG_ 1003 APSB_w303_canAPShmFifoEmpty "APSB ECU: w303 can AP shm fifo empty";
CM_ SG_ 1003 APSB_w304_dataAbort "APSB ECU: w304 data abort";
CM_ SG_ 1003 APSB_w305_gpsPgoodFailure "APSB ECU: w305 gps pgood failure";
CM_ SG_ 1003 APSB_w306_ethPgoodFailure "APSB ECU: w306 eth pgood failure";
CM_ SG_ 1003 APSB_w307_eccEventDetected "APSB ECU: w307 ecc event detected";
CM_ SG_ 1003 APSB_w308_pmicErrorDetected "APSB ECU: w308 pmic error detected";
CM_ SG_ 1003 APSB_w309_ethBridgeDown "APSB ECU: w309 eth bridge down";
CM_ SG_ 1003 APSB_w310_wakeBootMetrics "APSB ECU: w310 wake boot metrics";
CM_ SG_ 1003 APSB_w311_apbdgDasMia "APSB ECU: w311 apbdg das mia";
CM_ SG_ 1003 APSB_w312_apbdgApMia "APSB ECU: w312 apbdg ap mia";
CM_ SG_ 1003 APSB_w313_BDY_busOff "APSB ECU: w313 BDY bus off";
CM_ SG_ 1003 APSB_w315_epas3pMiaBdyBus "APSB ECU: w315 epas3p mia bdy bus";
CM_ SG_ 1003 APSB_w316_apBootHealth "APSB ECU: w316 ap boot health";
CM_ SG_ 1003 APSB_w317_uiMia "APSB ECU: w317 ui mia";
CM_ SG_ 1003 APSB_w318_ethernetNetworkBufferH "APSB ECU: w318 ethernet network buffer high watermark";
CM_ SG_ 1003 APSB_w319_vehDasImposterDetected "APSB ECU: w319 veh das imposter detected";
CM_ SG_ 1003 APSB_w320_eplannerPreconditionsM "APSB ECU: w320 eplanner preconditions met";
BA_DEF_ BO_ "GenMsgCycleTime" INT 0 3600000;
BA_DEF_ BO_ "GenMsgSendType" ENUM "Cyclic","NotUsed","NotUsed","NotUsed","NotUsed","NotUsed","NotUsed","IfActive","NoMsgSendType","NotUsed";
BA_DEF_ BO_ "VFrameFormat" ENUM "StandardCAN","ExtendedCAN","reserved","J1939PG","reserved","reserved","reserved","reserved","reserved","reserved","reserved","reserved","reserved","reserved","StandardCAN_FD","ExtendedCAN_FD";
BA_DEF_ BO_ "CANFD_BRS" ENUM "0","1";
BA_DEF_ SG_ "GenSigSNA" STRING;
BA_DEF_ SG_ "SystemSignalLongSymbol" STRING;
BA_DEF_ SG_ "Confidence" ENUM "validated","plausible","layout-only","contradicted";
BA_DEF_DEF_ "GenMsgCycleTime" 0;
BA_DEF_DEF_ "GenMsgSendType" "NoMsgSendType";
BA_DEF_DEF_ "VFrameFormat" "StandardCAN";
BA_DEF_DEF_ "CANFD_BRS" "1";
BA_DEF_DEF_ "GenSigSNA" "";
BA_DEF_DEF_ "SystemSignalLongSymbol" "";
BA_DEF_DEF_ "Confidence" "layout-only";
BA_ "GenMsgCycleTime" BO_ 731 100;
BA_ "GenMsgSendType" BO_ 731 0;
BA_ "GenMsgCycleTime" BO_ 992 100;
BA_ "GenMsgSendType" BO_ 992 0;
BA_ "GenMsgCycleTime" BO_ 1864 100;
BA_ "GenMsgSendType" BO_ 1864 0;
BA_ "GenMsgCycleTime" BO_ 971 500;
BA_ "GenMsgSendType" BO_ 971 0;
BA_ "GenMsgCycleTime" BO_ 845 1000;
BA_ "GenMsgSendType" BO_ 845 0;
BA_ "GenMsgCycleTime" BO_ 1143 1000;
BA_ "GenMsgSendType" BO_ 1143 0;
BA_ "GenMsgCycleTime" BO_ 942 1000;
BA_ "GenMsgSendType" BO_ 942 0;
BA_ "GenMsgCycleTime" BO_ 976 1000;
BA_ "GenMsgSendType" BO_ 976 0;
BA_ "GenMsgCycleTime" BO_ 1003 1000;
BA_ "GenMsgSendType" BO_ 1003 0;
BA_ "Confidence" SG_ 1482 APSB_alertID 1;
BA_ "Confidence" SG_ 1482 APSB_alertSource 1;
BA_ "Confidence" SG_ 1482 APSB_alertState 1;
BA_ "Confidence" SG_ 1482 APSB_sw010_HorizontalMisalignmen 1;
BA_ "SystemSignalLongSymbol" SG_ 1482 APSB_sw010_HorizontalMisalignmen "APSB_sw010_HorizontalMisalignment";
BA_ "Confidence" SG_ 1482 APSB_sw010_VerticalMisalignment 1;
BA_ "Confidence" SG_ 1482 APSB_sw010_VmaPlausibility 1;
BA_ "Confidence" SG_ 1482 APSB_sw019_taskId 1;
BA_ "Confidence" SG_ 1482 APSB_sw019_numFreeBytes 1;
BA_ "Confidence" SG_ 1482 APSB_sw019_timeStamp 1;
BA_ "Confidence" SG_ 1482 APSB_sw021_minThreshold 1;
BA_ "Confidence" SG_ 1482 APSB_sw021_maxThreshold 1;
BA_ "Confidence" SG_ 1482 APSB_sw021_currentTemperature 1;
BA_ "SystemSignalLongSymbol" SG_ 1482 APSB_sw035_redundantBrakingStatu "APSB_sw035_redundantBrakingStatus";
BA_ "SystemSignalLongSymbol" SG_ 1482 APSB_sw053_a34steerAngSpdValidit "APSB_sw053_a34steerAngSpdValidity";
BA_ "SystemSignalLongSymbol" SG_ 1482 APSB_sw053_a61radPositionMismatc "APSB_sw053_a61radPositionMismatch";
BA_ "Confidence" SG_ 1482 APSB_sw070_temperature 1;
BA_ "Confidence" SG_ 1482 APSB_sw070_currentSpeed 1;
BA_ "Confidence" SG_ 1482 APSB_sw071_endPosX 1;
BA_ "Confidence" SG_ 1482 APSB_sw071_endPosY 1;
BA_ "Confidence" SG_ 1482 APSB_sw071_temperature 1;
BA_ "Confidence" SG_ 1482 APSB_sw072_vehicleX 1;
BA_ "Confidence" SG_ 1482 APSB_sw072_vehicleY 1;
BA_ "Confidence" SG_ 1482 APSB_sw072_vehicleHeading 1;
BA_ "Confidence" SG_ 1482 APSB_sw072_endDistance 1;
BA_ "Confidence" SG_ 1482 APSB_sw077_oocDistance 1;
BA_ "Confidence" SG_ 1482 APSB_sw077_oocConfidence 1;
BA_ "Confidence" SG_ 1482 APSB_sw077_vehicleSpeed 1;
BA_ "Confidence" SG_ 1482 APSB_sw077_oocUntrackedTime 1;
BA_ "Confidence" SG_ 1482 APSB_sw081_radarDistance 1;
BA_ "Confidence" SG_ 1482 APSB_sw081_radarTTC 1;
BA_ "Confidence" SG_ 1482 APSB_sw081_cameraDistance 1;
BA_ "Confidence" SG_ 1482 APSB_sw081_cameraTTC 1;
BA_ "Confidence" SG_ 1482 APSB_sw081_pedalPosition 1;
BA_ "Confidence" SG_ 1482 APSB_sw129_currentVoltage 1;
BA_ "Confidence" SG_ 1482 APSB_sw129_maxThreshold 1;
BA_ "Confidence" SG_ 1482 APSB_sw129_minThreshold 1;
BA_ "Confidence" SG_ 1482 APSB_sw129_railID 1;
BA_ "Confidence" SG_ 1482 APSB_sw130_currentTemperature 1;
BA_ "Confidence" SG_ 1482 APSB_sw130_maxThreshold 1;
BA_ "Confidence" SG_ 1482 APSB_sw130_minThreshold 1;
BA_ "SystemSignalLongSymbol" SG_ 1482 APSB_sw130_shouldBlockOkToPowerA "APSB_sw130_shouldBlockOkToPowerAp";
BA_ "Confidence" SG_ 1482 APSB_sw132_mismatchType 1;
BA_ "SystemSignalLongSymbol" SG_ 1482 APSB_sw133_switchEthernetInterLi "APSB_sw133_switchEthernetInterLinkDown";
BA_ "SystemSignalLongSymbol" SG_ 1482 APSB_sw133_ethSwitchReadFwVerFai "APSB_sw133_ethSwitchReadFwVerFailed";
BA_ "SystemSignalLongSymbol" SG_ 1482 APSB_sw133_ethSwitchTimedoutUpda "APSB_sw133_ethSwitchTimedoutUpdate";
BA_ "SystemSignalLongSymbol" SG_ 1482 APSB_sw133_ethSwitchMcuLinkFailo "APSB_sw133_ethSwitchMcuLinkFailover";
BA_ "SystemSignalLongSymbol" SG_ 1482 APSB_sw133_ethSwitchMcuLinkDupli "APSB_sw133_ethSwitchMcuLinkDuplicated";
BA_ "SystemSignalLongSymbol" SG_ 1482 APSB_sw133_ethSwitchMcuLinkDisco "APSB_sw133_ethSwitchMcuLinkDisconnected";
BA_ "SystemSignalLongSymbol" SG_ 1482 APSB_sw134_dasAutonomyControlPar "APSB_sw134_dasAutonomyControlParty";
BA_ "SystemSignalLongSymbol" SG_ 1482 APSB_sw134_dasMatrixHighBeamRqVE "APSB_sw134_dasMatrixHighBeamRqVEH";
BA_ "SystemSignalLongSymbol" SG_ 1482 APSB_sw134_dasMatrixBendAngleRqP "APSB_sw134_dasMatrixBendAngleRqPty";
BA_ "SystemSignalLongSymbol" SG_ 1482 APSB_sw134_dasRedundantBrakingCo "APSB_sw134_dasRedundantBrakingControl";
BA_ "SystemSignalLongSymbol" SG_ 1482 APSB_sw134_dasRedundantBrak_0001 "APSB_sw134_dasRedundantBrakingControlPty";
BA_ "Confidence" SG_ 1482 APSB_sw135_appCriticalReason 1;
BA_ "SystemSignalLongSymbol" SG_ 1482 APSB_sw143_redundantBrakingStatu "APSB_sw143_redundantBrakingStatus";
BA_ "Confidence" SG_ 1482 APSB_sw153_eacInhibitReason 1;
BA_ "Confidence" SG_ 1482 APSB_sw153_eacInternalState 1;
BA_ "SystemSignalLongSymbol" SG_ 1482 APSB_sw158_dasAutonomyControlPar "APSB_sw158_dasAutonomyControlParty";
BA_ "SystemSignalLongSymbol" SG_ 1482 APSB_sw158_dasMatrixHighBeamRqVE "APSB_sw158_dasMatrixHighBeamRqVEH";
BA_ "SystemSignalLongSymbol" SG_ 1482 APSB_sw158_dasMatrixBendAngleRqP "APSB_sw158_dasMatrixBendAngleRqPty";
BA_ "SystemSignalLongSymbol" SG_ 1482 APSB_sw158_dasRedundantBrakingCo "APSB_sw158_dasRedundantBrakingControl";
BA_ "SystemSignalLongSymbol" SG_ 1482 APSB_sw158_dasRedundantBrak_0001 "APSB_sw158_dasRedundantBrakingControlPty";
BA_ "Confidence" SG_ 1482 APSB_sw159_apbCriticalReason 1;
BA_ "Confidence" SG_ 1482 APSB_sw160_mismatchType 1;
BA_ "Confidence" SG_ 1482 APSB_sw188_otherTurbo 1;
BA_ "Confidence" SG_ 1482 APSB_sw192_CANbus 1;
BA_ "Confidence" SG_ 1482 APSB_sw192_msgIo 1;
BA_ "Confidence" SG_ 1482 APSB_sw192_queueFailure 1;
BA_ "Confidence" SG_ 1482 APSB_sw199_abortCodeDas 1;
BA_ "Confidence" SG_ 1482 APSB_sw199_abortCodePARK 1;
BA_ "GenSigSNA" SG_ 1482 APSB_sw199_abortCodePARK "31";
BA_ "Confidence" SG_ 1482 APSB_sw199_currentSTW 1;
BA_ "Confidence" SG_ 1482 APSB_sw199_currentSpeed 1;
BA_ "Confidence" SG_ 1482 APSB_sw199_maxSpeed 1;
BA_ "Confidence" SG_ 1482 APSB_sw203_controlType 1;
BA_ "GenSigSNA" SG_ 1482 APSB_sw203_controlType "15";
BA_ "Confidence" SG_ 1482 APSB_sw203_slotSizeX 1;
BA_ "Confidence" SG_ 1482 APSB_sw203_slotSizeY 1;
BA_ "Confidence" SG_ 1482 APSB_sw203_startDistance 1;
BA_ "Confidence" SG_ 1482 APSB_sw203_vehicleSkew 1;
BA_ "Confidence" SG_ 1482 APSB_sw204_frLeft 1;
BA_ "Confidence" SG_ 1482 APSB_sw204_frLeftMiddle 1;
BA_ "Confidence" SG_ 1482 APSB_sw204_frMiddle 1;
BA_ "Confidence" SG_ 1482 APSB_sw204_frRight 1;
BA_ "Confidence" SG_ 1482 APSB_sw204_frRightMiddle 1;
BA_ "Confidence" SG_ 1482 APSB_sw204_maxSpeed 1;
BA_ "Confidence" SG_ 1482 APSB_sw205_oocDistance 1;
BA_ "Confidence" SG_ 1482 APSB_sw205_rrLeft 1;
BA_ "Confidence" SG_ 1482 APSB_sw205_rrLeftMiddle 1;
BA_ "Confidence" SG_ 1482 APSB_sw205_rrMiddle 1;
BA_ "Confidence" SG_ 1482 APSB_sw205_rrRight 1;
BA_ "Confidence" SG_ 1482 APSB_sw205_rrRightMiddle 1;
BA_ "Confidence" SG_ 1482 APSB_sw235_resetOrigin 1;
BA_ "SystemSignalLongSymbol" SG_ 1482 APSB_sw235_unrecoverableFailRese "APSB_sw235_unrecoverableFailReset";
BA_ "SystemSignalLongSymbol" SG_ 1482 APSB_sw235_canUncorrectedBitErro "APSB_sw235_canUncorrectedBitError";
BA_ "SystemSignalLongSymbol" SG_ 1482 APSB_sw235_pmicApOffWaitUnrcvrbl "APSB_sw235_pmicApOffWaitUnrcvrble";
BA_ "Confidence" SG_ 1482 APSB_sw237_faultSource 1;
BA_ "SystemSignalLongSymbol" SG_ 1482 APSB_sw241_unknownVendorOnNonRes "APSB_sw241_unknownVendorOnNonResume";
BA_ "SystemSignalLongSymbol" SG_ 1482 APSB_sw241_phyReinitFailedOnResu "APSB_sw241_phyReinitFailedOnResume";
BA_ "SystemSignalLongSymbol" SG_ 1482 APSB_sw241_phyReinitFailedOnNonR "APSB_sw241_phyReinitFailedOnNonResume";
BA_ "SystemSignalLongSymbol" SG_ 1482 APSB_sw241_dfiInitCompleteTimeou "APSB_sw241_dfiInitCompleteTimeout";
BA_ "SystemSignalLongSymbol" SG_ 1482 APSB_sw241_phy0TimeoutWaitingFor "APSB_sw241_phy0TimeoutWaitingForInterrupts";
BA_ "SystemSignalLongSymbol" SG_ 1482 APSB_sw241_phy0Ch0ReadGateOffset "APSB_sw241_phy0Ch0ReadGateOffsetBug";
BA_ "SystemSignalLongSymbol" SG_ 1482 APSB_sw241_phy0Ch1ReadGateOffset "APSB_sw241_phy0Ch1ReadGateOffsetBug";
BA_ "SystemSignalLongSymbol" SG_ 1482 APSB_sw241_phy0RdlvlReinitTraini "APSB_sw241_phy0RdlvlReinitTrainingTimeout";
BA_ "SystemSignalLongSymbol" SG_ 1482 APSB_sw241_phy0WdqlvlReinitTrain "APSB_sw241_phy0WdqlvlReinitTrainingTimeout";
BA_ "SystemSignalLongSymbol" SG_ 1482 APSB_sw241_phy0WdqlvlPhaseMargin "APSB_sw241_phy0WdqlvlPhaseMarginOutOfRange";
BA_ "SystemSignalLongSymbol" SG_ 1482 APSB_sw241_phy0WdqlvlReinitFaile "APSB_sw241_phy0WdqlvlReinitFailed";
BA_ "SystemSignalLongSymbol" SG_ 1482 APSB_sw241_phy1TimeoutWaitingFor "APSB_sw241_phy1TimeoutWaitingForInterrupts";
BA_ "SystemSignalLongSymbol" SG_ 1482 APSB_sw241_phy1Ch0ReadGateOffset "APSB_sw241_phy1Ch0ReadGateOffsetBug";
BA_ "SystemSignalLongSymbol" SG_ 1482 APSB_sw241_phy1Ch1ReadGateOffset "APSB_sw241_phy1Ch1ReadGateOffsetBug";
BA_ "SystemSignalLongSymbol" SG_ 1482 APSB_sw241_phy1RdlvlReinitTraini "APSB_sw241_phy1RdlvlReinitTrainingTimeout";
BA_ "SystemSignalLongSymbol" SG_ 1482 APSB_sw241_phy1WdqlvlReinitTrain "APSB_sw241_phy1WdqlvlReinitTrainingTimeout";
BA_ "SystemSignalLongSymbol" SG_ 1482 APSB_sw241_phy1WdqlvlPhaseMargin "APSB_sw241_phy1WdqlvlPhaseMarginOutOfRange";
BA_ "SystemSignalLongSymbol" SG_ 1482 APSB_sw241_phy1WdqlvlReinitFaile "APSB_sw241_phy1WdqlvlReinitFailed";
BA_ "SystemSignalLongSymbol" SG_ 1482 APSB_sw241_phy2TimeoutWaitingFor "APSB_sw241_phy2TimeoutWaitingForInterrupts";
BA_ "SystemSignalLongSymbol" SG_ 1482 APSB_sw241_phy2Ch0ReadGateOffset "APSB_sw241_phy2Ch0ReadGateOffsetBug";
BA_ "SystemSignalLongSymbol" SG_ 1482 APSB_sw241_phy2Ch1ReadGateOffset "APSB_sw241_phy2Ch1ReadGateOffsetBug";
BA_ "SystemSignalLongSymbol" SG_ 1482 APSB_sw241_phy2RdlvlReinitTraini "APSB_sw241_phy2RdlvlReinitTrainingTimeout";
BA_ "SystemSignalLongSymbol" SG_ 1482 APSB_sw241_phy2WdqlvlReinitTrain "APSB_sw241_phy2WdqlvlReinitTrainingTimeout";
BA_ "SystemSignalLongSymbol" SG_ 1482 APSB_sw241_phy2WdqlvlPhaseMargin "APSB_sw241_phy2WdqlvlPhaseMarginOutOfRange";
BA_ "SystemSignalLongSymbol" SG_ 1482 APSB_sw241_phy2WdqlvlReinitFaile "APSB_sw241_phy2WdqlvlReinitFailed";
BA_ "SystemSignalLongSymbol" SG_ 1482 APSB_sw241_phy3TimeoutWaitingFor "APSB_sw241_phy3TimeoutWaitingForInterrupts";
BA_ "SystemSignalLongSymbol" SG_ 1482 APSB_sw241_phy3Ch0ReadGateOffset "APSB_sw241_phy3Ch0ReadGateOffsetBug";
BA_ "SystemSignalLongSymbol" SG_ 1482 APSB_sw241_phy3Ch1ReadGateOffset "APSB_sw241_phy3Ch1ReadGateOffsetBug";
BA_ "SystemSignalLongSymbol" SG_ 1482 APSB_sw241_phy3RdlvlReinitTraini "APSB_sw241_phy3RdlvlReinitTrainingTimeout";
BA_ "SystemSignalLongSymbol" SG_ 1482 APSB_sw241_phy3WdqlvlReinitTrain "APSB_sw241_phy3WdqlvlReinitTrainingTimeout";
BA_ "SystemSignalLongSymbol" SG_ 1482 APSB_sw241_phy3WdqlvlPhaseMargin "APSB_sw241_phy3WdqlvlPhaseMarginOutOfRange";
BA_ "SystemSignalLongSymbol" SG_ 1482 APSB_sw241_phy3WdqlvlReinitFaile "APSB_sw241_phy3WdqlvlReinitFailed";
BA_ "SystemSignalLongSymbol" SG_ 1482 APSB_sw242_clusterSRAMMBISTFaile "APSB_sw242_clusterSRAMMBISTFailed";
BA_ "Confidence" SG_ 1482 APSB_sw243_errorStatus 1;
BA_ "Confidence" SG_ 1482 APSB_sw249_ufsInitFailureReason 1;
BA_ "SystemSignalLongSymbol" SG_ 1482 APSB_sw253_apWaitForShutdownTime "APSB_sw253_apWaitForShutdownTimeout";
BA_ "SystemSignalLongSymbol" SG_ 1482 APSB_sw254_waitForBusSilenceTime "APSB_sw254_waitForBusSilenceTimeout";
BA_ "SystemSignalLongSymbol" SG_ 1482 APSB_sw255_adcWrapperInitBootErr "APSB_sw255_adcWrapperInitBootError";
BA_ "SystemSignalLongSymbol" SG_ 1482 APSB_sw255_boardRevisionInitBoot "APSB_sw255_boardRevisionInitBootError";
BA_ "SystemSignalLongSymbol" SG_ 1482 APSB_sw255_provisionInitBootErro "APSB_sw255_provisionInitBootError";
BA_ "SystemSignalLongSymbol" SG_ 1482 APSB_sw255_vrmInitConfigBootErro "APSB_sw255_vrmInitConfigBootError";
BA_ "SystemSignalLongSymbol" SG_ 1482 APSB_sw255_dfuCheckinSubsystemBo "APSB_sw255_dfuCheckinSubsystemBootError";
BA_ "SystemSignalLongSymbol" SG_ 1482 APSB_sw255_sectorProtectionBootE "APSB_sw255_sectorProtectionBootError";
BA_ "SystemSignalLongSymbol" SG_ 1482 APSB_sw260_pgoodDdr0V75VrmRailFa "APSB_sw260_pgoodDdr0V75VrmRailFail";
BA_ "SystemSignalLongSymbol" SG_ 1482 APSB_sw260_pgoodDdr1V25VrmRailFa "APSB_sw260_pgoodDdr1V25VrmRailFail";
BA_ "Confidence" SG_ 1482 APSB_sw261_vrmType 1;
BA_ "Confidence" SG_ 1482 APSB_sw262_vrmType 1;
BA_ "Confidence" SG_ 1482 APSB_sw263_vrmType 1;
BA_ "Confidence" SG_ 1482 APSB_sw279_corruptDirectorySourc 1;
BA_ "SystemSignalLongSymbol" SG_ 1482 APSB_sw279_corruptDirectorySourc "APSB_sw279_corruptDirectorySource";
BA_ "Confidence" SG_ 1482 APSB_sw289_turboTemperature 1;
BA_ "GenSigSNA" SG_ 1482 APSB_sw289_turboTemperature "128";
BA_ "Confidence" SG_ 1482 APSB_sw289_peer_turboTemperature 1;
BA_ "GenSigSNA" SG_ 1482 APSB_sw289_peer_turboTemperature "128";
BA_ "Confidence" SG_ 731 APSB_eacAllow 0;
BA_ "GenSigSNA" SG_ 731 APSB_eacAllow "3";
BA_ "Confidence" SG_ 731 APSB_eacMonitorCounter 0;
BA_ "Confidence" SG_ 731 APSB_eacMonitorChecksum 0;
BA_ "Confidence" SG_ 992 APSB_A_lowPowerRequest 0;
BA_ "Confidence" SG_ 992 APSB_A_lowPowerRequestor 0;
BA_ "Confidence" SG_ 992 APSB_A_forcePowerOffRequest 0;
BA_ "Confidence" SG_ 992 APSB_B_lowPowerRequest 0;
BA_ "Confidence" SG_ 992 APSB_B_lowPowerRequestor 0;
BA_ "Confidence" SG_ 992 APSB_B_forcePowerOffRequest 0;
BA_ "Confidence" SG_ 1864 APSB_primaryTurbo 0;
BA_ "Confidence" SG_ 1864 APSB_A_arbState 0;
BA_ "Confidence" SG_ 1864 APSB_A_powerState 0;
BA_ "Confidence" SG_ 1864 APSB_A_sleepState 0;
BA_ "Confidence" SG_ 1864 APSB_A_resetState 0;
BA_ "Confidence" SG_ 1864 APSB_A_faultState 0;
BA_ "Confidence" SG_ 1864 APSB_secondaryTurbo 0;
BA_ "Confidence" SG_ 1864 APSB_B_arbState 0;
BA_ "Confidence" SG_ 1864 APSB_B_powerState 0;
BA_ "Confidence" SG_ 1864 APSB_B_sleepState 0;
BA_ "Confidence" SG_ 1864 APSB_B_resetState 0;
BA_ "Confidence" SG_ 1864 APSB_B_faultState 0;
BA_ "Confidence" SG_ 1864 APSB_A_autosteerMonitorState 0;
BA_ "Confidence" SG_ 1864 APSB_B_autosteerMonitorState 0;
BA_ "Confidence" SG_ 1864 APSB_eplannerState 0;
BA_ "Confidence" SG_ 1864 APSB_A_faultInduced 0;
BA_ "Confidence" SG_ 1864 APSB_B_faultInduced 0;
BA_ "Confidence" SG_ 1864 APSB_stateCounter 0;
BA_ "Confidence" SG_ 971 APSB_appStatusMonitorState 0;
BA_ "Confidence" SG_ 971 APSB_vehBehaviorState 0;
BA_ "Confidence" SG_ 971 APSB_canMaster 0;
BA_ "GenSigSNA" SG_ 971 APSB_canMaster "3";
BA_ "Confidence" SG_ 971 APSB_appGpioState 0;
BA_ "Confidence" SG_ 971 APSB_eacInternalState 0;
BA_ "Confidence" SG_ 971 APSB_switchState 0;
BA_ "Confidence" SG_ 971 APSB_apbStatusMonitorState 0;
BA_ "Confidence" SG_ 971 APSB_apbGpioState 0;
BA_ "Confidence" SG_ 971 APSB_statusCounter 0;
BA_ "Confidence" SG_ 971 APSB_locLimitReason 0;
BA_ "Confidence" SG_ 971 APSB_appPowerStateRequest 0;
BA_ "Confidence" SG_ 971 APSB_appPowerStateReason 0;
BA_ "Confidence" SG_ 971 APSB_apbPowerStateRequest 0;
BA_ "Confidence" SG_ 971 APSB_apbPowerStateReason 0;
BA_ "Confidence" SG_ 971 APSB_heaterStateDebug 0;
BA_ "GenSigSNA" SG_ 971 APSB_heaterStateDebug "7";
BA_ "Confidence" SG_ 971 APSB_autosummonCounter 0;
BA_ "Confidence" SG_ 971 APSB_autosummonAlert 0;
BA_ "Confidence" SG_ 971 APSB_gpsAntennaState 0;
BA_ "Confidence" SG_ 971 APSB_arbState 0;
BA_ "Confidence" SG_ 971 APSB_socPowerOperatingMode 0;
BA_ "SystemSignalLongSymbol" SG_ 845 APSB_w040_autopilotAngleSaturate "APSB_w040_autopilotAngleSaturated";
BA_ "SystemSignalLongSymbol" SG_ 1143 APSB_w065_deserializerOvercurren "APSB_w065_deserializerOvercurrent";
BA_ "SystemSignalLongSymbol" SG_ 976 APSB_w215_contDriverNotIntractin "APSB_w215_contDriverNotIntracting";
BA_ "SystemSignalLongSymbol" SG_ 976 APSB_w245_eloopRxFromUnexpectedS "APSB_w245_eloopRxFromUnexpectedSourceMAC";
BA_ "SystemSignalLongSymbol" SG_ 976 APSB_w246_ethloopSwitchPortLinkD "APSB_w246_ethloopSwitchPortLinkDown";
BA_ "SystemSignalLongSymbol" SG_ 976 APSB_w250_ethloopSwitchMemUsageT "APSB_w250_ethloopSwitchMemUsageTooHighPort2";
BA_ "SystemSignalLongSymbol" SG_ 976 APSB_w251_ethloopSwitchMemUsageT "APSB_w251_ethloopSwitchMemUsageTooHighPort3";
BA_ "SystemSignalLongSymbol" SG_ 1003 APSB_w258_qspiFlashSectorChecksu "APSB_w258_qspiFlashSectorChecksumMismatch";
BA_ "SystemSignalLongSymbol" SG_ 1003 APSB_w269_ethSwitchRxPageCountTo "APSB_w269_ethSwitchRxPageCountTooHighPort0_3";
BA_ "SystemSignalLongSymbol" SG_ 1003 APSB_w270_ethSwitchRxPageCountTo "APSB_w270_ethSwitchRxPageCountTooHighPort4_7";
BA_ "SystemSignalLongSymbol" SG_ 1003 APSB_w284_cam12VBuckBoostAPwrIss "APSB_w284_cam12VBuckBoostAPwrIssue";
BA_ "SystemSignalLongSymbol" SG_ 1003 APSB_w285_cam12VBuckBoostBPwrIss "APSB_w285_cam12VBuckBoostBPwrIssue";
BA_ "SystemSignalLongSymbol" SG_ 1003 APSB_w286_cam12VEFuseAPrimaryIss "APSB_w286_cam12VEFuseAPrimaryIssue";
BA_ "SystemSignalLongSymbol" SG_ 1003 APSB_w287_cam12VEFuseASecondaryI "APSB_w287_cam12VEFuseASecondaryIssue";
BA_ "SystemSignalLongSymbol" SG_ 1003 APSB_w289_turboTemperatureWarnin "APSB_w289_turboTemperatureWarning";
BA_ "SystemSignalLongSymbol" SG_ 1003 APSB_w290_cam12VBuckBoostBPwrRin "APSB_w290_cam12VBuckBoostBPwrRinging";
BA_ "SystemSignalLongSymbol" SG_ 1003 APSB_w296_wdogMonTaskDeadlineMis "APSB_w296_wdogMonTaskDeadlineMiss";
BA_ "SystemSignalLongSymbol" SG_ 1003 APSB_w298_cpuToApCanSharedMemErr "APSB_w298_cpuToApCanSharedMemError";
BA_ "SystemSignalLongSymbol" SG_ 1003 APSB_w299_apToCpuCanSharedMemErr "APSB_w299_apToCpuCanSharedMemError";
BA_ "SystemSignalLongSymbol" SG_ 1003 APSB_w300_sharedMemoryAccessErro "APSB_w300_sharedMemoryAccessError";
BA_ "SystemSignalLongSymbol" SG_ 1003 APSB_w318_ethernetNetworkBufferH "APSB_w318_ethernetNetworkBufferHighWatermark";
BA_ "SystemSignalLongSymbol" SG_ 1003 APSB_w320_eplannerPreconditionsM "APSB_w320_eplannerPreconditionsMet";
VAL_ 1482 APSB_alertID 320 "w320_eplannerPreconditionsMet" 319 "w319_vehDasImposterDetected" 318 "w318_ethernetNetworkBufferHighWatermark" 317 "w317_uiMia" 316 "w316_apBootHealth" 315 "w315_epas3pMiaBdyBus" 313 "w313_BDY_busOff" 312 "w312_apbdgApMia" 311 "w311_apbdgDasMia" 310 "w310_wakeBootMetrics" 309 "w309_ethBridgeDown" 308 "w308_pmicErrorDetected" 307 "w307_eccEventDetected" 306 "w306_ethPgoodFailure" 305 "w305_gpsPgoodFailure" 304 "w304_dataAbort" 303 "w303_canAPShmFifoEmpty" 302 "w302_canAPShmFifoFull" 301 "w301_nocTimeoutDetected" 300 "w300_sharedMemoryAccessError" 299 "w299_apToCpuCanSharedMemError" 298 "w298_cpuToApCanSharedMemError" 297 "w297_earlyWDogAlert" 296 "w296_wdogMonTaskDeadlineMiss" 295 "w295_PT_busOff" 294 "w294_VEH_busOff" 293 "w293_PARTY_busOff" 292 "w292_CH_busOff" 291 "w291_eplannerError" 290 "w290_cam12VBuckBoostBPwrRinging" 289 "w289_turboTemperatureWarning" 288 "w288_brakeboosterMia" 287 "w287_cam12VEFuseASecondaryIssue" 286 "w286_cam12VEFuseAPrimaryIssue" 285 "w285_cam12VBuckBoostBPwrIssue" 284 "w284_cam12VBuckBoostAPwrIssue" 283 "w283_psfaMia" 282 "w282_smmuError" 281 "w281_rsaMia" 280 "w280_pepsMia" 279 "w279_ufsPartitionError" 278 "w278_ddrScheduler7EccErrors" 277 "w277_ddrScheduler6EccErrors" 276 "w276_ddrScheduler5EccErrors" 275 "w275_ddrScheduler4EccErrors" 274 "w274_ddrScheduler3EccErrors" 273 "w273_ddrScheduler2EccErrors" 272 "w272_ddrScheduler1EccErrors" 271 "w271_ddrScheduler0EccErrors" 270 "w270_ethSwitchRxPageCountTooHighPort4_7" 269 "w269_ethSwitchRxPageCountTooHighPort0_3" 268 "w268_ddrControllerFailures" 267 "w267_ddrPhy3Failures" 266 "w266_ddrPhy2Failures" 265 "w265_ddrPhy1Failures" 264 "w264_ddrPhy0Failures" 263 "w263_vrmFaultGrpC" 262 "w262_vrmFaultGrpB" 261 "w261_vrmFaultGrpA" 260 "w260_pgoodFailure" 259 "w259_qspiFailure" 258 "w258_qspiFlashSectorChecksumMismatch" 257 "w257_assertFailure" 255 "w255_bootHealth" 254 "w254_sleepStateTimeout" 253 "w253_powerStateTimeout" 252 "w252_ethSwitchPortLinkDown" 251 "w251_ethloopSwitchMemUsageTooHighPort3" 250 "w250_ethloopSwitchMemUsageTooHighPort2" 249 "w249_ufsFailures" 248 "w248_ethloopSwitchPoorSqi" 247 "w247_ethernetFrameError" 246 "w246_ethloopSwitchPortLinkDown" 245 "w245_eloopRxFromUnexpectedSourceMAC" 244 "w244_gpuHWFaultStatus" 243 "w243_tripHWErrorStatus" 242 "w242_tripMBISTFailure" 241 "w241_ddrInitFailures" 238 "w238_resetReason" 237 "w237_faultMgrEventDetected" 236 "w236_canSharedMemError" 235 "w235_a72LoopDetected" 232 "w232_laneChangeRequested" 231 "w231_idfEvent" 230 "w230_alcUltrasoundBlocked" 229 "w229_alcUltrasoundDamaged" 228 "w228_DEPRECATED" 227 "w227_virtualWallBlocked" 226 "w226_lcCamCalNeededSpeedLmt" 225 "w225_lcDegradedVisSpeedLmt" 224 "w224_accCameraCalibration" 223 "w223_accObjectInPath" 222 "w222_accCameraBlind" 221 "w221_accRadarBlind" 220 "w220_lcTempUnavailableRoad" 219 "w219_lcTempUnavailableSpeed" 218 "w218_lcSpeedExceededLimit" 217 "w217_lcUnavailableSpeeding" 216 "w216_driverOverriding" 215 "w215_contDriverNotIntracting" 214 "w214_driverNotIntracting" 213 "w213_autosteerStruckOut" 212 "w212_lcUnavailableStrikeOut" 211 "w211_accNoSeatBelt" 210 "w210_camObstrcted" 209 "w209_autoSummonRequest" 208 "w208_rackDetected" 207 "w207_autosteerUnavailable" 206 "w206_autosteerNotEnabled" 205 "w205_apcFinalRear" 204 "w204_apcFinalFront" 203 "w203_apcActivation" 202 "w202_scwNoisyEnvironment" 201 "w201_lcAborting" 200 "w200_lcSlowdown" 199 "w199_apcAbort" 198 "w198_tsrUnavailable" 197 "w197_redLightWarning" 196 "w196_stopSignWarning" 195 "w195_scwUnavailable" 194 "w194_accDriverResumeRqrd" 193 "w193_camWindshieldUnclean" 192 "w192_CANFault" 191 "w191_timesyncError" 190 "w190_iboosterMia" 189 "w189_vcfrontMiaPartyBus" 188 "w188_otherTurboUartMIA" 187 "w187_TurboB_SMS_taskUtilErr" 186 "w186_TurboB_A72_watchdog" 185 "w185_TurboB_SCS_LKUP" 184 "w184_TurboB_SMS_WDOG" 183 "w183_TurboB_TMU_Throttle" 182 "w182_TurboB_SMSLockStepErr" 181 "w181_TurboB_Temp_NOS" 180 "w180_TurboB_12VFuseFault" 179 "w179_TurboB_DisRegNFault" 178 "w178_TurboB_DisRegPgoodErr" 172 "w172_apFeaturesUnavailable" 171 "w171_TurboA_SMS_taskUtilErr" 170 "w170_TurboA_A72_watchdog" 169 "w169_TurboA_SCS_LKUP" 168 "w168_TurboA_SMS_WDOG" 167 "w167_TurboA_TMU_Throttle" 166 "w166_TurboA_SMSLockStepErr" 165 "w165_TurboA_Temp_NOS" 164 "w164_TurboA_12VFuseFault" 163 "w163_TurboA_DisRegNFault" 162 "w162_TurboA_DisRegPgoodErr" 161 "w161_gpsAntennaDisconnected" 160 "w160_apbVersionMismatch" 159 "w159_apbCritical" 158 "w158_apbMia" 157 "w157_autopilotReboot" 156 "w156_lwipAssert" 155 "w155_ethLwipError" 153 "w153_eacInhibit" 152 "w152_gpsFusionStatus" 151 "w151_apRecovered" 150 "w150_sccmMiaVehBus" 149 "w149_epblMiaVehBus" 148 "w148_vcrightMiaVehBus" 147 "w147_vcleftMiaVehBus" 146 "w146_epas3pMiaPartyBus" 145 "w145_vcrightMiaPartyBus" 144 "w144_vcleftMiaPartyBus" 143 "w143_espMiaPartyBus" 142 "w142_diMiaPartyBus" 141 "w141_rcmMiaPartyBus" 140 "w140_vcfrontMiaVehicleBus" 139 "w139_udpBufferOverflow" 138 "w138_gpsComIssue" 137 "w137_gpsFaultReset" 136 "w136_gpsDisabled" 135 "w135_appCritical" 134 "w134_appMia" 133 "w133_ETHSwitchError" 132 "w132_appVersionMismatch" 131 "w131_trap_exception" 130 "w130_ECU_Thermal_Issue" 129 "w129_ECU_Power_Issue" 106 "w106_torsionBarOffset" 105 "w105_DEPRECATED" 104 "w104_DEPRECATED" 103 "w103_robExperimentalAEB" 102 "w102_DEPRECATED" 101 "w101_DEPRECATED" 100 "w100_DEPRECATED" 99 "w099_DEPRECATED" 98 "w098_DEPRECATED" 97 "w097_DEPRECATED" 96 "w096_DEPRECATED" 95 "w095_DEPRECATED" 94 "w094_DEPRECATED" 93 "w093_DEPRECATED" 92 "w092_DEPRECATED" 91 "w091_DEPRECATED" 90 "w090_DEPRECATED" 89 "w089_DEPRECATED" 88 "w088_DEPRECATED" 87 "w087_DEPRECATED" 86 "w086_robCollision" 85 "w085_pmmSteering" 84 "w084_pmmIPSO" 83 "w083_inPathRADObject" 82 "w082_inPathFSviolation" 81 "w081_pmmActiveBraking" 80 "w080_accFailedActivation" 79 "w079_edrAvailable" 78 "w078_pmmActive2" 77 "w077_pmmActive" 76 "w076_mobilEyeSetC" 75 "w075_scMia" 74 "w074_inPathStationaryObst" 73 "w073_issueEscalatedLDW" 72 "w072_selfparkComplete" 71 "w071_selfparkStarted" 70 "w070_apcIncompleteCal" 69 "w069_apcSpaceMasked" 68 "w068_vlInconsistency" 67 "w067_steeringAlignment" 66 "w066_deserializerLockLost" 65 "w065_deserializerOvercurrent" 64 "w064_epasMia" 63 "w063_parkVersionMismatch" 62 "w062_radcAlignment" 61 "w061_tasMia" 60 "w060_fcw_event" 59 "w059_parkMia" 58 "w058_epbMia" 57 "w057_mcuMia" 56 "w056_diMia" 55 "w055_radcVersionMismatch" 54 "w054_camAutofix" 53 "w053_radcCommIssue" 52 "w052_radcSensorIssue" 51 "w051_radcEcuIssue" 50 "w050_aeb_event" 49 "w049_eyeqVersionMismatch" 48 "w048_DAS_Features_Disabled" 47 "w047_edrEvent" 46 "w046_eepromRecordAbsent" 45 "w045_radMia" 44 "w044_appMobileyeFailure" 43 "w043_camLongRunTime" 42 "w042_autopilotAborting" 41 "w041_autopilotRateSaturated" 40 "w040_autopilotAngleSaturated" 39 "w039_sdm_rcm_Mia" 38 "w038_camFailure" 37 "w037_camTacIssue" 36 "w036_bdyMia" 35 "w035_espMia" 34 "w034_sccmMia" 33 "w033_gtwMia" 32 "w032_canTxError" 31 "w031_canRxError" 30 "w030_Heater_Issue" 29 "w029_spi_tx_error" 28 "w028_spi_rx_error" 27 "w027_ECU_Reset_Fault" 26 "w026_ECU_timingIssue" 25 "w025_LC_Steering_Override" 24 "w024_ECU_Watchdog_Reset" 23 "w023_ECU_Cam_Statemismatc" 22 "w022_ECU_EEPROM_Failure" 21 "w021_ECU_Temperature_Issue" 20 "w020_ECU_checkstopError" 19 "w019_ECU_Stack_Overflow" 18 "w018_ECU_Power_Issue" 17 "w017_Cam_Msg_MIA" 16 "w016_aeb_e_event" 15 "w015_Camera_Failsafes" 14 "w014_swAssert" 13 "w013_Cam_Watchdog" 12 "w012_Cam_BootFailure" 11 "w011_scaEvent" 10 "w010_radcCalibIssue" 9 "w009_aebFault" 8 "w008_parkDisabled" 7 "w007_ahlbDisabled" 6 "w006_aebCancelled" 5 "w005_fcwCancelled" 4 "w004_accDisabled" 3 "w003_isaDisabled" 2 "w002_ldwDisabled" 1 "w001_DEPRECATED" 0 "ALERT_DO_NOT_USE_ZERO" ;
VAL_ 1482 APSB_alertSource 1 "TURBOB" 0 "TURBOA" ;
VAL_ 1482 APSB_alertState 1 "SET" 0 "CLEARED" ;
VAL_ 1482 APSB_sw019_taskId 32 "MAX_TASK_ID" 31 "TASKS_ISOTERM_A72" 30 "TASKS_ISOTERM_SMS" 29 "TASKS_APP_1HZ" 28 "TASKS_APP_1KHZ" 27 "TASKS_SMS_SERIAL" 26 "TASKS_CAN_AP_RX" 25 "TASKS_CAN_AP_TX" 24 "TASKS_TMU" 23 "TASKS_WDG_TASK" 22 "TASKS_MBX_RELAY" 21 "TASKS_MBX_SCS_RX_HIGH" 20 "TASKS_MBX_SCS_RX_LOW" 19 "TASKS_MBX_SCS_TX_HIGH" 18 "TASKS_MBX_SCS_TX_LOW" 17 "TASKS_MBX_AP_RX_HIGH" 16 "TASKS_MBX_AP_RX_LOW" 15 "TASKS_MBX_AP_TX_HIGH" 14 "TASKS_MBX_AP_TX_LOW" 13 "TASKS_VEH_CAN" 12 "TASKS_RADAR_CAN" 11 "TASKS_CH_CAN" 10 "TASKS_PARTY_CAN" 9 "TASK_DEBUG_SMS_SERIAL_RX" 8 "TASK_DEBUG_SERIAL_TX" 7 "TASKS_SMS_SMS_UART_RX" 6 "TASKS_SMS_SMS_UART_TX" 5 "TASKS_VEHICLE" 4 "TASKS_MOBILEYE" 3 "TASKS_UDS" 2 "TASKS_CAN" 1 "TASKS_INIT" 0 "TASKS_RESERVED" ;
VAL_ 1482 APSB_sw129_railID 17 "C_RAIL" 16 "SENSOR3_TEMP" 15 "SENSOR2_TEMP" 14 "SENSOR1_TEMP" 13 "SENSOR0_TEMP" 12 "GPS_ANT_DET" 11 "PARK_THERM_ALERT_MON" 10 "PARK_SYS_RST_ARX_MON" 9 "VDD_FAN" 8 "1V1_ETH" 7 "1V5_ETH" 6 "1V3_ARX" 5 "1V8_ARX" 4 "5V0_ARX" 3 "5V0_MAIN4" 2 "5V0_MAIN3" 1 "5V0_MAIN2" 0 "5V0_MAIN1" ;
VAL_ 1482 APSB_sw132_mismatchType 1 "GTW_APP_FW_REPO_GITHASH" 0 "APS_APP_FW_REPO_GITHASH" ;
VAL_ 1482 APSB_sw135_appCriticalReason 8 "OTHER_TURBO_TIMESYNC_ERROR" 7 "TIMESYNC_ERROR" 6 "OTHER_TURBO_VERSION_MISMATCH" 5 "WATCHDOG_CRITICAL" 4 "MIA" 3 "VERSION_MISMATCH" 2 "GPIO_CRITICAL" 1 "BOOT_TIMEOUT" 0 "UNKNOWN" ;
VAL_ 1482 APSB_sw153_eacInhibitReason 9 "RSA_MIA" 8 "PEPS_MIA" 7 "LSS_DURATION" 6 "DI_MIA" 5 "DAS_MIA" 4 "EPAS_MIA" 3 "HYSTERESIS" 2 "DURATION" 1 "EPAS" 0 "NONE" ;
VAL_ 1482 APSB_sw153_eacInternalState 7 "NUM_STATES" 6 "STATE_LSS" 5 "STATE_OVERRIDE" 4 "STATE_INHIBIT" 3 "STATE_AUTOPARK" 2 "STATE_CONTINUOUS" 1 "STATE_MOMENTARY" 0 "STATE_INIT" ;
VAL_ 1482 APSB_sw159_apbCriticalReason 8 "OTHER_TURBO_TIMESYNC_ERROR" 7 "TIMESYNC_ERROR" 6 "OTHER_TURBO_VERSION_MISMATCH" 5 "WATCHDOG_CRITICAL" 4 "MIA" 3 "VERSION_MISMATCH" 2 "GPIO_CRITICAL" 1 "BOOT_TIMEOUT" 0 "UNKNOWN" ;
VAL_ 1482 APSB_sw160_mismatchType 1 "GTW_APP_FW_REPO_GITHASH" 0 "APS_APP_FW_REPO_GITHASH" ;
VAL_ 1482 APSB_sw188_otherTurbo 2 "UNKNOWN" 1 "B" 0 "A" ;
VAL_ 1482 APSB_sw192_CANbus 4 "UNKNOWN" 3 "VEH" 2 "RAD0" 1 "CH" 0 "PARTY" ;
VAL_ 1482 APSB_sw192_msgIo 2 "TX" 1 "RX" 0 "NO_MESSAGE" ;
VAL_ 1482 APSB_sw192_queueFailure 2 "HW" 1 "SW" 0 "NO_FAILURE" ;
VAL_ 1482 APSB_sw199_abortCodeDas 47 "CLOSURE_OPEN" 46 "COLLISION_RISK" 45 "CONTROLLER_HEALTH" 44 "PLANNER_HEALTH" 43 "SPEED_TOO_HIGH" 42 "SEATBELT_UNBUCKLED" 41 "GEAR_SHIFT_TIMEOUT" 40 "CONTROL_INTEGRATOR" 39 "GRADE_TOO_HIGH" 38 "UI_DISPLAY_NOT_OK" 37 "EXTENDED_COMPUTE_NOT_ACTIVE" 36 "REQUIRED_CAMERA_NOT_READY" 35 "FORWARD_CAMERAS_BLINDED" 34 "REPEATER_CAMERA_BLINDED" 33 "BACKUP_CAMERA_BLINDED" 32 "EXTERIOR_LIGHTS_OFF" 31 "DRIVER_NOT_DETECTED" 30 "UNAUTHORIZED_REQUEST" 29 "DRIVABLE_SPACE_STALE" 28 "TOO_MANY_GEAR_CHANGES" 27 "TRAILER_MODE" 26 "PARKER_HEARTBEAT_MISSING" 25 "HEARTBEAT_MISSING" 24 "APP_MIA" 23 "PAUSE_CYCLES" 22 "EPAS_INHIBITED" 21 "USER_KEYFOB" 20 "SC_MIA" 19 "SENSOR_FAILURE" 18 "PRECRUISE_TIMEOUT" 17 "UI_REQUEST" 16 "LOST_DI_CONTROL" 15 "PARK_GEAR" 14 "RESTART_TIMEOUT" 13 "PAUSE_USER_TIMEOUT" 12 "PAUSE_OBSTACLE_TIMEOUT" 11 "ESP_MIA" 10 "SCCM_MIA" 9 "MCU_MIA" 8 "DI_MIA" 7 "EPAS_MIA" 6 "PARK_MIA" 5 "PREGUIDANCE_TIMEOUT" 4 "INVALID_SPACE" 3 "MCU_REQUEST_MISMATCH" 2 "PARK_GUIDANCE_ENDED" 1 "LOST_ANGLE_CONTROL" 0 "NONE" ;
VAL_ 1482 APSB_sw199_abortCodePARK 31 "SNA" 25 "PSC_MOVEMENT_AT_ACTIVATION" 24 "PSC_MAX_WAY_BEHIND_HINT" 23 "PSC_PARK_STC_FAILED" 22 "PSC_PARK_PONR_NOT_REACHED" 21 "PSC_VCTL_GENERAL_ABORT" 20 "PSC_HIGH_TORQUE" 19 "PSC_ASYNC_CTRL_SYSTEM" 18 "ERROR" 17 "SYSTEM_SERVICE" 16 "SYSTEM_FAULT" 15 "ECU_INTERNAL_FAULT" 14 "DAS_ABORT" 13 "EPAS_FAULT" 12 "VEHICLE_DYNAMICS_INTERVENTION" 11 "HANDS_ON_DETECTED" 10 "FULL_WARNING_ON_BOTH_SIDES" 9 "PARK_SPACE_TOO_SMALL" 8 "OBSTACLE_ON_PATH" 7 "MAX_YAW_ANGLE_REACHED" 6 "MAX_SWA_DEV_EXCEEDED" 5 "OFF_TRACK" 4 "UNCONTROLLED_TRAVEL_DIST_REACHED" 3 "NO_VALID_PATH" 2 "MAX_NUM_OF_MOVES" 1 "VELOCITY_TOO_HIGH" 0 "NONE" ;
VAL_ 1482 APSB_sw203_controlType 15 "SNA" 14 "SUMMON" 10 "PAUSE" 9 "SEARCH" 8 "COMPLETE" 7 "ABORT" 6 "PARALLEL_PULL_OUT_TO_RIGHT" 5 "PARALLEL_PULL_OUT_TO_LEFT" 4 "PARK_RIGHT_CROSS" 3 "PARK_RIGHT_PARALLEL" 2 "PARK_LEFT_CROSS" 1 "PARK_LEFT_PARALLEL" 0 "NONE" ;
VAL_ 1482 APSB_sw235_resetOrigin 2 "SOFTWARE" 1 "HARDWARE" 0 "NO_RESET" ;
VAL_ 1482 APSB_sw237_faultSource 79 "PEER_TMUTHROT" 78 "PEER_SGK_NFAULT" 77 "PEER_AP_NFAULT" 76 "Veh_FAULT" 75 "CAUSE2_RECEIVED" 74 "CAUSE1_RECEIVED" 73 "NOC_ERRORLOG" 72 "SSS_WDG_RESET" 71 "SSS_SW_RESET" 70 "FaultManager_fm_parity" 69 "FaultManager_softfault" 68 "MemoryStack1_3_UR_int" 67 "MemoryStack0_3_UR_int" 66 "MemoryStack1_2_UR_int" 65 "MemoryStack0_2_UR_int" 64 "MemoryStack1_1_UR_int" 63 "MemoryStack0_1_UR_int" 62 "MemoryStack1_0_UR_int" 61 "MemoryStack0_0_UR_int" 60 "MemoryStack1_3_nw_UR_int" 59 "MemoryStack0_3_nw_UR_int" 58 "MemoryStack1_2_nw_UR_int" 57 "MemoryStack0_2_nw_UR_int" 56 "MemoryStack1_1_nw_UR_int" 55 "MemoryStack0_1_nw_UR_int" 54 "MemoryStack1_0_nw_UR_int" 53 "MemoryStack0_0_nw_UR_int" 52 "FAD_LSIO" 51 "NOC_LSIO_NS_BRDG_LSIO_D_T_mainTimeOut" 50 "NOC_LSIO_AHBBR_UFS_T_mainTimeOut" 49 "NOC_LSIO_AXI2APB_LSIO2_T_mainTimeOut" 48 "NOC_LSIO_AXI2APB_LSIO1_T_mainTimeOut" 47 "NOC_LSIO_AXI2APB_LSIO0_T_mainTimeOut" 46 "NOC_IMEM_NS_BRDG_IMEM_D_T_mainTimeOut" 45 "NOC_IMEM_INTMEM_IMEM_T_mainTimeOut" 44 "NOC_IMEM_AXI2APB_IMEM_T_mainTimeOut" 43 "IMEM_HPM" 42 "CORE_WDT4" 41 "CORE_WDT3" 40 "CORE_WDT2" 39 "CORE_WDT1" 38 "CORE_WDT0" 37 "VEH_FaultManager_FAULT" 36 "NOC_SOJU_AXI2APB_AON_T_mainTimeOut" 35 "TCU_AON_fmu_error_int" 34 "TMU_SGK_THERM_TRIP" 33 "IntMEM_SGK_ECC_INTR0" 32 "PUF_SGK_INT0" 31 "NOC_SGK_PD1_mainMissionInt" 30 "NOC_SGK_PD0_mainMissionInt" 29 "NOC_SGK_INT15" 28 "NOC_SGK_INT14" 27 "NOC_SGK_INT13" 26 "NOC_SGK_INT12" 25 "NOC_SGK_INT10" 24 "NOC_SGK_INT9" 23 "NOC_SGK_INT8" 22 "NOC_SGK_INT3" 21 "NOC_SGK_INT2" 20 "NOC_SGK_INT1" 19 "NOC_SGK_INT0" 18 "CR5_TOP_SGK_LOCKSTEP_FAIL" 17 "CR5_TOP_SGK_ALL_FATAL_BUS_FTLS" 16 "CR5_TOP_SGK_ALL_FATAL_EVTS" 15 "CR5_TOP_SGK_TCM_ECC_AXI_SLV_FATAL" 14 "CR5_TOP_SGK_DCACHE_TAG_ECC_FATAL" 13 "CR5_TOP_SGK_DCACHE_ECC_FATAL" 12 "CR5_TOP_SGK_TCM_ECC_LSU" 11 "CR5_TOP_SGK_TCM_ECC_PFU" 10 "SGK_SSS_FAULT" 9 "SGK_SSS_PKE_UNC" 8 "SGK_SSS_UNCORRECT" 7 "SGK_SSS_LOCKUP" 6 "SGK_ADT" 5 "SGK_GBE" 4 "SGK_HPM" 3 "SGK_DD_SLOW" 2 "SGK_DD_FAST" 1 "SGK_WDT1" 0 "SGK_WDT0" ;
VAL_ 1482 APSB_sw243_errorStatus 11 "WATCHDOG_TIMEOUT_ERROR" 10 "HW_ASSERT_ERROR" 9 "FP_UNDERFLOW_ERROR" 8 "FP_OVERFLOW_ERROR" 7 "FP_DENORM_ERROR" 6 "FP_INVALID_ERROR" 5 "AXI_SLAVE_PROTOCOL_ERROR" 4 "DMA_ACE_PROTOCOL_ERROR" 3 "DMA_CRC_ERROR" 2 "SRAM_PARITY_ERROR" 1 "BAD_COMMAND" 0 "NONE" ;
VAL_ 1482 APSB_sw249_ufsInitFailureReason 6 "TESTREADY_FAILED" 5 "FDEVICEINIT_FAILED" 4 "POWER_MODE_CHANGE_FAILED" 3 "NOP_CMD_FAILED" 2 "INIT_DESCRIPTOR_FAILED" 1 "LINK_STARTUP_CMD_FAILED" 0 "NO_ERROR" ;
VAL_ 1482 APSB_sw261_vrmType 4 "DDR_0V75_1V25_CPU_VRM" 3 "TRIP_INT_GPU_VRM" 2 "DDR_0V75_1V25_VRM" 1 "CPU_GPU_VRM" 0 "TRIP_INT_VRM" ;
VAL_ 1482 APSB_sw262_vrmType 4 "DDR_0V75_1V25_CPU_VRM" 3 "TRIP_INT_GPU_VRM" 2 "DDR_0V75_1V25_VRM" 1 "CPU_GPU_VRM" 0 "TRIP_INT_VRM" ;
VAL_ 1482 APSB_sw263_vrmType 4 "DDR_0V75_1V25_CPU_VRM" 3 "TRIP_INT_GPU_VRM" 2 "DDR_0V75_1V25_VRM" 1 "CPU_GPU_VRM" 0 "TRIP_INT_VRM" ;
VAL_ 1482 APSB_sw279_corruptDirectorySourc 6 "UNRECOGNIZED" 5 "TELEMETRY" 4 "HOME" 3 "MAP" 2 "FACTORY" 1 "AUTOPILOT" 0 "VAR" ;
VAL_ 1482 APSB_sw289_turboTemperature -128 "SNA" ;
VAL_ 1482 APSB_sw289_peer_turboTemperature -128 "SNA" ;
VAL_ 731 APSB_eacAllow 3 "APS_EAC_SNA" 2 "APS_EAC_RESERVED" 1 "APS_EAC_ALLOW" 0 "APS_EAC_INHIBIT" ;
VAL_ 992 APSB_A_lowPowerRequest 5 "APS_LOW_POWER_COLD_RESET" 4 "APS_LOW_POWER_SOC_WARM_RESET" 3 "APS_LOW_POWER_AP_WARM_RESET" 2 "APS_LOW_POWER_OFF" 1 "APS_LOW_POWER_SUSPEND" 0 "APS_LOW_POWER_NONE" ;
VAL_ 992 APSB_A_lowPowerRequestor 10 "APS_LOW_POWER_REQ_COUNT" 9 "APS_LOW_POWER_REQ_SGK_PGOOD_IRQ" 8 "APS_LOW_POWER_REQ_SGK_CONSOLE" 7 "APS_LOW_POWER_REQ_SGK_SLEEP" 6 "APS_LOW_POWER_REQ_SGK_UDS" 5 "APS_LOW_POWER_REQ_SGK_BRIDGE" 4 "APS_LOW_POWER_REQ_SGK_FM" 3 "APS_LOW_POWER_REQ_SGK_POWER" 2 "APS_LOW_POWER_REQ_AP_MAILBOX" 1 "APS_LOW_POWER_REQ_AP_ATF" 0 "APS_LOW_POWER_REQ_NONE" ;
VAL_ 992 APSB_B_lowPowerRequest 5 "APS_LOW_POWER_COLD_RESET" 4 "APS_LOW_POWER_SOC_WARM_RESET" 3 "APS_LOW_POWER_AP_WARM_RESET" 2 "APS_LOW_POWER_OFF" 1 "APS_LOW_POWER_SUSPEND" 0 "APS_LOW_POWER_NONE" ;
VAL_ 992 APSB_B_lowPowerRequestor 10 "APS_LOW_POWER_REQ_COUNT" 9 "APS_LOW_POWER_REQ_SGK_PGOOD_IRQ" 8 "APS_LOW_POWER_REQ_SGK_CONSOLE" 7 "APS_LOW_POWER_REQ_SGK_SLEEP" 6 "APS_LOW_POWER_REQ_SGK_UDS" 5 "APS_LOW_POWER_REQ_SGK_BRIDGE" 4 "APS_LOW_POWER_REQ_SGK_FM" 3 "APS_LOW_POWER_REQ_SGK_POWER" 2 "APS_LOW_POWER_REQ_AP_MAILBOX" 1 "APS_LOW_POWER_REQ_AP_ATF" 0 "APS_LOW_POWER_REQ_NONE" ;
VAL_ 1864 APSB_primaryTurbo 2 "TURBO_UNKNOWN" 1 "TURBO_B" 0 "TURBO_A" ;
VAL_ 1864 APSB_A_arbState 7 "ARB_STATE_COUNT" 6 "ARB_STATE_UNKNOWN" 5 "ARB_STATE_MIA" 4 "ARB_STATE_FAULT" 3 "ARB_STATE_SECONDARY" 2 "ARB_STATE_PRIMARY" 1 "ARB_STATE_IDLE" 0 "ARB_STATE_INIT" ;
VAL_ 1864 APSB_A_powerState 28 "POWER_STATE_AP_FORCE_POWER_OFF" 27 "POWER_STATE_AP_WAIT_FOR_SHUTDOWN_ABORT" 26 "POWER_STATE_AP_IN_LINUX" 25 "POWER_STATE_AP_IDLE" 24 "POWER_STATE_VEH_BOOTING" 23 "POWER_STATE_UNKNOWN" 22 "POWER_STATE_MIA" 21 "POWER_STATE_FAULT" 20 "POWER_STATE_SOC_OFF_ABORT" 19 "POWER_STATE_SOC_OFF" 18 "POWER_STATE_SOC_OFF_READY" 17 "POWER_STATE_AP_SUSPENDED" 16 "POWER_STATE_AP_OFF_ABORT_WAIT_FOR_ACK" 15 "POWER_STATE_AP_OFF_ABORT" 14 "POWER_STATE_AP_OFF_READY_WAIT_FOR_RESPONSE" 13 "POWER_STATE_AP_OFF_READY_WAIT_FOR_ACK" 12 "POWER_STATE_AP_OFF_READY" 11 "POWER_STATE_AP_OFF_PREPARE" 10 "POWER_STATE_AP_WAIT_FOR_SHUTDOWN" 9 "POWER_STATE_AP_ON" 8 "POWER_STATE_AP_IN_COREBOOT" 7 "POWER_STATE_AP_BOOTING" 6 "POWER_STATE_AP_ON_READY_WAIT_FOR_RESPONSE" 5 "POWER_STATE_AP_ON_READY_WAIT_FOR_ACK" 4 "POWER_STATE_AP_ON_READY" 3 "POWER_STATE_AP_ON_PREPARE_WAIT_FOR_RESPONSE" 2 "POWER_STATE_AP_ON_PREPARE_WAIT_FOR_ACK" 1 "POWER_STATE_AP_ON_PREPARE" 0 "POWER_STATE_IDLE" ;
VAL_ 1864 APSB_A_sleepState 9 "SLEEP_STATE_COUNT" 8 "SLEEP_STATE_UNKNOWN" 7 "SLEEP_STATE_MIA" 6 "SLEEP_STATE_FAULT" 5 "SLEEP_STATE_ABORT" 4 "SLEEP_STATE_SLEEPING" 3 "SLEEP_STATE_GOING_TO_SLEEP" 2 "SLEEP_STATE_READY" 1 "SLEEP_STATE_WAIT_FOR_BUS_SILENCE" 0 "SLEEP_STATE_IDLE" ;
VAL_ 1864 APSB_A_resetState 5 "RESET_STATE_COUNT" 4 "RESET_STATE_UNKNOWN" 3 "RESET_STATE_MIA" 2 "RESET_STATE_FAULT" 1 "RESET_STATE_RESETTING" 0 "RESET_STATE_NOT_RESETTING" ;
VAL_ 1864 APSB_A_faultState 27 "FAULT_STATE_COUNT" 26 "FAULT_STATE_UNKNOWN" 25 "FAULT_STATE_MIA" 24 "FAULT_STATE_UNEXPECTED" 23 "FAULT_STATE_SCS" 22 "FAULT_STATE_SOFTWARE_FAULT" 21 "FAULT_STATE_TRIP1_FAULT" 20 "FAULT_STATE_TRIP0_FAULT" 19 "FAULT_STATE_WDT" 18 "FAULT_STATE_CPU_FAULT" 17 "FAULT_STATE_DROOP_TRIP" 16 "FAULT_STATE_DROOP_GPU" 15 "FAULT_STATE_DROOP_CPUCL2" 14 "FAULT_STATE_DROOP_CPUCL1" 13 "FAULT_STATE_DROOP_CPUCL0" 12 "FAULT_STATE_MIF_ECC_AP" 11 "FAULT_STATE_MIF7_DFI_ALERT" 10 "FAULT_STATE_MIF6_DFI_ALERT" 9 "FAULT_STATE_MIF5_DFI_ALERT" 8 "FAULT_STATE_MIF4_DFI_ALERT" 7 "FAULT_STATE_MIF3_DFI_ALERT" 6 "FAULT_STATE_MIF2_DFI_ALERT" 5 "FAULT_STATE_MIF1_DFI_ALERT" 4 "FAULT_STATE_MIF0_DFI_ALERT" 3 "FAULT_STATE_MIF_ECC_UNCORRECTED" 2 "FAULT_STATE_MIF_ECC_CORRECTED" 1 "FAULT_STATE_GIC" 0 "FAULT_STATE_NONE" ;
VAL_ 1864 APSB_secondaryTurbo 2 "TURBO_UNKNOWN" 1 "TURBO_B" 0 "TURBO_A" ;
VAL_ 1864 APSB_B_arbState 7 "ARB_STATE_COUNT" 6 "ARB_STATE_UNKNOWN" 5 "ARB_STATE_MIA" 4 "ARB_STATE_FAULT" 3 "ARB_STATE_SECONDARY" 2 "ARB_STATE_PRIMARY" 1 "ARB_STATE_IDLE" 0 "ARB_STATE_INIT" ;
VAL_ 1864 APSB_B_powerState 28 "POWER_STATE_AP_FORCE_POWER_OFF" 27 "POWER_STATE_AP_WAIT_FOR_SHUTDOWN_ABORT" 26 "POWER_STATE_AP_IN_LINUX" 25 "POWER_STATE_AP_IDLE" 24 "POWER_STATE_VEH_BOOTING" 23 "POWER_STATE_UNKNOWN" 22 "POWER_STATE_MIA" 21 "POWER_STATE_FAULT" 20 "POWER_STATE_SOC_OFF_ABORT" 19 "POWER_STATE_SOC_OFF" 18 "POWER_STATE_SOC_OFF_READY" 17 "POWER_STATE_AP_SUSPENDED" 16 "POWER_STATE_AP_OFF_ABORT_WAIT_FOR_ACK" 15 "POWER_STATE_AP_OFF_ABORT" 14 "POWER_STATE_AP_OFF_READY_WAIT_FOR_RESPONSE" 13 "POWER_STATE_AP_OFF_READY_WAIT_FOR_ACK" 12 "POWER_STATE_AP_OFF_READY" 11 "POWER_STATE_AP_OFF_PREPARE" 10 "POWER_STATE_AP_WAIT_FOR_SHUTDOWN" 9 "POWER_STATE_AP_ON" 8 "POWER_STATE_AP_IN_COREBOOT" 7 "POWER_STATE_AP_BOOTING" 6 "POWER_STATE_AP_ON_READY_WAIT_FOR_RESPONSE" 5 "POWER_STATE_AP_ON_READY_WAIT_FOR_ACK" 4 "POWER_STATE_AP_ON_READY" 3 "POWER_STATE_AP_ON_PREPARE_WAIT_FOR_RESPONSE" 2 "POWER_STATE_AP_ON_PREPARE_WAIT_FOR_ACK" 1 "POWER_STATE_AP_ON_PREPARE" 0 "POWER_STATE_IDLE" ;
VAL_ 1864 APSB_B_sleepState 9 "SLEEP_STATE_COUNT" 8 "SLEEP_STATE_UNKNOWN" 7 "SLEEP_STATE_MIA" 6 "SLEEP_STATE_FAULT" 5 "SLEEP_STATE_ABORT" 4 "SLEEP_STATE_SLEEPING" 3 "SLEEP_STATE_GOING_TO_SLEEP" 2 "SLEEP_STATE_READY" 1 "SLEEP_STATE_WAIT_FOR_BUS_SILENCE" 0 "SLEEP_STATE_IDLE" ;
VAL_ 1864 APSB_B_resetState 5 "RESET_STATE_COUNT" 4 "RESET_STATE_UNKNOWN" 3 "RESET_STATE_MIA" 2 "RESET_STATE_FAULT" 1 "RESET_STATE_RESETTING" 0 "RESET_STATE_NOT_RESETTING" ;
VAL_ 1864 APSB_B_faultState 27 "FAULT_STATE_COUNT" 26 "FAULT_STATE_UNKNOWN" 25 "FAULT_STATE_MIA" 24 "FAULT_STATE_UNEXPECTED" 23 "FAULT_STATE_SCS" 22 "FAULT_STATE_SOFTWARE_FAULT" 21 "FAULT_STATE_TRIP1_FAULT" 20 "FAULT_STATE_TRIP0_FAULT" 19 "FAULT_STATE_WDT" 18 "FAULT_STATE_CPU_FAULT" 17 "FAULT_STATE_DROOP_TRIP" 16 "FAULT_STATE_DROOP_GPU" 15 "FAULT_STATE_DROOP_CPUCL2" 14 "FAULT_STATE_DROOP_CPUCL1" 13 "FAULT_STATE_DROOP_CPUCL0" 12 "FAULT_STATE_MIF_ECC_AP" 11 "FAULT_STATE_MIF7_DFI_ALERT" 10 "FAULT_STATE_MIF6_DFI_ALERT" 9 "FAULT_STATE_MIF5_DFI_ALERT" 8 "FAULT_STATE_MIF4_DFI_ALERT" 7 "FAULT_STATE_MIF3_DFI_ALERT" 6 "FAULT_STATE_MIF2_DFI_ALERT" 5 "FAULT_STATE_MIF1_DFI_ALERT" 4 "FAULT_STATE_MIF0_DFI_ALERT" 3 "FAULT_STATE_MIF_ECC_UNCORRECTED" 2 "FAULT_STATE_MIF_ECC_CORRECTED" 1 "FAULT_STATE_GIC" 0 "FAULT_STATE_NONE" ;
VAL_ 1864 APSB_A_autosteerMonitorState 5 "AUTOSTEER_MONITOR_COUNT" 4 "AUTOSTEER_MONITOR_MIA" 3 "AUTOSTEER_MONITOR_TOI_TRIGGER" 2 "AUTOSTEER_MONITOR_WAIT_FOR_MIA" 1 "AUTOSTEER_MONITOR_ACTIVE" 0 "AUTOSTEER_MONITOR_IDLE" ;
VAL_ 1864 APSB_B_autosteerMonitorState 5 "AUTOSTEER_MONITOR_COUNT" 4 "AUTOSTEER_MONITOR_MIA" 3 "AUTOSTEER_MONITOR_TOI_TRIGGER" 2 "AUTOSTEER_MONITOR_WAIT_FOR_MIA" 1 "AUTOSTEER_MONITOR_ACTIVE" 0 "AUTOSTEER_MONITOR_IDLE" ;
VAL_ 1864 APSB_eplannerState 6 "APS_EPLANNER_NUM_STATES" 5 "APS_EPLANNER_STATE_EXECUTING_BOOT_FIXED_TRAJ" 4 "APS_EPLANNER_STATE_EXECUTING_FIXED_TRAJ" 3 "APS_EPLANNER_STATE_EXECUTING_PLAN_TRAJ" 2 "APS_EPLANNER_STATE_VALID_PLAN" 1 "APS_EPLANNER_STATE_READY" 0 "APS_EPLANNER_STATE_INIT" ;
VAL_ 971 APSB_appStatusMonitorState 7 "STATUS_MONITOR_NUM_STATES" 6 "STATUS_MONITOR_STATE_RECOVERY" 5 "STATUS_MONITOR_STATE_SHUTTING_DOWN" 4 "STATUS_MONITOR_STATE_CRITICAL" 3 "STATUS_MONITOR_STATE_NOMINAL" 2 "STATUS_MONITOR_STATE_INIT" 1 "STATUS_MONITOR_STATE_PWR_OFF" 0 "STATUS_MONITOR_STATE_UNKNOWN" ;
VAL_ 971 APSB_vehBehaviorState 8 "VEH_BEHAVIOR_NUM_STATES" 7 "VEH_BEHAVIOR_STATE_SYSTEM_FAULT" 6 "VEH_BEHAVIOR_STATE_APS_OVERRIDE" 5 "VEH_BEHAVIOR_STATE_APS_FAIL_SAFE" 4 "VEH_BEHAVIOR_STATE_APS_BRIDGE_APB" 3 "VEH_BEHAVIOR_STATE_APS_BRIDGE_APP" 2 "VEH_BEHAVIOR_STATE_APS_CONTROL" 1 "VEH_BEHAVIOR_STATE_APS_AVAILABLE" 0 "VEH_BEHAVIOR_STATE_UNKNOWN" ;
VAL_ 971 APSB_canMaster 3 "CAN_MASTER_SNA" 2 "CAN_MASTER_APB" 1 "CAN_MASTER_APP" 0 "CAN_MASTER_APS" ;
VAL_ 971 APSB_appGpioState 3 "AP_GPIO_STATE_HEALTHY" 2 "AP_GPIO_STATE_CRITICAL" 1 "AP_GPIO_STATE_DISABLED" 0 "AP_GPIO_STATE_PWR_DOWN_REBOOT" ;
VAL_ 971 APSB_eacInternalState 7 "APS_EAC_NUM_STATES" 6 "APS_EAC_STATE_LSS" 5 "APS_EAC_STATE_OVERRIDE" 4 "APS_EAC_STATE_INHIBIT" 3 "APS_EAC_STATE_AUTOPARK" 2 "APS_EAC_STATE_CONTINUOUS" 1 "APS_EAC_STATE_MOMENTARY" 0 "APS_EAC_STATE_INIT" ;
VAL_ 971 APSB_apbStatusMonitorState 7 "STATUS_MONITOR_NUM_STATES" 6 "STATUS_MONITOR_STATE_RECOVERY" 5 "STATUS_MONITOR_STATE_SHUTTING_DOWN" 4 "STATUS_MONITOR_STATE_CRITICAL" 3 "STATUS_MONITOR_STATE_NOMINAL" 2 "STATUS_MONITOR_STATE_INIT" 1 "STATUS_MONITOR_STATE_PWR_OFF" 0 "STATUS_MONITOR_STATE_UNKNOWN" ;
VAL_ 971 APSB_apbGpioState 3 "AP_GPIO_STATE_HEALTHY" 2 "AP_GPIO_STATE_CRITICAL" 1 "AP_GPIO_STATE_DISABLED" 0 "AP_GPIO_STATE_PWR_DOWN_REBOOT" ;
VAL_ 971 APSB_locLimitReason 7 "LOC_LIMITS_EXTENDED" 6 "LOC_MONITOR_UNAVAILABLE" 5 "NO_RADAR_TARGET" 4 "RADAR_NOT_HEALTHY" 3 "PRIMARY_AP_NOT_HEALTHY" 2 "ACC_AND_AEB_UNAVAILABLE" 1 "NOT_IN_DRIVE" 0 "NOMINAL_DEFAULT" ;
VAL_ 971 APSB_appPowerStateRequest 3 "AP_POWER_STATE_SLEEP" 2 "AP_POWER_STATE_SUSPEND" 1 "AP_POWER_STATE_SENTRY" 0 "AP_POWER_STATE_NOMINAL" ;
VAL_ 971 APSB_appPowerStateReason 12 "UI_SUMMON_STANDBY_MODE_ENABLED" 11 "SLEEP_REQUEST_RECVD" 10 "AP_POWER_REQUEST_OVERHEATED" 9 "LOADSHED_POWER_REQUEST_PENDING" 8 "VC_POWER_REQUEST" 7 "AP_POWER_REQUEST_OVERRIDE" 6 "AP_POWER_REQUEST_OVERHEATING" 5 "AP_POWER_REQUEST_HYSTERESIS" 4 "GTW_GOTO_FULL_POWER" 3 "AP_NOT_IN_PARK" 2 "AP_NM_REASON_SET" 1 "AP_WDOG_UNHEALTHY" 0 "UI_POWER_STATE_REQUEST" ;
VAL_ 971 APSB_apbPowerStateRequest 3 "AP_POWER_STATE_SLEEP" 2 "AP_POWER_STATE_SUSPEND" 1 "AP_POWER_STATE_SENTRY" 0 "AP_POWER_STATE_NOMINAL" ;
VAL_ 971 APSB_apbPowerStateReason 12 "UI_SUMMON_STANDBY_MODE_ENABLED" 11 "SLEEP_REQUEST_RECVD" 10 "AP_POWER_REQUEST_OVERHEATED" 9 "LOADSHED_POWER_REQUEST_PENDING" 8 "VC_POWER_REQUEST" 7 "AP_POWER_REQUEST_OVERRIDE" 6 "AP_POWER_REQUEST_OVERHEATING" 5 "AP_POWER_REQUEST_HYSTERESIS" 4 "GTW_GOTO_FULL_POWER" 3 "AP_NOT_IN_PARK" 2 "AP_NM_REASON_SET" 1 "AP_WDOG_UNHEALTHY" 0 "UI_POWER_STATE_REQUEST" ;
VAL_ 971 APSB_heaterStateDebug 7 "APS_HEATER_SNA" 4 "APS_HEATER_FAULT_SHORT" 3 "APS_HEATER_FAULT_OPEN" 2 "APS_HEATER_ON_NOT_HEATING" 1 "APS_HEATER_ON_HEATING" 0 "APS_HEATER_OFF" ;
VAL_ 971 APSB_gpsAntennaState 2 "GPS_ANTENNA_CONNECTED" 1 "GPS_ANTENNA_UNKNOWN" 0 "GPS_ANTENNA_DISCONNECTED" ;
VAL_ 971 APSB_arbState 7 "ARB_STATE_N_COUNT" 6 "ARB_STATE_N_UNKNOWN" 5 "ARB_STATE_N_MIA" 4 "ARB_STATE_N_FAULT" 3 "ARB_STATE_N_SECONDARY" 2 "ARB_STATE_N_PRIMARY" 1 "ARB_STATE_N_IDLE" 0 "ARB_STATE_N_INIT" ;
VAL_ 971 APSB_socPowerOperatingMode 2 "APS_DUAL_SOC" 1 "APS_SINGLE_SOC" 0 "APS_UNKNOWN" ;
